// *************************************************************************** *
// *                                                                           *
// *                      Mentor Graphics Corporation                          *
// *                          All rights reserved                              *
// *                                                                           *
// *************************************************************************** *
// *                                                                           *
// * Description:         CANDB File                                           *
// * Generated at:        2020-12-11 06:44:08                                  *
// * System:              SDB20019                                             *
// * Variant:             DC1E                                                 *
// * Network:             BodyExposedCAN                                       *
// *                                                                           *
// *************************************************************************** *
// *                                                                           *
// *             THIS CONFIGURATION MIGHT CONTAIN SOME ERRORS                  *
// *              IF THE INPUT MODEL WAS NOT PROPERLY FORMED!                  *
// *                    Do Not Use this File directly!                         *
// *                                                                           *
// *************************************************************************** *
VERSION "BodyExposedCAN"

NS_ :

BS_:

BU_:  CEM ETC HCML HCMR RCML RCMM RCMR

BO_ 1322 CemBodyCanExposedNMFr: 8 CEM
 SG_ PNC16_CEM : 16|1@0+ (1,0) [0|0] "" RCMR
 SG_ PNC17_CEM : 17|1@0+ (1,0) [0|0] "" RCMR
 SG_ PNC18_CEM : 18|1@0+ (1,0) [0|0] "" RCMR
 SG_ PNC19_CEM : 19|1@0+ (1,0) [0|0] "" RCMR
 SG_ PNC20_CEM : 20|1@0+ (1,0) [0|0] "" RCMR
 SG_ PNC21_CEM : 21|1@0+ (1,0) [0|0] "" RCMR
 SG_ PNC22_CEM : 22|1@0+ (1,0) [0|0] "" RCMR
 SG_ PNC23_CEM : 23|1@0+ (1,0) [0|0] "" RCMR
 SG_ PNC24_CEM : 24|1@0+ (1,0) [0|0] "" RCMR
 SG_ PNC25_CEM : 25|1@0+ (1,0) [0|0] "" RCMR
 SG_ PNC26_CEM : 26|1@0+ (1,0) [0|0] "" RCMR
 SG_ PNC27_CEM : 27|1@0+ (1,0) [0|0] "" RCMR
 SG_ PNC28_CEM : 28|1@0+ (1,0) [0|0] "" RCMR
 SG_ PNC29_CEM : 29|1@0+ (1,0) [0|0] "" RCMR
 SG_ PNC30_CEM : 30|1@0+ (1,0) [0|0] "" RCMR
 SG_ PNC31_CEM : 31|1@0+ (1,0) [0|0] "" RCMR
 SG_ PNC32_CEM : 32|1@0+ (1,0) [0|0] "" RCMR
 SG_ PNC33_CEM : 33|1@0+ (1,0) [0|0] "" RCMR
 SG_ PNC34_CEM : 34|1@0+ (1,0) [0|0] "" RCMR
 SG_ PNC35_CEM : 35|1@0+ (1,0) [0|0] "" RCMR
 SG_ PNC36_CEM : 36|1@0+ (1,0) [0|0] "" RCMR
 SG_ PNC37_CEM : 37|1@0+ (1,0) [0|0] "" RCMR
 SG_ PNC38_CEM : 38|1@0+ (1,0) [0|0] "" RCMR
 SG_ PNC39_CEM : 39|1@0+ (1,0) [0|0] "" RCMR
 SG_ NM_PNI_CEM : 14|1@0+ (1,0) [0|0] "" RCMR
 SG_ NM_AW_CEM : 12|1@0+ (1,0) [0|0] "" RCMR
 SG_ NM_CS_CEM : 11|1@0+ (1,0) [0|0] "" RCMR
 SG_ NM_RMR_CEM : 8|1@0+ (1,0) [0|0] "" RCMR
 SG_ NM_NodeID_CEM : 7|8@0+ (1,0) [0|0] "" RCMR

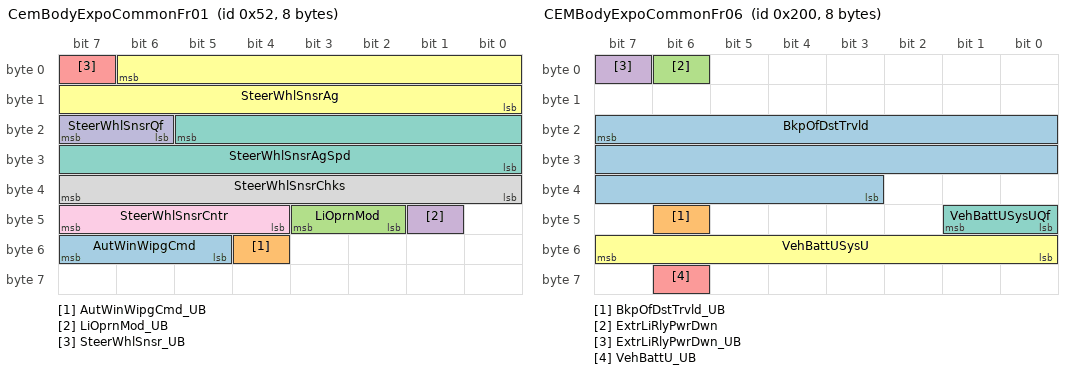
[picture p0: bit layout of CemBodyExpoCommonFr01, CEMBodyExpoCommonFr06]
BO_ 82 CemBodyExpoCommonFr01: 8 CEM
 SG_ AutWinWipgCmd : 55|3@0+ (1,0) [0|7] "" HCML,HCMR
 SG_ AutWinWipgCmd_UB : 52|1@0+ (1,0) [0|1] "" HCML,HCMR
 SG_ LiOprnMod : 43|2@0+ (1,0) [0|3] "" HCML,HCMR
 SG_ LiOprnMod_UB : 41|1@0+ (1,0) [0|1] "" HCML,HCMR
 SG_ SteerWhlSnsr_UB : 7|1@0+ (1,0) [0|1] "" HCML,HCMR
 SG_ SteerWhlSnsrAg : 6|15@0- (0.0009765625,0.0) [-14.5|14.5] "rad" HCML,HCMR
 SG_ SteerWhlSnsrAgSpd : 21|14@0- (0.0078125,0.0) [-50.0|50.0] "rad/s" HCML,HCMR
 SG_ SteerWhlSnsrChks : 39|8@0+ (1.0,0.0) [0.0|255.0] "Unitless" HCML,HCMR
 SG_ SteerWhlSnsrCntr : 47|4@0+ (1.0,0.0) [0.0|15.0] "Unitless" HCML,HCMR
 SG_ SteerWhlSnsrQf : 23|2@0+ (1,0) [0|3] "" HCML,HCMR

BO_ 768 CemBodyExpoCommonFr02: 8 CEM
 SG_ ActvnOfRvsg : 23|1@0+ (1,0) [0|1] "" RCML,RCMM,RCMR
 SG_ ActvnOfRvsg_UB : 22|1@0+ (1,0) [0|1] "" RCML,RCMM,RCMR
 SG_ YawRateReqdByDrvr : 7|16@0- (0.000244140625,0.0) [-5.0|5.0] "rad/s" HCML,HCMR
 SG_ YawRateReqdByDrvr_UB : 21|1@0+ (1,0) [0|1] "" HCML,HCMR

BO_ 80 CEMBodyExpoCommonFr04: 8 CEM
 SG_ VehSpdLgt_UB : 7|1@0+ (1,0) [0|1] "" HCML,HCMR,RCML,RCMM,RCMR
 SG_ VehSpdLgtA : 6|15@0+ (0.00391,0.0) [0.0|125.0027] "m/s" HCML,HCMR,RCML,RCMM,RCMR
 SG_ VehSpdLgtChks : 23|8@0+ (1.0,0.0) [0.0|255.0] "Unitless" HCML,HCMR,RCML,RCMM,RCMR
 SG_ VehSpdLgtCntr : 31|4@0+ (1.0,0.0) [0.0|15.0] "Unitless" HCML,HCMR,RCML,RCMM,RCMR
 SG_ VehSpdLgtQf : 27|2@0+ (1,0) [0|3] "" HCML,HCMR,RCML,RCMM,RCMR

BO_ 384 CemBodyExpoCommonFr05: 8 CEM
 SG_ VehCfgPrmBlkIDBytePosn1 : 7|8@0+ (1.0,0.0) [0.0|255.0] "Unitless" HCML,HCMR,RCML,RCMM,RCMR
 SG_ VehCfgPrmCCPBytePosn2 : 15|8@0+ (1.0,0.0) [0.0|255.0] "Unitless" HCML,HCMR,RCML,RCMM,RCMR
 SG_ VehCfgPrmCCPBytePosn3 : 23|8@0+ (1.0,0.0) [0.0|255.0] "Unitless" HCML,HCMR,RCML,RCMM,RCMR
 SG_ VehCfgPrmCCPBytePosn4 : 31|8@0+ (1.0,0.0) [0.0|255.0] "Unitless" HCML,HCMR,RCML,RCMM,RCMR
 SG_ VehCfgPrmCCPBytePosn5 : 39|8@0+ (1.0,0.0) [0.0|255.0] "Unitless" HCML,HCMR,RCML,RCMM,RCMR
 SG_ VehCfgPrmCCPBytePosn6 : 47|8@0+ (1.0,0.0) [0.0|255.0] "Unitless" HCML,HCMR,RCML,RCMM,RCMR
 SG_ VehCfgPrmCCPBytePosn7 : 55|8@0+ (1.0,0.0) [0.0|255.0] "Unitless" HCML,HCMR,RCML,RCMM,RCMR
 SG_ VehCfgPrmCCPBytePosn8 : 63|8@0+ (1.0,0.0) [0.0|255.0] "Unitless" HCML,HCMR,RCML,RCMM,RCMR

BO_ 512 CEMBodyExpoCommonFr06: 8 CEM
 SG_ BkpOfDstTrvld : 23|21@0+ (1.0,0.0) [0.0|2000000.0] "km" HCML,HCMR,RCML,RCMM,RCMR
 SG_ BkpOfDstTrvld_UB : 46|1@0+ (1,0) [0|1] "" HCML,HCMR,RCML,RCMM,RCMR
 SG_ ExtrLiRlyPwrDwn : 6|1@0+ (1,0) [0|1] "" HCML,HCMR
 SG_ ExtrLiRlyPwrDwn_UB : 7|1@0+ (1,0) [0|1] "" HCML,HCMR
 SG_ VehBattU_UB : 62|1@0+ (1,0) [0|1] "" HCML,HCMR,RCML,RCMM,RCMR
 SG_ VehBattUSysU : 55|8@0+ (0.1,0.0) [0.0|25.0] "Volt" HCML,HCMR,RCML,RCMM,RCMR
 SG_ VehBattUSysUQf : 41|2@0+ (1,0) [0|3] "" HCML,HCMR,RCML,RCMM,RCMR

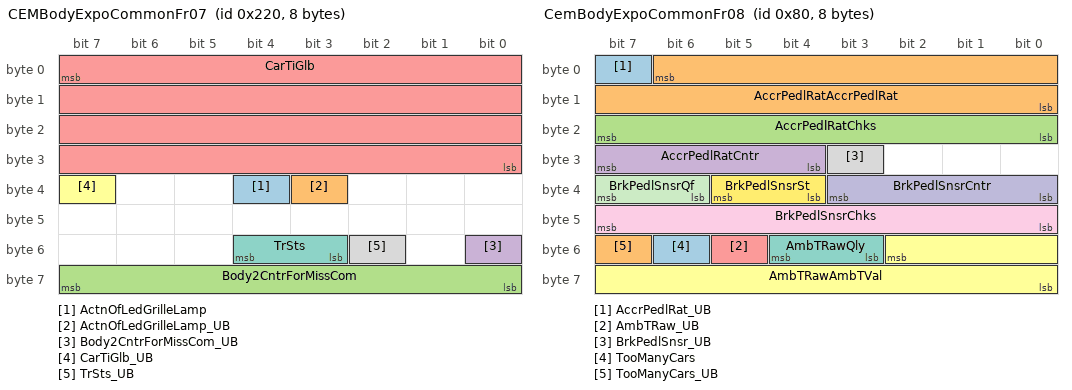
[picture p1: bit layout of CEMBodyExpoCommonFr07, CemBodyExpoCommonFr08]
BO_ 544 CEMBodyExpoCommonFr07: 8 CEM
 SG_ ActnOfLedGrilleLamp : 36|1@0+ (1,0) [0|1] "" HCML,HCMR
 SG_ ActnOfLedGrilleLamp_UB : 35|1@0+ (1,0) [0|1] "" HCML,HCMR
 SG_ Body2CntrForMissCom : 63|8@0+ (1.0,0.0) [0.0|255.0] "Unitless" HCML,HCMR
 SG_ Body2CntrForMissCom_UB : 48|1@0+ (1,0) [0|1] "" HCML,HCMR
 SG_ CarTiGlb : 7|32@0+ (0.1,0.0) [0.0|429496729.5] "s" HCML,HCMR,RCML,RCMM,RCMR
 SG_ CarTiGlb_UB : 39|1@0+ (1,0) [0|1] "" HCML,HCMR,RCML,RCMM,RCMR
 SG_ TrSts : 52|2@0+ (1,0) [0|3] "" RCML,RCMM,RCMR
 SG_ TrSts_UB : 50|1@0+ (1,0) [0|1] "" RCML,RCMM,RCMR

BO_ 128 CemBodyExpoCommonFr08: 8 CEM
 SG_ AccrPedlRat_UB : 7|1@0+ (1,0) [0|1] "" HCML,HCMR
 SG_ AccrPedlRatAccrPedlRat : 6|15@0+ (0.00390625,0.0) [0.0|100.0] "%" HCML,HCMR
 SG_ AccrPedlRatChks : 23|8@0+ (1.0,0.0) [0.0|255.0] "Unitless" HCML,HCMR
 SG_ AccrPedlRatCntr : 31|4@0+ (1.0,0.0) [0.0|15.0] "Unitless" HCML,HCMR
 SG_ AmbTRaw_UB : 53|1@0+ (1,0) [0|1] "" HCML,HCMR
 SG_ AmbTRawAmbTVal : 50|11@0+ (0.1,-70.0) [-70.0|134.70000000000002] "degC" HCML,HCMR
 SG_ AmbTRawQly : 52|2@0+ (1,0) [0|3] "" HCML,HCMR
 SG_ BrkPedlSnsr_UB : 27|1@0+ (1,0) [0|1] "" HCML,HCMR
 SG_ BrkPedlSnsrChks : 47|8@0+ (1.0,0.0) [0.0|255.0] "Unitless" HCML,HCMR
 SG_ BrkPedlSnsrCntr : 35|4@0+ (1.0,0.0) [0.0|15.0] "Unitless" HCML,HCMR
 SG_ BrkPedlSnsrQf : 39|2@0+ (1,0) [0|3] "" HCML,HCMR
 SG_ BrkPedlSnsrSt : 37|2@0+ (1,0) [0|3] "" HCML,HCMR
 SG_ TooManyCars : 54|1@0+ (1,0) [0|1] "" HCML,HCMR
 SG_ TooManyCars_UB : 55|1@0+ (1,0) [0|1] "" HCML,HCMR

BO_ 387 CemBodyExpoCommonFr09: 8 CEM
 SG_ VehCfgPrmExtBlkIDBytePosn1 : 7|8@0+ (1.0,0.0) [0.0|255.0] "Unitless" HCML,HCMR,RCML,RCMM,RCMR
 SG_ VehCfgPrmExtCCPBytePosn2 : 15|8@0+ (1.0,0.0) [0.0|255.0] "Unitless" HCML,HCMR,RCML,RCMM,RCMR
 SG_ VehCfgPrmExtCCPBytePosn3 : 23|8@0+ (1.0,0.0) [0.0|255.0] "Unitless" HCML,HCMR,RCML,RCMM,RCMR
 SG_ VehCfgPrmExtCCPBytePosn4 : 31|8@0+ (1.0,0.0) [0.0|255.0] "Unitless" HCML,HCMR,RCML,RCMM,RCMR
 SG_ VehCfgPrmExtCCPBytePosn5 : 39|8@0+ (1.0,0.0) [0.0|255.0] "Unitless" HCML,HCMR,RCML,RCMM,RCMR
 SG_ VehCfgPrmExtCCPBytePosn6 : 47|8@0+ (1.0,0.0) [0.0|255.0] "Unitless" HCML,HCMR,RCML,RCMM,RCMR
 SG_ VehCfgPrmExtCCPBytePosn7 : 55|8@0+ (1.0,0.0) [0.0|255.0] "Unitless" HCML,HCMR,RCML,RCMM,RCMR
 SG_ VehCfgPrmExtCCPBytePosn8 : 63|8@0+ (1.0,0.0) [0.0|255.0] "Unitless" HCML,HCMR,RCML,RCMM,RCMR

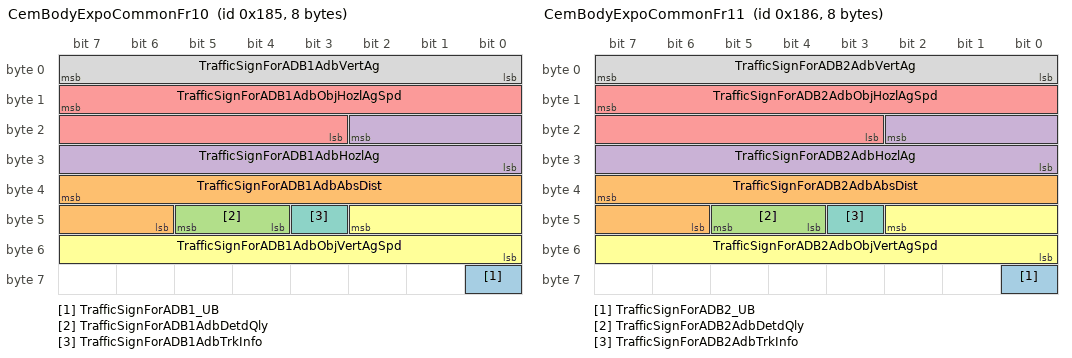
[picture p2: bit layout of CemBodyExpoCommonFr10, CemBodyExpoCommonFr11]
BO_ 389 CemBodyExpoCommonFr10: 8 CEM
 SG_ TrafficSignForADB1_UB : 56|1@0+ (1,0) [0|1] "" HCML,HCMR
 SG_ TrafficSignForADB1AdbAbsDist : 39|10@0+ (1.0,0.0) [0.0|1000.0] "m" HCML,HCMR
 SG_ TrafficSignForADB1AdbDetdQly : 45|2@0+ (1,0) [0|3] "" HCML,HCMR
 SG_ TrafficSignForADB1AdbHozlAg : 18|11@0+ (0.05,-40.0) [-40.0|40.0] "Deg" HCML,HCMR
 SG_ TrafficSignForADB1AdbObjHozlAgSpd : 15|13@0+ (0.05,-144.0) [-144.0|144.0] "DegPerSec" HCML,HCMR
 SG_ TrafficSignForADB1AdbObjVertAgSpd : 42|11@0+ (0.2,-144.0) [-144.0|144.0] "DegPerSec" HCML,HCMR
 SG_ TrafficSignForADB1AdbTrkInfo : 43|1@0+ (1,0) [0|1] "" HCML,HCMR
 SG_ TrafficSignForADB1AdbVertAg : 7|8@0+ (0.2,-15.0) [-15.0|15.0] "Deg" HCML,HCMR

BO_ 390 CemBodyExpoCommonFr11: 8 CEM
 SG_ TrafficSignForADB2_UB : 56|1@0+ (1,0) [0|1] "" HCML,HCMR
 SG_ TrafficSignForADB2AdbAbsDist : 39|10@0+ (1.0,0.0) [0.0|1000.0] "m" HCML,HCMR
 SG_ TrafficSignForADB2AdbDetdQly : 45|2@0+ (1,0) [0|3] "" HCML,HCMR
 SG_ TrafficSignForADB2AdbHozlAg : 18|11@0+ (0.05,-40.0) [-40.0|40.0] "Deg" HCML,HCMR
 SG_ TrafficSignForADB2AdbObjHozlAgSpd : 15|13@0+ (0.05,-144.0) [-144.0|144.0] "DegPerSec" HCML,HCMR
 SG_ TrafficSignForADB2AdbObjVertAgSpd : 42|11@0+ (0.2,-144.0) [-144.0|144.0] "DegPerSec" HCML,HCMR
 SG_ TrafficSignForADB2AdbTrkInfo : 43|1@0+ (1,0) [0|1] "" HCML,HCMR
 SG_ TrafficSignForADB2AdbVertAg : 7|8@0+ (0.2,-15.0) [-15.0|15.0] "Deg" HCML,HCMR

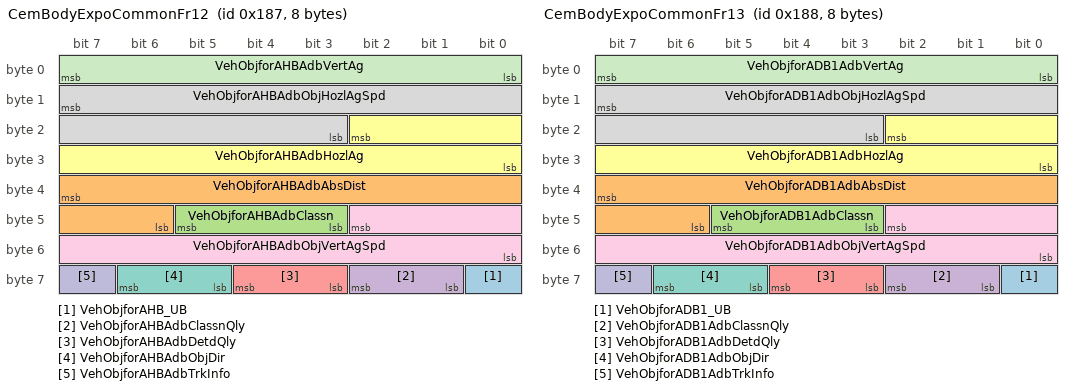
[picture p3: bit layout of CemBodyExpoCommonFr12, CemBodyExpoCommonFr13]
BO_ 391 CemBodyExpoCommonFr12: 8 CEM
 SG_ VehObjforAHB_UB : 56|1@0+ (1,0) [0|1] "" HCML,HCMR
 SG_ VehObjforAHBAdbAbsDist : 39|10@0+ (1.0,0.0) [0.0|1000.0] "m" HCML,HCMR
 SG_ VehObjforAHBAdbClassn : 45|3@0+ (1,0) [0|7] "" HCML,HCMR
 SG_ VehObjforAHBAdbClassnQly : 58|2@0+ (1,0) [0|3] "" HCML,HCMR
 SG_ VehObjforAHBAdbDetdQly : 60|2@0+ (1,0) [0|3] "" HCML,HCMR
 SG_ VehObjforAHBAdbHozlAg : 18|11@0+ (0.05,-40.0) [-40.0|40.0] "Deg" HCML,HCMR
 SG_ VehObjforAHBAdbObjDir : 62|2@0+ (1,0) [0|3] "" HCML,HCMR
 SG_ VehObjforAHBAdbObjHozlAgSpd : 15|13@0+ (0.05,-144.0) [-144.0|144.0] "DegPerSec" HCML,HCMR
 SG_ VehObjforAHBAdbObjVertAgSpd : 42|11@0+ (0.2,-144.0) [-144.0|144.0] "DegPerSec" HCML,HCMR
 SG_ VehObjforAHBAdbTrkInfo : 63|1@0+ (1,0) [0|1] "" HCML,HCMR
 SG_ VehObjforAHBAdbVertAg : 7|8@0+ (0.2,-15.0) [-15.0|15.0] "Deg" HCML,HCMR

BO_ 392 CemBodyExpoCommonFr13: 8 CEM
 SG_ VehObjforADB1_UB : 56|1@0+ (1,0) [0|1] "" HCML,HCMR
 SG_ VehObjforADB1AdbAbsDist : 39|10@0+ (1.0,0.0) [0.0|1000.0] "m" HCML,HCMR
 SG_ VehObjforADB1AdbClassn : 45|3@0+ (1,0) [0|7] "" HCML,HCMR
 SG_ VehObjforADB1AdbClassnQly : 58|2@0+ (1,0) [0|3] "" HCML,HCMR
 SG_ VehObjforADB1AdbDetdQly : 60|2@0+ (1,0) [0|3] "" HCML,HCMR
 SG_ VehObjforADB1AdbHozlAg : 18|11@0+ (0.05,-40.0) [-40.0|40.0] "Deg" HCML,HCMR
 SG_ VehObjforADB1AdbObjDir : 62|2@0+ (1,0) [0|3] "" HCML,HCMR
 SG_ VehObjforADB1AdbObjHozlAgSpd : 15|13@0+ (0.05,-144.0) [-144.0|144.0] "DegPerSec" HCML,HCMR
 SG_ VehObjforADB1AdbObjVertAgSpd : 42|11@0+ (0.2,-144.0) [-144.0|144.0] "DegPerSec" HCML,HCMR
 SG_ VehObjforADB1AdbTrkInfo : 63|1@0+ (1,0) [0|1] "" HCML,HCMR
 SG_ VehObjforADB1AdbVertAg : 7|8@0+ (0.2,-15.0) [-15.0|15.0] "Deg" HCML,HCMR

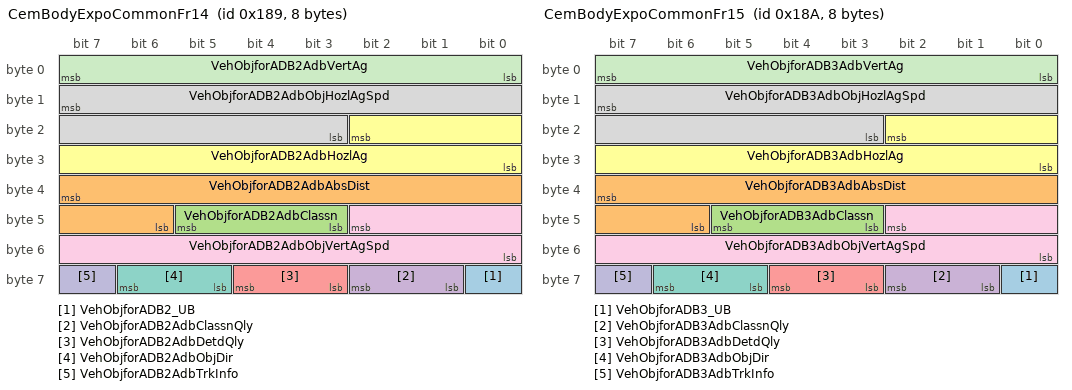
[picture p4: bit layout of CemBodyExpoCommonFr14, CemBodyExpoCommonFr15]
BO_ 393 CemBodyExpoCommonFr14: 8 CEM
 SG_ VehObjforADB2_UB : 56|1@0+ (1,0) [0|1] "" HCML,HCMR
 SG_ VehObjforADB2AdbAbsDist : 39|10@0+ (1.0,0.0) [0.0|1000.0] "m" HCML,HCMR
 SG_ VehObjforADB2AdbClassn : 45|3@0+ (1,0) [0|7] "" HCML,HCMR
 SG_ VehObjforADB2AdbClassnQly : 58|2@0+ (1,0) [0|3] "" HCML,HCMR
 SG_ VehObjforADB2AdbDetdQly : 60|2@0+ (1,0) [0|3] "" HCML,HCMR
 SG_ VehObjforADB2AdbHozlAg : 18|11@0+ (0.05,-40.0) [-40.0|40.0] "Deg" HCML,HCMR
 SG_ VehObjforADB2AdbObjDir : 62|2@0+ (1,0) [0|3] "" HCML,HCMR
 SG_ VehObjforADB2AdbObjHozlAgSpd : 15|13@0+ (0.05,-144.0) [-144.0|144.0] "DegPerSec" HCML,HCMR
 SG_ VehObjforADB2AdbObjVertAgSpd : 42|11@0+ (0.2,-144.0) [-144.0|144.0] "DegPerSec" HCML,HCMR
 SG_ VehObjforADB2AdbTrkInfo : 63|1@0+ (1,0) [0|1] "" HCML,HCMR
 SG_ VehObjforADB2AdbVertAg : 7|8@0+ (0.2,-15.0) [-15.0|15.0] "Deg" HCML,HCMR

BO_ 394 CemBodyExpoCommonFr15: 8 CEM
 SG_ VehObjforADB3_UB : 56|1@0+ (1,0) [0|1] "" HCML,HCMR
 SG_ VehObjforADB3AdbAbsDist : 39|10@0+ (1.0,0.0) [0.0|1000.0] "m" HCML,HCMR
 SG_ VehObjforADB3AdbClassn : 45|3@0+ (1,0) [0|7] "" HCML,HCMR
 SG_ VehObjforADB3AdbClassnQly : 58|2@0+ (1,0) [0|3] "" HCML,HCMR
 SG_ VehObjforADB3AdbDetdQly : 60|2@0+ (1,0) [0|3] "" HCML,HCMR
 SG_ VehObjforADB3AdbHozlAg : 18|11@0+ (0.05,-40.0) [-40.0|40.0] "Deg" HCML,HCMR
 SG_ VehObjforADB3AdbObjDir : 62|2@0+ (1,0) [0|3] "" HCML,HCMR
 SG_ VehObjforADB3AdbObjHozlAgSpd : 15|13@0+ (0.05,-144.0) [-144.0|144.0] "DegPerSec" HCML,HCMR
 SG_ VehObjforADB3AdbObjVertAgSpd : 42|11@0+ (0.2,-144.0) [-144.0|144.0] "DegPerSec" HCML,HCMR
 SG_ VehObjforADB3AdbTrkInfo : 63|1@0+ (1,0) [0|1] "" HCML,HCMR
 SG_ VehObjforADB3AdbVertAg : 7|8@0+ (0.2,-15.0) [-15.0|15.0] "Deg" HCML,HCMR

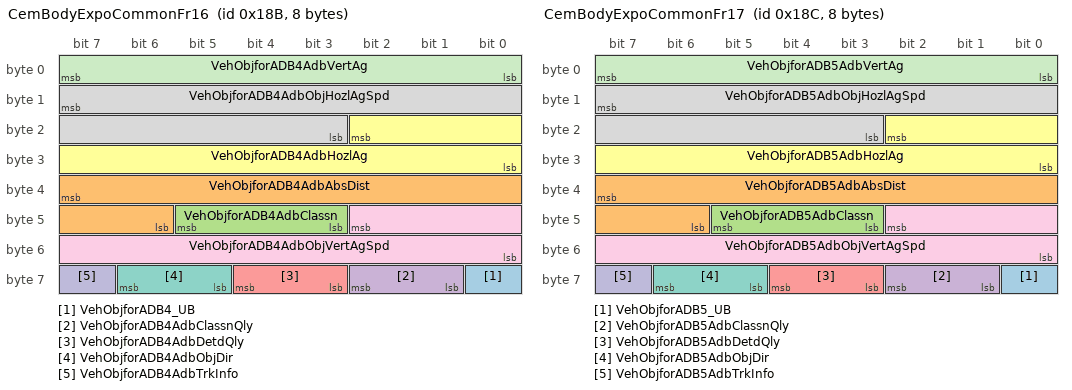
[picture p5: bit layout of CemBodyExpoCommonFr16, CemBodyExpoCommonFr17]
BO_ 395 CemBodyExpoCommonFr16: 8 CEM
 SG_ VehObjforADB4_UB : 56|1@0+ (1,0) [0|1] "" HCML,HCMR
 SG_ VehObjforADB4AdbAbsDist : 39|10@0+ (1.0,0.0) [0.0|1000.0] "m" HCML,HCMR
 SG_ VehObjforADB4AdbClassn : 45|3@0+ (1,0) [0|7] "" HCML,HCMR
 SG_ VehObjforADB4AdbClassnQly : 58|2@0+ (1,0) [0|3] "" HCML,HCMR
 SG_ VehObjforADB4AdbDetdQly : 60|2@0+ (1,0) [0|3] "" HCML,HCMR
 SG_ VehObjforADB4AdbHozlAg : 18|11@0+ (0.05,-40.0) [-40.0|40.0] "Deg" HCML,HCMR
 SG_ VehObjforADB4AdbObjDir : 62|2@0+ (1,0) [0|3] "" HCML,HCMR
 SG_ VehObjforADB4AdbObjHozlAgSpd : 15|13@0+ (0.05,-144.0) [-144.0|144.0] "DegPerSec" HCML,HCMR
 SG_ VehObjforADB4AdbObjVertAgSpd : 42|11@0+ (0.2,-144.0) [-144.0|144.0] "DegPerSec" HCML,HCMR
 SG_ VehObjforADB4AdbTrkInfo : 63|1@0+ (1,0) [0|1] "" HCML,HCMR
 SG_ VehObjforADB4AdbVertAg : 7|8@0+ (0.2,-15.0) [-15.0|15.0] "Deg" HCML,HCMR

BO_ 396 CemBodyExpoCommonFr17: 8 CEM
 SG_ VehObjforADB5_UB : 56|1@0+ (1,0) [0|1] "" HCML,HCMR
 SG_ VehObjforADB5AdbAbsDist : 39|10@0+ (1.0,0.0) [0.0|1000.0] "m" HCML,HCMR
 SG_ VehObjforADB5AdbClassn : 45|3@0+ (1,0) [0|7] "" HCML,HCMR
 SG_ VehObjforADB5AdbClassnQly : 58|2@0+ (1,0) [0|3] "" HCML,HCMR
 SG_ VehObjforADB5AdbDetdQly : 60|2@0+ (1,0) [0|3] "" HCML,HCMR
 SG_ VehObjforADB5AdbHozlAg : 18|11@0+ (0.05,-40.0) [-40.0|40.0] "Deg" HCML,HCMR
 SG_ VehObjforADB5AdbObjDir : 62|2@0+ (1,0) [0|3] "" HCML,HCMR
 SG_ VehObjforADB5AdbObjHozlAgSpd : 15|13@0+ (0.05,-144.0) [-144.0|144.0] "DegPerSec" HCML,HCMR
 SG_ VehObjforADB5AdbObjVertAgSpd : 42|11@0+ (0.2,-144.0) [-144.0|144.0] "DegPerSec" HCML,HCMR
 SG_ VehObjforADB5AdbTrkInfo : 63|1@0+ (1,0) [0|1] "" HCML,HCMR
 SG_ VehObjforADB5AdbVertAg : 7|8@0+ (0.2,-15.0) [-15.0|15.0] "Deg" HCML,HCMR

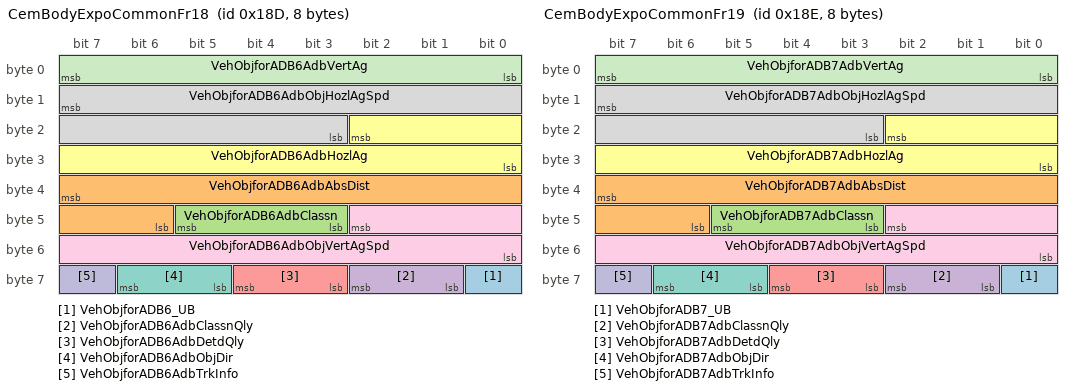
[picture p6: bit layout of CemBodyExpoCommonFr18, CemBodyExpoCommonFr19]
BO_ 397 CemBodyExpoCommonFr18: 8 CEM
 SG_ VehObjforADB6_UB : 56|1@0+ (1,0) [0|1] "" HCML,HCMR
 SG_ VehObjforADB6AdbAbsDist : 39|10@0+ (1.0,0.0) [0.0|1000.0] "m" HCML,HCMR
 SG_ VehObjforADB6AdbClassn : 45|3@0+ (1,0) [0|7] "" HCML,HCMR
 SG_ VehObjforADB6AdbClassnQly : 58|2@0+ (1,0) [0|3] "" HCML,HCMR
 SG_ VehObjforADB6AdbDetdQly : 60|2@0+ (1,0) [0|3] "" HCML,HCMR
 SG_ VehObjforADB6AdbHozlAg : 18|11@0+ (0.05,-40.0) [-40.0|40.0] "Deg" HCML,HCMR
 SG_ VehObjforADB6AdbObjDir : 62|2@0+ (1,0) [0|3] "" HCML,HCMR
 SG_ VehObjforADB6AdbObjHozlAgSpd : 15|13@0+ (0.05,-144.0) [-144.0|144.0] "DegPerSec" HCML,HCMR
 SG_ VehObjforADB6AdbObjVertAgSpd : 42|11@0+ (0.2,-144.0) [-144.0|144.0] "DegPerSec" HCML,HCMR
 SG_ VehObjforADB6AdbTrkInfo : 63|1@0+ (1,0) [0|1] "" HCML,HCMR
 SG_ VehObjforADB6AdbVertAg : 7|8@0+ (0.2,-15.0) [-15.0|15.0] "Deg" HCML,HCMR

BO_ 398 CemBodyExpoCommonFr19: 8 CEM
 SG_ VehObjforADB7_UB : 56|1@0+ (1,0) [0|1] "" HCML,HCMR
 SG_ VehObjforADB7AdbAbsDist : 39|10@0+ (1.0,0.0) [0.0|1000.0] "m" HCML,HCMR
 SG_ VehObjforADB7AdbClassn : 45|3@0+ (1,0) [0|7] "" HCML,HCMR
 SG_ VehObjforADB7AdbClassnQly : 58|2@0+ (1,0) [0|3] "" HCML,HCMR
 SG_ VehObjforADB7AdbDetdQly : 60|2@0+ (1,0) [0|3] "" HCML,HCMR
 SG_ VehObjforADB7AdbHozlAg : 18|11@0+ (0.05,-40.0) [-40.0|40.0] "Deg" HCML,HCMR
 SG_ VehObjforADB7AdbObjDir : 62|2@0+ (1,0) [0|3] "" HCML,HCMR
 SG_ VehObjforADB7AdbObjHozlAgSpd : 15|13@0+ (0.05,-144.0) [-144.0|144.0] "DegPerSec" HCML,HCMR
 SG_ VehObjforADB7AdbObjVertAgSpd : 42|11@0+ (0.2,-144.0) [-144.0|144.0] "DegPerSec" HCML,HCMR
 SG_ VehObjforADB7AdbTrkInfo : 63|1@0+ (1,0) [0|1] "" HCML,HCMR
 SG_ VehObjforADB7AdbVertAg : 7|8@0+ (0.2,-15.0) [-15.0|15.0] "Deg" HCML,HCMR

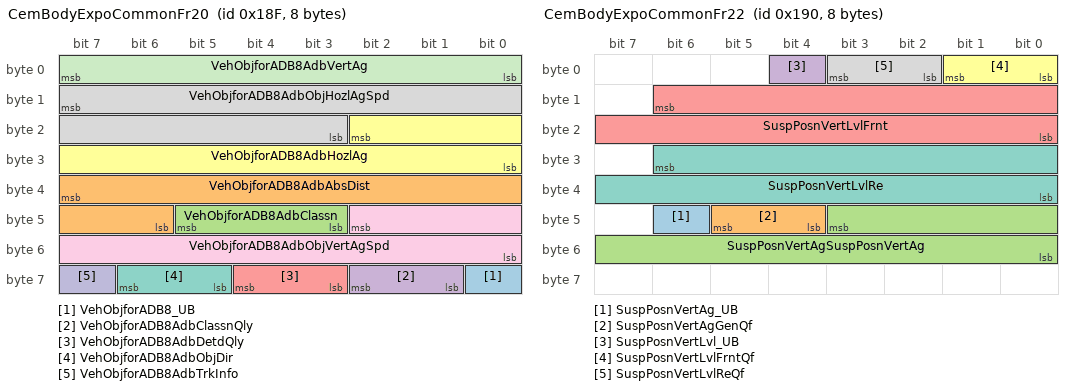
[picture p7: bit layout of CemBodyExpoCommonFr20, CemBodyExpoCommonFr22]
BO_ 399 CemBodyExpoCommonFr20: 8 CEM
 SG_ VehObjforADB8_UB : 56|1@0+ (1,0) [0|1] "" HCML,HCMR
 SG_ VehObjforADB8AdbAbsDist : 39|10@0+ (1.0,0.0) [0.0|1000.0] "m" HCML,HCMR
 SG_ VehObjforADB8AdbClassn : 45|3@0+ (1,0) [0|7] "" HCML,HCMR
 SG_ VehObjforADB8AdbClassnQly : 58|2@0+ (1,0) [0|3] "" HCML,HCMR
 SG_ VehObjforADB8AdbDetdQly : 60|2@0+ (1,0) [0|3] "" HCML,HCMR
 SG_ VehObjforADB8AdbHozlAg : 18|11@0+ (0.05,-40.0) [-40.0|40.0] "Deg" HCML,HCMR
 SG_ VehObjforADB8AdbObjDir : 62|2@0+ (1,0) [0|3] "" HCML,HCMR
 SG_ VehObjforADB8AdbObjHozlAgSpd : 15|13@0+ (0.05,-144.0) [-144.0|144.0] "DegPerSec" HCML,HCMR
 SG_ VehObjforADB8AdbObjVertAgSpd : 42|11@0+ (0.2,-144.0) [-144.0|144.0] "DegPerSec" HCML,HCMR
 SG_ VehObjforADB8AdbTrkInfo : 63|1@0+ (1,0) [0|1] "" HCML,HCMR
 SG_ VehObjforADB8AdbVertAg : 7|8@0+ (0.2,-15.0) [-15.0|15.0] "Deg" HCML,HCMR

BO_ 64 CemBodyExpoCommonFr21: 8 CEM
 SG_ CameraStsforAHBC : 62|2@0+ (1,0) [0|3] "" HCML,HCMR
 SG_ CameraStsforAHBC_UB : 60|1@0+ (1,0) [0|1] "" HCML,HCMR
 SG_ RainLi : 47|1@0+ (1,0) [0|1] "" HCML,HCMR
 SG_ RainLi_UB : 63|1@0+ (1,0) [0|1] "" HCML,HCMR
 SG_ VehModMngtGlbSafe1_UB : 32|1@0+ (1,0) [0|1] "" HCML,HCMR,RCML,RCMM,RCMR
 SG_ VehModMngtGlbSafe1CarModSts1 : 39|3@0+ (1,0) [0|7] "" HCML,HCMR,RCML,RCMM,RCMR
 SG_ VehModMngtGlbSafe1CarModSubtypWdCarModSubtyp : 35|3@0+ (1.0,0.0) [0.0|7.0] "Unitless" HCML,HCMR,RCML,RCMM,RCMR
 SG_ VehModMngtGlbSafe1Chks : 7|8@0+ (1.0,0.0) [0.0|255.0] "Unitless" HCML,HCMR,RCML,RCMM,RCMR
 SG_ VehModMngtGlbSafe1Cntr : 15|4@0+ (1.0,0.0) [0.0|15.0] "Unitless" HCML,HCMR,RCML,RCMM,RCMR
 SG_ VehModMngtGlbSafe1EgyLvlElecMai : 27|4@0+ (1.0,0.0) [0.0|15.0] "Unitless" HCML,HCMR,RCML,RCMM,RCMR
 SG_ VehModMngtGlbSafe1EgyLvlElecSubtyp : 31|4@0+ (1.0,0.0) [0.0|15.0] "Unitless" HCML,HCMR,RCML,RCMM,RCMR
 SG_ VehModMngtGlbSafe1FltEgyCnsWdSts : 36|1@0+ (1,0) [0|1] "" HCML,HCMR,RCML,RCMM,RCMR
 SG_ VehModMngtGlbSafe1PwrLvlElecMai : 19|4@0+ (1.0,0.0) [0.0|15.0] "Unitless" HCML,HCMR,RCML,RCMM,RCMR
 SG_ VehModMngtGlbSafe1PwrLvlElecSubtyp : 23|4@0+ (1.0,0.0) [0.0|15.0] "Unitless" HCML,HCMR,RCML,RCMM,RCMR
 SG_ VehModMngtGlbSafe1UsgModSts : 11|4@0+ (1,0) [0|15] "" HCML,HCMR,RCML,RCMM,RCMR
 SG_ WipgAutFrntMod : 59|2@0+ (1,0) [0|3] "" HCML,HCMR
 SG_ WipgAutFrntMod_UB : 57|1@0+ (1,0) [0|1] "" HCML,HCMR

BO_ 400 CemBodyExpoCommonFr22: 8 CEM
 SG_ SuspPosnVertAg_UB : 46|1@0+ (1,0) [0|1] "" HCML,HCMR
 SG_ SuspPosnVertAgGenQf : 45|2@0+ (1,0) [0|3] "" HCML,HCMR
 SG_ SuspPosnVertAgSuspPosnVertAg : 43|12@0- (0.000127894181,0.0) [-0.26167149432599995|0.26179938850699996] "rad" HCML,HCMR
 SG_ SuspPosnVertLvl_UB : 4|1@0+ (1,0) [0|1] "" HCML,HCMR
 SG_ SuspPosnVertLvlFrnt : 14|15@0- (0.000062,0.0) [-0.999998|1.00006] "m" HCML,HCMR
 SG_ SuspPosnVertLvlFrntQf : 1|2@0+ (1,0) [0|3] "" HCML,HCMR
 SG_ SuspPosnVertLvlRe : 30|15@0- (0.000062,0.0) [-0.999998|1.00006] "m" HCML,HCMR
 SG_ SuspPosnVertLvlReQf : 3|2@0+ (1,0) [0|3] "" HCML,HCMR

BO_ 1432 CemBodyExpoDevDiagFr01: 8 CEM
 SG_ CEMdevelpsignalgrouprespFunctiondevpsignalgroup1 : 7|8@0+ (1.0,0.0) [0.0|255.0] "Unitless" ETC
 SG_ CEMdevelpsignalgrouprespFunctiondevpsignalgroup2 : 15|8@0+ (1.0,0.0) [0.0|255.0] "Unitless" ETC
 SG_ CEMdevelpsignalgrouprespFunctiondevpsignalgroup3 : 23|8@0+ (1.0,0.0) [0.0|255.0] "Unitless" ETC
 SG_ CEMdevelpsignalgrouprespFunctiondevpsignalgroup4 : 31|8@0+ (1.0,0.0) [0.0|255.0] "Unitless" ETC
 SG_ CEMdevelpsignalgrouprespFunctiondevpsignalgroup5 : 39|8@0+ (1.0,0.0) [0.0|255.0] "Unitless" ETC
 SG_ CEMdevelpsignalgrouprespFunctiondevpsignalgroup6 : 47|8@0+ (1.0,0.0) [0.0|255.0] "Unitless" ETC
 SG_ CEMdevelpsignalgrouprespFunctiondevpsignalgroup7 : 55|8@0+ (1.0,0.0) [0.0|255.0] "Unitless" ETC
 SG_ CEMdevelpsignalgrouprespFunctiondevpsignalgroup8 : 63|8@0+ (1.0,0.0) [0.0|255.0] "Unitless" ETC

BO_ 1431 CemBodyExpoDevFr02: 8 CEM
 SG_ CEMdevelpsignalgroupcheckFunctiondevpsignalgroup1 : 7|8@0+ (1.0,0.0) [0.0|255.0] "Unitless" ETC
 SG_ CEMdevelpsignalgroupcheckFunctiondevpsignalgroup2 : 15|8@0+ (1.0,0.0) [0.0|255.0] "Unitless" ETC
 SG_ CEMdevelpsignalgroupcheckFunctiondevpsignalgroup3 : 23|8@0+ (1.0,0.0) [0.0|255.0] "Unitless" ETC
 SG_ CEMdevelpsignalgroupcheckFunctiondevpsignalgroup4 : 31|8@0+ (1.0,0.0) [0.0|255.0] "Unitless" ETC
 SG_ CEMdevelpsignalgroupcheckFunctiondevpsignalgroup5 : 39|8@0+ (1.0,0.0) [0.0|255.0] "Unitless" ETC
 SG_ CEMdevelpsignalgroupcheckFunctiondevpsignalgroup6 : 47|8@0+ (1.0,0.0) [0.0|255.0] "Unitless" ETC
 SG_ CEMdevelpsignalgroupcheckFunctiondevpsignalgroup7 : 55|8@0+ (1.0,0.0) [0.0|255.0] "Unitless" ETC
 SG_ CEMdevelpsignalgroupcheckFunctiondevpsignalgroup8 : 63|8@0+ (1.0,0.0) [0.0|255.0] "Unitless" ETC

BO_ 28 CemBodyExpoFr01: 8 CEM
 SG_ ExtrLiShowActvnReq : 44|1@0+ (1,0) [0|1] "" HCML,HCMR,RCML,RCMM,RCMR
 SG_ ExtrLiShowActvnReq_UB : 43|1@0+ (1,0) [0|1] "" HCML,HCMR,RCML,RCMM,RCMR
 SG_ ExtrLiShowFileTxReq : 42|1@0+ (1,0) [0|1] "" HCML,HCMR,RCML,RCMM,RCMR
 SG_ ExtrLiShowFileTxReq_UB : 41|1@0+ (1,0) [0|1] "" HCML,HCMR,RCML,RCMM,RCMR

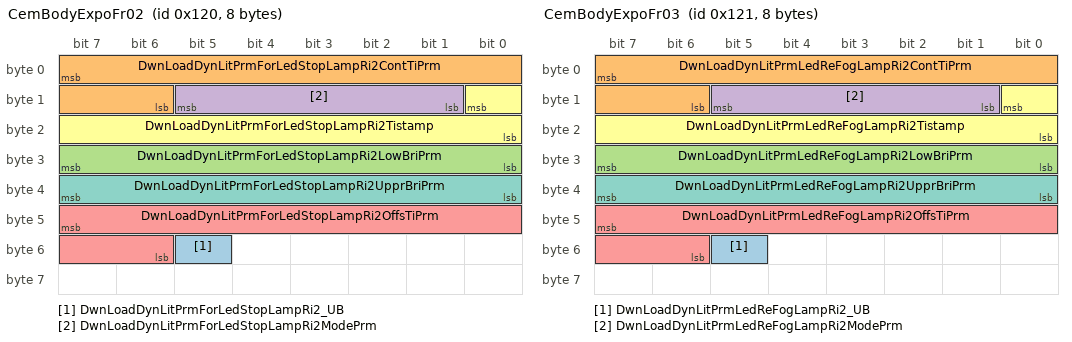
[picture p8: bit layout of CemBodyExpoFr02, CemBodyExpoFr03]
BO_ 288 CemBodyExpoFr02: 8 CEM
 SG_ DwnLoadDynLitPrmForLedStopLampRi2_UB : 53|1@0+ (1,0) [0|1] "" RCMM
 SG_ DwnLoadDynLitPrmForLedStopLampRi2ContTiPrm : 7|10@0+ (1.0,0.0) [0.0|1000.0] "Milliseconds" RCMM
 SG_ DwnLoadDynLitPrmForLedStopLampRi2LowBriPrm : 31|8@0+ (1.0,0.0) [0.0|100.0] "%" RCMM
 SG_ DwnLoadDynLitPrmForLedStopLampRi2ModePrm : 13|5@0+ (1,0) [0|31] "" RCMM
 SG_ DwnLoadDynLitPrmForLedStopLampRi2OffsTiPrm : 47|10@0+ (1.0,0.0) [0.0|1000.0] "Milliseconds" RCMM
 SG_ DwnLoadDynLitPrmForLedStopLampRi2Tistamp : 8|9@0+ (1.0,0.0) [0.0|511.0] "Unitless" RCMM
 SG_ DwnLoadDynLitPrmForLedStopLampRi2UpprBriPrm : 39|8@0+ (1.0,0.0) [0.0|100.0] "%" RCMM

BO_ 289 CemBodyExpoFr03: 8 CEM
 SG_ DwnLoadDynLitPrmLedReFogLampRi2_UB : 53|1@0+ (1,0) [0|1] "" RCMM
 SG_ DwnLoadDynLitPrmLedReFogLampRi2ContTiPrm : 7|10@0+ (1.0,0.0) [0.0|1000.0] "Milliseconds" RCMM
 SG_ DwnLoadDynLitPrmLedReFogLampRi2LowBriPrm : 31|8@0+ (1.0,0.0) [0.0|100.0] "%" RCMM
 SG_ DwnLoadDynLitPrmLedReFogLampRi2ModePrm : 13|5@0+ (1,0) [0|31] "" RCMM
 SG_ DwnLoadDynLitPrmLedReFogLampRi2OffsTiPrm : 47|10@0+ (1.0,0.0) [0.0|1000.0] "Milliseconds" RCMM
 SG_ DwnLoadDynLitPrmLedReFogLampRi2Tistamp : 8|9@0+ (1.0,0.0) [0.0|511.0] "Unitless" RCMM
 SG_ DwnLoadDynLitPrmLedReFogLampRi2UpprBriPrm : 39|8@0+ (1.0,0.0) [0.0|100.0] "%" RCMM

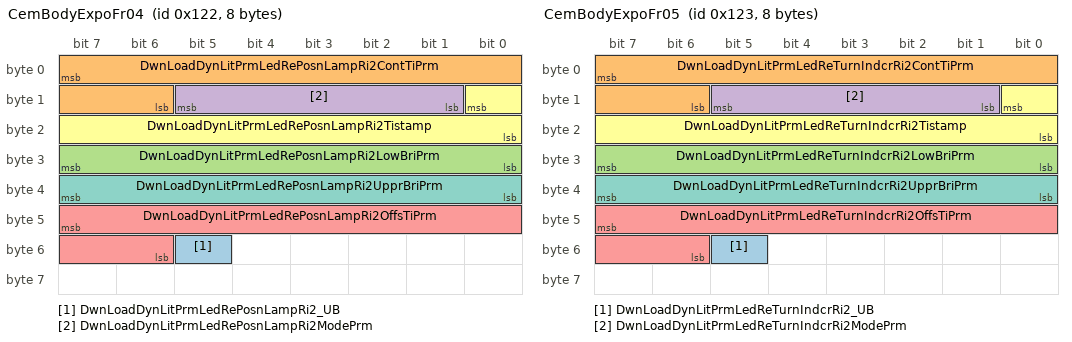
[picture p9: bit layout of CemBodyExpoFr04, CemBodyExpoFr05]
BO_ 290 CemBodyExpoFr04: 8 CEM
 SG_ DwnLoadDynLitPrmLedRePosnLampRi2_UB : 53|1@0+ (1,0) [0|1] "" RCMM
 SG_ DwnLoadDynLitPrmLedRePosnLampRi2ContTiPrm : 7|10@0+ (1.0,0.0) [0.0|1000.0] "Milliseconds" RCMM
 SG_ DwnLoadDynLitPrmLedRePosnLampRi2LowBriPrm : 31|8@0+ (1.0,0.0) [0.0|100.0] "%" RCMM
 SG_ DwnLoadDynLitPrmLedRePosnLampRi2ModePrm : 13|5@0+ (1,0) [0|31] "" RCMM
 SG_ DwnLoadDynLitPrmLedRePosnLampRi2OffsTiPrm : 47|10@0+ (1.0,0.0) [0.0|1000.0] "Milliseconds" RCMM
 SG_ DwnLoadDynLitPrmLedRePosnLampRi2Tistamp : 8|9@0+ (1.0,0.0) [0.0|511.0] "Unitless" RCMM
 SG_ DwnLoadDynLitPrmLedRePosnLampRi2UpprBriPrm : 39|8@0+ (1.0,0.0) [0.0|100.0] "%" RCMM

BO_ 291 CemBodyExpoFr05: 8 CEM
 SG_ DwnLoadDynLitPrmLedReTurnIndcrRi2_UB : 53|1@0+ (1,0) [0|1] "" RCMM
 SG_ DwnLoadDynLitPrmLedReTurnIndcrRi2ContTiPrm : 7|10@0+ (1.0,0.0) [0.0|1000.0] "Milliseconds" RCMM
 SG_ DwnLoadDynLitPrmLedReTurnIndcrRi2LowBriPrm : 31|8@0+ (1.0,0.0) [0.0|100.0] "%" RCMM
 SG_ DwnLoadDynLitPrmLedReTurnIndcrRi2ModePrm : 13|5@0+ (1,0) [0|31] "" RCMM
 SG_ DwnLoadDynLitPrmLedReTurnIndcrRi2OffsTiPrm : 47|10@0+ (1.0,0.0) [0.0|1000.0] "Milliseconds" RCMM
 SG_ DwnLoadDynLitPrmLedReTurnIndcrRi2Tistamp : 8|9@0+ (1.0,0.0) [0.0|511.0] "Unitless" RCMM
 SG_ DwnLoadDynLitPrmLedReTurnIndcrRi2UpprBriPrm : 39|8@0+ (1.0,0.0) [0.0|100.0] "%" RCMM

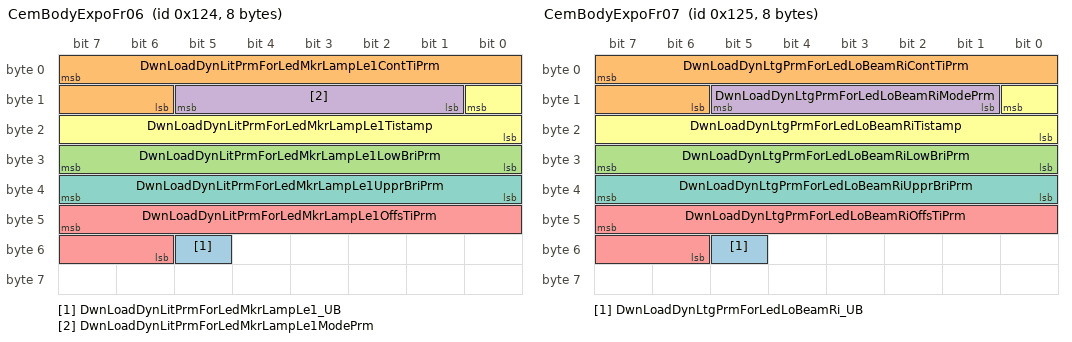
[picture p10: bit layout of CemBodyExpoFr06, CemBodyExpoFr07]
BO_ 292 CemBodyExpoFr06: 8 CEM
 SG_ DwnLoadDynLitPrmForLedMkrLampLe1_UB : 53|1@0+ (1,0) [0|1] "" RCML
 SG_ DwnLoadDynLitPrmForLedMkrLampLe1ContTiPrm : 7|10@0+ (1.0,0.0) [0.0|1000.0] "Milliseconds" RCML
 SG_ DwnLoadDynLitPrmForLedMkrLampLe1LowBriPrm : 31|8@0+ (1.0,0.0) [0.0|100.0] "%" RCML
 SG_ DwnLoadDynLitPrmForLedMkrLampLe1ModePrm : 13|5@0+ (1,0) [0|31] "" RCML
 SG_ DwnLoadDynLitPrmForLedMkrLampLe1OffsTiPrm : 47|10@0+ (1.0,0.0) [0.0|1000.0] "Milliseconds" RCML
 SG_ DwnLoadDynLitPrmForLedMkrLampLe1Tistamp : 8|9@0+ (1.0,0.0) [0.0|511.0] "Unitless" RCML
 SG_ DwnLoadDynLitPrmForLedMkrLampLe1UpprBriPrm : 39|8@0+ (1.0,0.0) [0.0|100.0] "%" RCML

BO_ 293 CemBodyExpoFr07: 8 CEM
 SG_ DwnLoadDynLtgPrmForLedLoBeamRi_UB : 53|1@0+ (1,0) [0|1] "" HCMR
 SG_ DwnLoadDynLtgPrmForLedLoBeamRiContTiPrm : 7|10@0+ (1.0,0.0) [0.0|1000.0] "Milliseconds" HCMR
 SG_ DwnLoadDynLtgPrmForLedLoBeamRiLowBriPrm : 31|8@0+ (1.0,0.0) [0.0|100.0] "%" HCMR
 SG_ DwnLoadDynLtgPrmForLedLoBeamRiModePrm : 13|5@0+ (1,0) [0|31] "" HCMR
 SG_ DwnLoadDynLtgPrmForLedLoBeamRiOffsTiPrm : 47|10@0+ (1.0,0.0) [0.0|1000.0] "Milliseconds" HCMR
 SG_ DwnLoadDynLtgPrmForLedLoBeamRiTistamp : 8|9@0+ (1.0,0.0) [0.0|511.0] "Unitless" HCMR
 SG_ DwnLoadDynLtgPrmForLedLoBeamRiUpprBriPrm : 39|8@0+ (1.0,0.0) [0.0|100.0] "%" HCMR

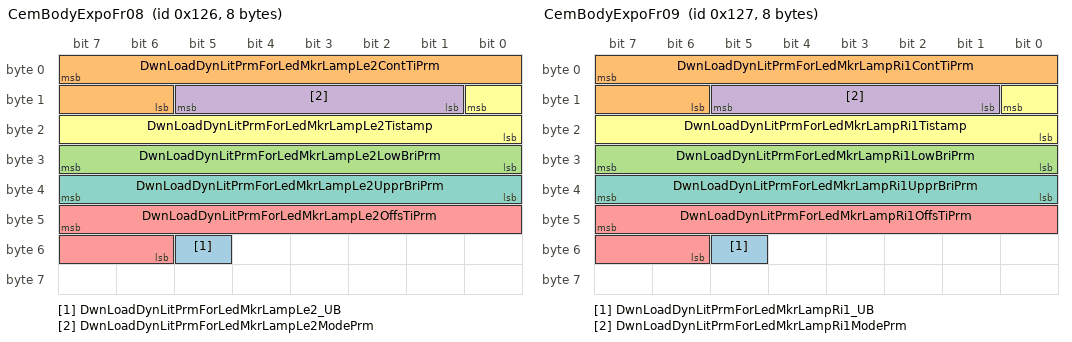
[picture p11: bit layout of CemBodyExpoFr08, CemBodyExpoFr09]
BO_ 294 CemBodyExpoFr08: 8 CEM
 SG_ DwnLoadDynLitPrmForLedMkrLampLe2_UB : 53|1@0+ (1,0) [0|1] "" RCMM
 SG_ DwnLoadDynLitPrmForLedMkrLampLe2ContTiPrm : 7|10@0+ (1.0,0.0) [0.0|1000.0] "Milliseconds" RCMM
 SG_ DwnLoadDynLitPrmForLedMkrLampLe2LowBriPrm : 31|8@0+ (1.0,0.0) [0.0|100.0] "%" RCMM
 SG_ DwnLoadDynLitPrmForLedMkrLampLe2ModePrm : 13|5@0+ (1,0) [0|31] "" RCMM
 SG_ DwnLoadDynLitPrmForLedMkrLampLe2OffsTiPrm : 47|10@0+ (1.0,0.0) [0.0|1000.0] "Milliseconds" RCMM
 SG_ DwnLoadDynLitPrmForLedMkrLampLe2Tistamp : 8|9@0+ (1.0,0.0) [0.0|511.0] "Unitless" RCMM
 SG_ DwnLoadDynLitPrmForLedMkrLampLe2UpprBriPrm : 39|8@0+ (1.0,0.0) [0.0|100.0] "%" RCMM

BO_ 295 CemBodyExpoFr09: 8 CEM
 SG_ DwnLoadDynLitPrmForLedMkrLampRi1_UB : 53|1@0+ (1,0) [0|1] "" RCMR
 SG_ DwnLoadDynLitPrmForLedMkrLampRi1ContTiPrm : 7|10@0+ (1.0,0.0) [0.0|1000.0] "Milliseconds" RCMR
 SG_ DwnLoadDynLitPrmForLedMkrLampRi1LowBriPrm : 31|8@0+ (1.0,0.0) [0.0|100.0] "%" RCMR
 SG_ DwnLoadDynLitPrmForLedMkrLampRi1ModePrm : 13|5@0+ (1,0) [0|31] "" RCMR
 SG_ DwnLoadDynLitPrmForLedMkrLampRi1OffsTiPrm : 47|10@0+ (1.0,0.0) [0.0|1000.0] "Milliseconds" RCMR
 SG_ DwnLoadDynLitPrmForLedMkrLampRi1Tistamp : 8|9@0+ (1.0,0.0) [0.0|511.0] "Unitless" RCMR
 SG_ DwnLoadDynLitPrmForLedMkrLampRi1UpprBriPrm : 39|8@0+ (1.0,0.0) [0.0|100.0] "%" RCMR

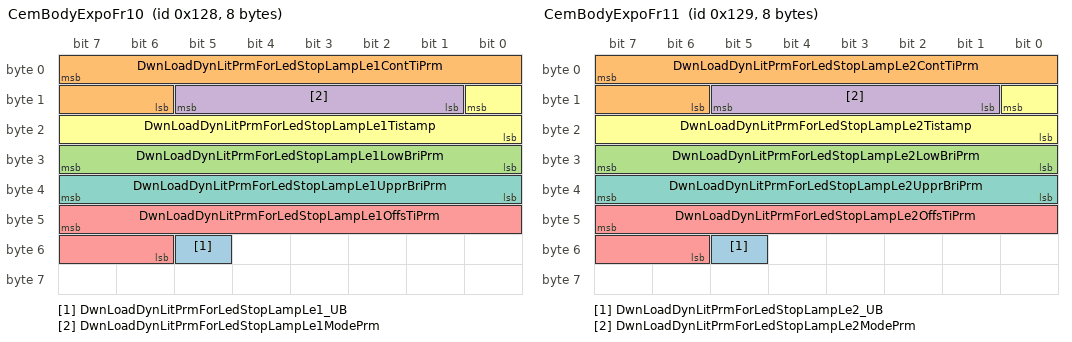
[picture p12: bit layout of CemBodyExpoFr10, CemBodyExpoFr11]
BO_ 296 CemBodyExpoFr10: 8 CEM
 SG_ DwnLoadDynLitPrmForLedStopLampLe1_UB : 53|1@0+ (1,0) [0|1] "" RCML
 SG_ DwnLoadDynLitPrmForLedStopLampLe1ContTiPrm : 7|10@0+ (1.0,0.0) [0.0|1000.0] "Milliseconds" RCML
 SG_ DwnLoadDynLitPrmForLedStopLampLe1LowBriPrm : 31|8@0+ (1.0,0.0) [0.0|100.0] "%" RCML
 SG_ DwnLoadDynLitPrmForLedStopLampLe1ModePrm : 13|5@0+ (1,0) [0|31] "" RCML
 SG_ DwnLoadDynLitPrmForLedStopLampLe1OffsTiPrm : 47|10@0+ (1.0,0.0) [0.0|1000.0] "Milliseconds" RCML
 SG_ DwnLoadDynLitPrmForLedStopLampLe1Tistamp : 8|9@0+ (1.0,0.0) [0.0|511.0] "Unitless" RCML
 SG_ DwnLoadDynLitPrmForLedStopLampLe1UpprBriPrm : 39|8@0+ (1.0,0.0) [0.0|100.0] "%" RCML

BO_ 297 CemBodyExpoFr11: 8 CEM
 SG_ DwnLoadDynLitPrmForLedStopLampLe2_UB : 53|1@0+ (1,0) [0|1] "" RCMM
 SG_ DwnLoadDynLitPrmForLedStopLampLe2ContTiPrm : 7|10@0+ (1.0,0.0) [0.0|1000.0] "Milliseconds" RCMM
 SG_ DwnLoadDynLitPrmForLedStopLampLe2LowBriPrm : 31|8@0+ (1.0,0.0) [0.0|100.0] "%" RCMM
 SG_ DwnLoadDynLitPrmForLedStopLampLe2ModePrm : 13|5@0+ (1,0) [0|31] "" RCMM
 SG_ DwnLoadDynLitPrmForLedStopLampLe2OffsTiPrm : 47|10@0+ (1.0,0.0) [0.0|1000.0] "Milliseconds" RCMM
 SG_ DwnLoadDynLitPrmForLedStopLampLe2Tistamp : 8|9@0+ (1.0,0.0) [0.0|511.0] "Unitless" RCMM
 SG_ DwnLoadDynLitPrmForLedStopLampLe2UpprBriPrm : 39|8@0+ (1.0,0.0) [0.0|100.0] "%" RCMM

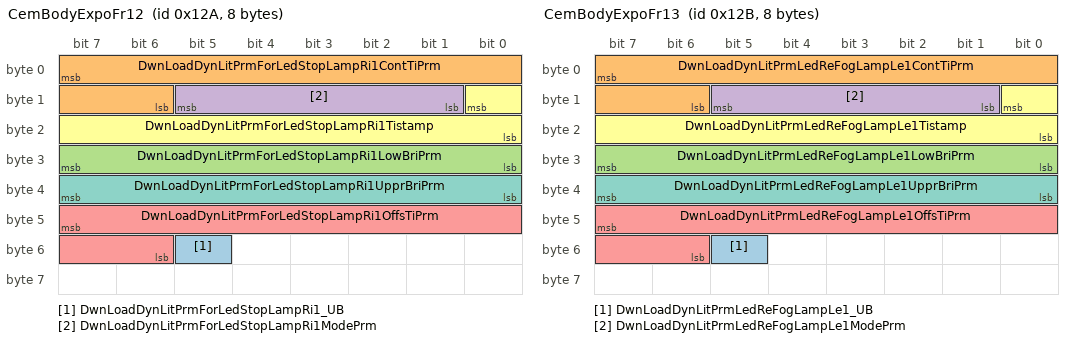
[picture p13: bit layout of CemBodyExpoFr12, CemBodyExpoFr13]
BO_ 298 CemBodyExpoFr12: 8 CEM
 SG_ DwnLoadDynLitPrmForLedStopLampRi1_UB : 53|1@0+ (1,0) [0|1] "" RCMR
 SG_ DwnLoadDynLitPrmForLedStopLampRi1ContTiPrm : 7|10@0+ (1.0,0.0) [0.0|1000.0] "Milliseconds" RCMR
 SG_ DwnLoadDynLitPrmForLedStopLampRi1LowBriPrm : 31|8@0+ (1.0,0.0) [0.0|100.0] "%" RCMR
 SG_ DwnLoadDynLitPrmForLedStopLampRi1ModePrm : 13|5@0+ (1,0) [0|31] "" RCMR
 SG_ DwnLoadDynLitPrmForLedStopLampRi1OffsTiPrm : 47|10@0+ (1.0,0.0) [0.0|1000.0] "Milliseconds" RCMR
 SG_ DwnLoadDynLitPrmForLedStopLampRi1Tistamp : 8|9@0+ (1.0,0.0) [0.0|511.0] "Unitless" RCMR
 SG_ DwnLoadDynLitPrmForLedStopLampRi1UpprBriPrm : 39|8@0+ (1.0,0.0) [0.0|100.0] "%" RCMR

BO_ 299 CemBodyExpoFr13: 8 CEM
 SG_ DwnLoadDynLitPrmLedReFogLampLe1_UB : 53|1@0+ (1,0) [0|1] "" RCML
 SG_ DwnLoadDynLitPrmLedReFogLampLe1ContTiPrm : 7|10@0+ (1.0,0.0) [0.0|1000.0] "Milliseconds" RCML
 SG_ DwnLoadDynLitPrmLedReFogLampLe1LowBriPrm : 31|8@0+ (1.0,0.0) [0.0|100.0] "%" RCML
 SG_ DwnLoadDynLitPrmLedReFogLampLe1ModePrm : 13|5@0+ (1,0) [0|31] "" RCML
 SG_ DwnLoadDynLitPrmLedReFogLampLe1OffsTiPrm : 47|10@0+ (1.0,0.0) [0.0|1000.0] "Milliseconds" RCML
 SG_ DwnLoadDynLitPrmLedReFogLampLe1Tistamp : 8|9@0+ (1.0,0.0) [0.0|511.0] "Unitless" RCML
 SG_ DwnLoadDynLitPrmLedReFogLampLe1UpprBriPrm : 39|8@0+ (1.0,0.0) [0.0|100.0] "%" RCML

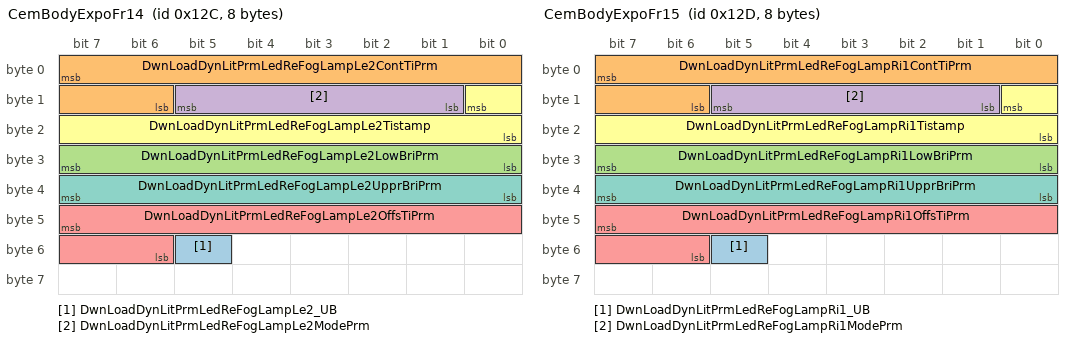
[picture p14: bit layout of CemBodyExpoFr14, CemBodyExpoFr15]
BO_ 300 CemBodyExpoFr14: 8 CEM
 SG_ DwnLoadDynLitPrmLedReFogLampLe2_UB : 53|1@0+ (1,0) [0|1] "" RCMM
 SG_ DwnLoadDynLitPrmLedReFogLampLe2ContTiPrm : 7|10@0+ (1.0,0.0) [0.0|1000.0] "Milliseconds" RCMM
 SG_ DwnLoadDynLitPrmLedReFogLampLe2LowBriPrm : 31|8@0+ (1.0,0.0) [0.0|100.0] "%" RCMM
 SG_ DwnLoadDynLitPrmLedReFogLampLe2ModePrm : 13|5@0+ (1,0) [0|31] "" RCMM
 SG_ DwnLoadDynLitPrmLedReFogLampLe2OffsTiPrm : 47|10@0+ (1.0,0.0) [0.0|1000.0] "Milliseconds" RCMM
 SG_ DwnLoadDynLitPrmLedReFogLampLe2Tistamp : 8|9@0+ (1.0,0.0) [0.0|511.0] "Unitless" RCMM
 SG_ DwnLoadDynLitPrmLedReFogLampLe2UpprBriPrm : 39|8@0+ (1.0,0.0) [0.0|100.0] "%" RCMM

BO_ 301 CemBodyExpoFr15: 8 CEM
 SG_ DwnLoadDynLitPrmLedReFogLampRi1_UB : 53|1@0+ (1,0) [0|1] "" RCMR
 SG_ DwnLoadDynLitPrmLedReFogLampRi1ContTiPrm : 7|10@0+ (1.0,0.0) [0.0|1000.0] "Milliseconds" RCMR
 SG_ DwnLoadDynLitPrmLedReFogLampRi1LowBriPrm : 31|8@0+ (1.0,0.0) [0.0|100.0] "%" RCMR
 SG_ DwnLoadDynLitPrmLedReFogLampRi1ModePrm : 13|5@0+ (1,0) [0|31] "" RCMR
 SG_ DwnLoadDynLitPrmLedReFogLampRi1OffsTiPrm : 47|10@0+ (1.0,0.0) [0.0|1000.0] "Milliseconds" RCMR
 SG_ DwnLoadDynLitPrmLedReFogLampRi1Tistamp : 8|9@0+ (1.0,0.0) [0.0|511.0] "Unitless" RCMR
 SG_ DwnLoadDynLitPrmLedReFogLampRi1UpprBriPrm : 39|8@0+ (1.0,0.0) [0.0|100.0] "%" RCMR

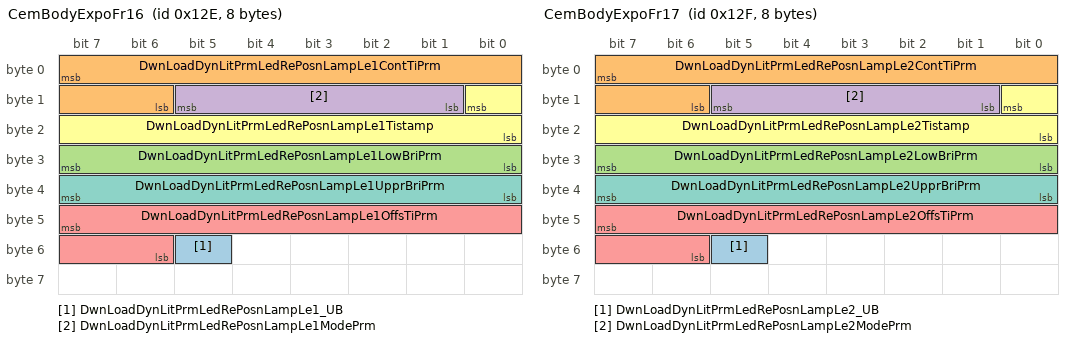
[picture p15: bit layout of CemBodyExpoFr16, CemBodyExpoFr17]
BO_ 302 CemBodyExpoFr16: 8 CEM
 SG_ DwnLoadDynLitPrmLedRePosnLampLe1_UB : 53|1@0+ (1,0) [0|1] "" RCML
 SG_ DwnLoadDynLitPrmLedRePosnLampLe1ContTiPrm : 7|10@0+ (1.0,0.0) [0.0|1000.0] "Milliseconds" RCML
 SG_ DwnLoadDynLitPrmLedRePosnLampLe1LowBriPrm : 31|8@0+ (1.0,0.0) [0.0|100.0] "%" RCML
 SG_ DwnLoadDynLitPrmLedRePosnLampLe1ModePrm : 13|5@0+ (1,0) [0|31] "" RCML
 SG_ DwnLoadDynLitPrmLedRePosnLampLe1OffsTiPrm : 47|10@0+ (1.0,0.0) [0.0|1000.0] "Milliseconds" RCML
 SG_ DwnLoadDynLitPrmLedRePosnLampLe1Tistamp : 8|9@0+ (1.0,0.0) [0.0|511.0] "Unitless" RCML
 SG_ DwnLoadDynLitPrmLedRePosnLampLe1UpprBriPrm : 39|8@0+ (1.0,0.0) [0.0|100.0] "%" RCML

BO_ 303 CemBodyExpoFr17: 8 CEM
 SG_ DwnLoadDynLitPrmLedRePosnLampLe2_UB : 53|1@0+ (1,0) [0|1] "" RCMM
 SG_ DwnLoadDynLitPrmLedRePosnLampLe2ContTiPrm : 7|10@0+ (1.0,0.0) [0.0|1000.0] "Milliseconds" RCMM
 SG_ DwnLoadDynLitPrmLedRePosnLampLe2LowBriPrm : 31|8@0+ (1.0,0.0) [0.0|100.0] "%" RCMM
 SG_ DwnLoadDynLitPrmLedRePosnLampLe2ModePrm : 13|5@0+ (1,0) [0|31] "" RCMM
 SG_ DwnLoadDynLitPrmLedRePosnLampLe2OffsTiPrm : 47|10@0+ (1.0,0.0) [0.0|1000.0] "Milliseconds" RCMM
 SG_ DwnLoadDynLitPrmLedRePosnLampLe2Tistamp : 8|9@0+ (1.0,0.0) [0.0|511.0] "Unitless" RCMM
 SG_ DwnLoadDynLitPrmLedRePosnLampLe2UpprBriPrm : 39|8@0+ (1.0,0.0) [0.0|100.0] "%" RCMM

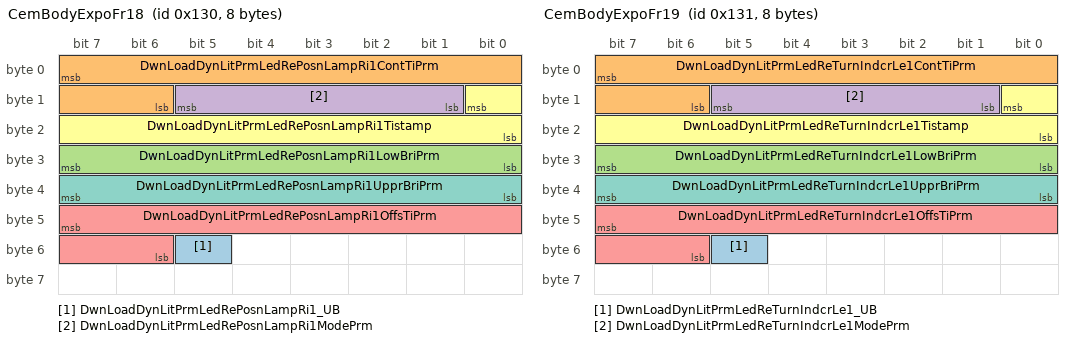
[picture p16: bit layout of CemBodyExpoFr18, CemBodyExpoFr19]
BO_ 304 CemBodyExpoFr18: 8 CEM
 SG_ DwnLoadDynLitPrmLedRePosnLampRi1_UB : 53|1@0+ (1,0) [0|1] "" RCMR
 SG_ DwnLoadDynLitPrmLedRePosnLampRi1ContTiPrm : 7|10@0+ (1.0,0.0) [0.0|1000.0] "Milliseconds" RCMR
 SG_ DwnLoadDynLitPrmLedRePosnLampRi1LowBriPrm : 31|8@0+ (1.0,0.0) [0.0|100.0] "%" RCMR
 SG_ DwnLoadDynLitPrmLedRePosnLampRi1ModePrm : 13|5@0+ (1,0) [0|31] "" RCMR
 SG_ DwnLoadDynLitPrmLedRePosnLampRi1OffsTiPrm : 47|10@0+ (1.0,0.0) [0.0|1000.0] "Milliseconds" RCMR
 SG_ DwnLoadDynLitPrmLedRePosnLampRi1Tistamp : 8|9@0+ (1.0,0.0) [0.0|511.0] "Unitless" RCMR
 SG_ DwnLoadDynLitPrmLedRePosnLampRi1UpprBriPrm : 39|8@0+ (1.0,0.0) [0.0|100.0] "%" RCMR

BO_ 305 CemBodyExpoFr19: 8 CEM
 SG_ DwnLoadDynLitPrmLedReTurnIndcrLe1_UB : 53|1@0+ (1,0) [0|1] "" RCML
 SG_ DwnLoadDynLitPrmLedReTurnIndcrLe1ContTiPrm : 7|10@0+ (1.0,0.0) [0.0|1000.0] "Milliseconds" RCML
 SG_ DwnLoadDynLitPrmLedReTurnIndcrLe1LowBriPrm : 31|8@0+ (1.0,0.0) [0.0|100.0] "%" RCML
 SG_ DwnLoadDynLitPrmLedReTurnIndcrLe1ModePrm : 13|5@0+ (1,0) [0|31] "" RCML
 SG_ DwnLoadDynLitPrmLedReTurnIndcrLe1OffsTiPrm : 47|10@0+ (1.0,0.0) [0.0|1000.0] "Milliseconds" RCML
 SG_ DwnLoadDynLitPrmLedReTurnIndcrLe1Tistamp : 8|9@0+ (1.0,0.0) [0.0|511.0] "Unitless" RCML
 SG_ DwnLoadDynLitPrmLedReTurnIndcrLe1UpprBriPrm : 39|8@0+ (1.0,0.0) [0.0|100.0] "%" RCML

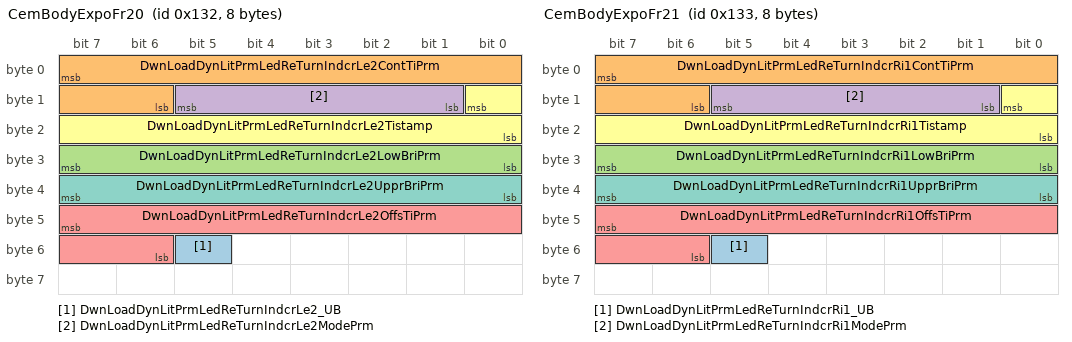
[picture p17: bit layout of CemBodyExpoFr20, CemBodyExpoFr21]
BO_ 306 CemBodyExpoFr20: 8 CEM
 SG_ DwnLoadDynLitPrmLedReTurnIndcrLe2_UB : 53|1@0+ (1,0) [0|1] "" RCMM
 SG_ DwnLoadDynLitPrmLedReTurnIndcrLe2ContTiPrm : 7|10@0+ (1.0,0.0) [0.0|1000.0] "Milliseconds" RCMM
 SG_ DwnLoadDynLitPrmLedReTurnIndcrLe2LowBriPrm : 31|8@0+ (1.0,0.0) [0.0|100.0] "%" RCMM
 SG_ DwnLoadDynLitPrmLedReTurnIndcrLe2ModePrm : 13|5@0+ (1,0) [0|31] "" RCMM
 SG_ DwnLoadDynLitPrmLedReTurnIndcrLe2OffsTiPrm : 47|10@0+ (1.0,0.0) [0.0|1000.0] "Milliseconds" RCMM
 SG_ DwnLoadDynLitPrmLedReTurnIndcrLe2Tistamp : 8|9@0+ (1.0,0.0) [0.0|511.0] "Unitless" RCMM
 SG_ DwnLoadDynLitPrmLedReTurnIndcrLe2UpprBriPrm : 39|8@0+ (1.0,0.0) [0.0|100.0] "%" RCMM

BO_ 307 CemBodyExpoFr21: 8 CEM
 SG_ DwnLoadDynLitPrmLedReTurnIndcrRi1_UB : 53|1@0+ (1,0) [0|1] "" RCMR
 SG_ DwnLoadDynLitPrmLedReTurnIndcrRi1ContTiPrm : 7|10@0+ (1.0,0.0) [0.0|1000.0] "Milliseconds" RCMR
 SG_ DwnLoadDynLitPrmLedReTurnIndcrRi1LowBriPrm : 31|8@0+ (1.0,0.0) [0.0|100.0] "%" RCMR
 SG_ DwnLoadDynLitPrmLedReTurnIndcrRi1ModePrm : 13|5@0+ (1,0) [0|31] "" RCMR
 SG_ DwnLoadDynLitPrmLedReTurnIndcrRi1OffsTiPrm : 47|10@0+ (1.0,0.0) [0.0|1000.0] "Milliseconds" RCMR
 SG_ DwnLoadDynLitPrmLedReTurnIndcrRi1Tistamp : 8|9@0+ (1.0,0.0) [0.0|511.0] "Unitless" RCMR
 SG_ DwnLoadDynLitPrmLedReTurnIndcrRi1UpprBriPrm : 39|8@0+ (1.0,0.0) [0.0|100.0] "%" RCMR

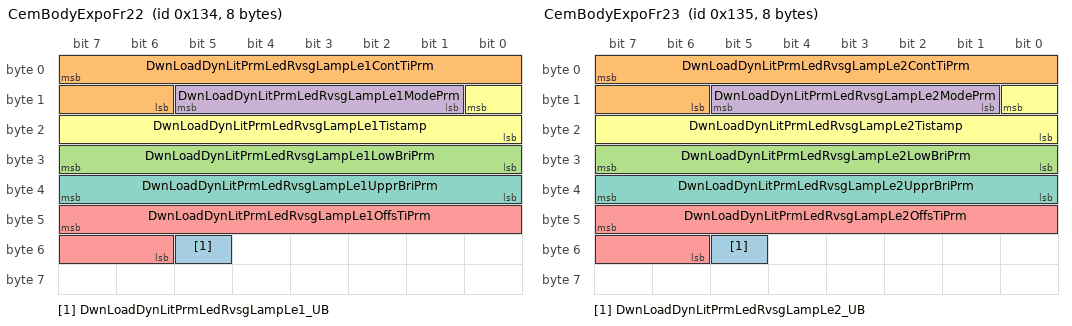
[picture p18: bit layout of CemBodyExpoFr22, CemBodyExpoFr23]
BO_ 308 CemBodyExpoFr22: 8 CEM
 SG_ DwnLoadDynLitPrmLedRvsgLampLe1_UB : 53|1@0+ (1,0) [0|1] "" RCML
 SG_ DwnLoadDynLitPrmLedRvsgLampLe1ContTiPrm : 7|10@0+ (1.0,0.0) [0.0|1000.0] "Milliseconds" RCML
 SG_ DwnLoadDynLitPrmLedRvsgLampLe1LowBriPrm : 31|8@0+ (1.0,0.0) [0.0|100.0] "%" RCML
 SG_ DwnLoadDynLitPrmLedRvsgLampLe1ModePrm : 13|5@0+ (1,0) [0|31] "" RCML
 SG_ DwnLoadDynLitPrmLedRvsgLampLe1OffsTiPrm : 47|10@0+ (1.0,0.0) [0.0|1000.0] "Milliseconds" RCML
 SG_ DwnLoadDynLitPrmLedRvsgLampLe1Tistamp : 8|9@0+ (1.0,0.0) [0.0|511.0] "Unitless" RCML
 SG_ DwnLoadDynLitPrmLedRvsgLampLe1UpprBriPrm : 39|8@0+ (1.0,0.0) [0.0|100.0] "%" RCML

BO_ 309 CemBodyExpoFr23: 8 CEM
 SG_ DwnLoadDynLitPrmLedRvsgLampLe2_UB : 53|1@0+ (1,0) [0|1] "" RCMM
 SG_ DwnLoadDynLitPrmLedRvsgLampLe2ContTiPrm : 7|10@0+ (1.0,0.0) [0.0|1000.0] "Milliseconds" RCMM
 SG_ DwnLoadDynLitPrmLedRvsgLampLe2LowBriPrm : 31|8@0+ (1.0,0.0) [0.0|100.0] "%" RCMM
 SG_ DwnLoadDynLitPrmLedRvsgLampLe2ModePrm : 13|5@0+ (1,0) [0|31] "" RCMM
 SG_ DwnLoadDynLitPrmLedRvsgLampLe2OffsTiPrm : 47|10@0+ (1.0,0.0) [0.0|1000.0] "Milliseconds" RCMM
 SG_ DwnLoadDynLitPrmLedRvsgLampLe2Tistamp : 8|9@0+ (1.0,0.0) [0.0|511.0] "Unitless" RCMM
 SG_ DwnLoadDynLitPrmLedRvsgLampLe2UpprBriPrm : 39|8@0+ (1.0,0.0) [0.0|100.0] "%" RCMM

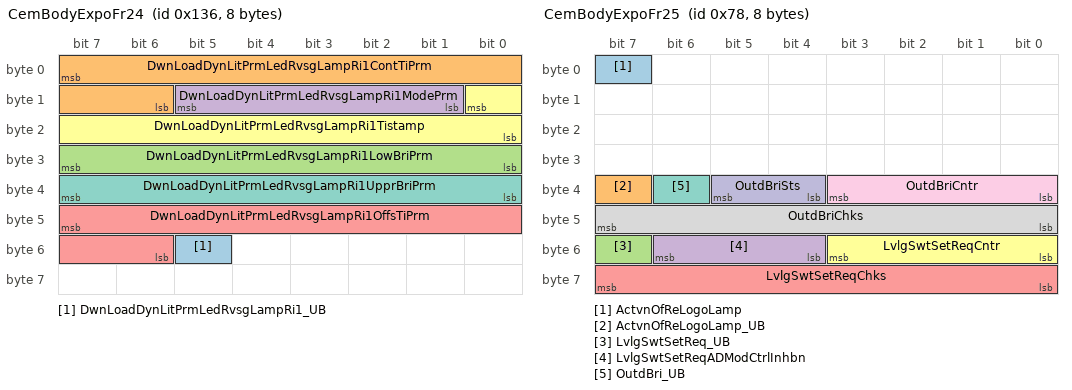
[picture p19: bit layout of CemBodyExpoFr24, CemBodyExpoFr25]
BO_ 310 CemBodyExpoFr24: 8 CEM
 SG_ DwnLoadDynLitPrmLedRvsgLampRi1_UB : 53|1@0+ (1,0) [0|1] "" RCMR
 SG_ DwnLoadDynLitPrmLedRvsgLampRi1ContTiPrm : 7|10@0+ (1.0,0.0) [0.0|1000.0] "Milliseconds" RCMR
 SG_ DwnLoadDynLitPrmLedRvsgLampRi1LowBriPrm : 31|8@0+ (1.0,0.0) [0.0|100.0] "%" RCMR
 SG_ DwnLoadDynLitPrmLedRvsgLampRi1ModePrm : 13|5@0+ (1,0) [0|31] "" RCMR
 SG_ DwnLoadDynLitPrmLedRvsgLampRi1OffsTiPrm : 47|10@0+ (1.0,0.0) [0.0|1000.0] "Milliseconds" RCMR
 SG_ DwnLoadDynLitPrmLedRvsgLampRi1Tistamp : 8|9@0+ (1.0,0.0) [0.0|511.0] "Unitless" RCMR
 SG_ DwnLoadDynLitPrmLedRvsgLampRi1UpprBriPrm : 39|8@0+ (1.0,0.0) [0.0|100.0] "%" RCMR

BO_ 120 CemBodyExpoFr25: 8 CEM
 SG_ ActvnOfReLogoLamp : 7|1@0+ (1,0) [0|1] "" RCMM
 SG_ ActvnOfReLogoLamp_UB : 39|1@0+ (1,0) [0|1] "" RCMM
 SG_ LvlgSwtSetReq_UB : 55|1@0+ (1,0) [0|1] "" HCML,HCMR
 SG_ LvlgSwtSetReqADModCtrlInhbn : 54|3@0+ (1,0) [0|7] "" HCML,HCMR
 SG_ LvlgSwtSetReqChks : 63|8@0+ (1.0,0.0) [0.0|255.0] "Unitless" HCML,HCMR
 SG_ LvlgSwtSetReqCntr : 51|4@0+ (1.0,0.0) [0.0|15.0] "Unitless" HCML,HCMR
 SG_ OutdBri_UB : 38|1@0+ (1,0) [0|1] "" HCML,HCMR
 SG_ OutdBriChks : 47|8@0+ (1.0,0.0) [0.0|255.0] "Unitless" HCML,HCMR
 SG_ OutdBriCntr : 35|4@0+ (1.0,0.0) [0.0|15.0] "Unitless" HCML,HCMR
 SG_ OutdBriSts : 37|2@0+ (1,0) [0|3] "" HCML,HCMR

BO_ 311 CemBodyExpoFr26: 8 CEM
 SG_ DwnLoadDynLitPrmForLedHiBeamLe_UB : 53|1@0+ (1,0) [0|1] "" HCML
 SG_ DwnLoadDynLitPrmForLedHiBeamLeContTiPrm : 7|10@0+ (1.0,0.0) [0.0|1000.0] "Milliseconds" HCML
 SG_ DwnLoadDynLitPrmForLedHiBeamLeLowBriPrm : 31|8@0+ (1.0,0.0) [0.0|100.0] "%" HCML
 SG_ DwnLoadDynLitPrmForLedHiBeamLeModePrm : 13|5@0+ (1,0) [0|31] "" HCML
 SG_ DwnLoadDynLitPrmForLedHiBeamLeOffsTiPrm : 47|10@0+ (1.0,0.0) [0.0|1000.0] "Milliseconds" HCML
 SG_ DwnLoadDynLitPrmForLedHiBeamLeTistamp : 8|9@0+ (1.0,0.0) [0.0|511.0] "Unitless" HCML
 SG_ DwnLoadDynLitPrmForLedHiBeamLeUpprBriPrm : 39|8@0+ (1.0,0.0) [0.0|100.0] "%" HCML

// Node Comments
CM_ BU_ CEM "Central Electronic Module";
CM_ BU_ ETC "External Tester Connector";
CM_ BU_ HCML "Headlamp Control Module Left";
CM_ BU_ HCMR "Headlamp Control Module Right";

// Signal Comments
CM_ SG_ 82 AutWinWipgCmd "Wiping speed command.";
CM_ SG_ 82 LiOprnMod "Information about day, night, twilight and tunnel detection.";
CM_ SG_ 82 SteerWhlSnsrAg "Actual steering wheel angle from the actual centre position of the steering wheel. ";
CM_ SG_ 82 SteerWhlSnsrAgSpd "Actual steering wheel angle from the actual centre position of the steering wheel. Steering angle speed with steering wheel rotation direction.  ";
CM_ SG_ 82 SteerWhlSnsrChks "Checksum for steering wheel sensor data.";
CM_ SG_ 82 SteerWhlSnsrCntr "Counter value for steering wheel sensor data.";
CM_ SG_ 82 SteerWhlSnsrQf "Qf for steering wheel sensor information";
CM_ SG_ 768 ActvnOfRvsg "Activation of Reverse Light";
CM_ SG_ 768 YawRateReqdByDrvr "When the vehicle is making a left turn this signal is supposed to show positive numbers. Unfiltered and offset compensated plausibility check";
CM_ SG_ 80 VehSpdLgtA "Vehicle speed longitudinal based on wheel speed sensors and longitudinal acceleration.";
CM_ SG_ 80 VehSpdLgtChks "Checksum";
CM_ SG_ 80 VehSpdLgtCntr "Counter";
CM_ SG_ 80 VehSpdLgtQf "Quality factor for vehicle speed as measured by wheel speed sensors and longitudinal acceleration.";
CM_ SG_ 384 VehCfgPrmBlkIDBytePosn1 "signal block counter.";
CM_ SG_ 384 VehCfgPrmCCPBytePosn2 " (BlockID-1)*7 + 1. ";
CM_ SG_ 384 VehCfgPrmCCPBytePosn3 " (BlockID-1)*7 + 2. ";
CM_ SG_ 384 VehCfgPrmCCPBytePosn4 " (BlockID-1)*7 + 3. ";
CM_ SG_ 384 VehCfgPrmCCPBytePosn5 " (BlockID-1)*7 + 4. ";
CM_ SG_ 384 VehCfgPrmCCPBytePosn6 " (BlockID-1)*7 + 5. ";
CM_ SG_ 384 VehCfgPrmCCPBytePosn7 " (BlockID-1)*7 + 6. ";
CM_ SG_ 384 VehCfgPrmCCPBytePosn8 " (BlockID-1)*7 + 7. ";
CM_ SG_ 512 BkpOfDstTrvld "total traveled distance.";
CM_ SG_ 512 ExtrLiRlyPwrDwn "Informs HCMs about upcoming shut down of Exterior Light Relay.";
CM_ SG_ 512 VehBattUSysU "Vehicle System Voltage At 12V side";
CM_ SG_ 512 VehBattUSysUQf "Present vehicle voltage measured by CEM with QF";
CM_ SG_ 544 ActnOfLedGrilleLamp "Activate LED Front Grille Lamp.";
CM_ SG_ 544 Body2CntrForMissCom "Body Exposed detection for Diagnostic";
CM_ SG_ 544 CarTiGlb "Presents a tiime value that shall be used by all ECUs to time-stamp diagnsotic trouble codes (DTC) according to the requirements for Global DTC snapshot data.";
CM_ SG_ 544 TrSts "TrSts - Tailgate or Bootlid Status
Ukwn - Unknown status
Opend - Opened
Clsd - Closed";
CM_ SG_ 128 AccrPedlRatAccrPedlRat "Accelerator Pedal Position with adapted 0 point. Value as percentage of fully pressed pedal";
CM_ SG_ 128 AccrPedlRatChks "Accelerator Pedal Position with adapted 0 point. Value as percentage of fully pressed pedal. Checksum";
CM_ SG_ 128 AccrPedlRatCntr "Accelerator Pedal Position with adapted 0 point. Value as percentage of fully pressed pedal. Counter";
CM_ SG_ 128 AmbTRawAmbTVal "Unfiltered ambient temp raw data in deg C. Ambient temp value";
CM_ SG_ 128 AmbTRawQly "Unfiltered ambient temp raw data in deg C. Quality Factor of the ambient temp";
CM_ SG_ 128 BrkPedlSnsrChks "E2E protection, checksum. ";
CM_ SG_ 128 BrkPedlSnsrCntr "E2E protection, counter.";
CM_ SG_ 128 BrkPedlSnsrQf "Brake pedal state, quality factor";
CM_ SG_ 128 BrkPedlSnsrSt "brake pedal state, pressed or not pressed.";
CM_ SG_ 128 TooManyCars "Whether there are too many cars";
CM_ SG_ 387 VehCfgPrmExtBlkIDBytePosn1 "CarConfigExtended BlockID";
CM_ SG_ 387 VehCfgPrmExtCCPBytePosn2 "CarConfigExtended BytePos2";
CM_ SG_ 387 VehCfgPrmExtCCPBytePosn3 "CarConfigExtended BytePos3";
CM_ SG_ 387 VehCfgPrmExtCCPBytePosn4 "CarConfigExtended BytePos4";
CM_ SG_ 387 VehCfgPrmExtCCPBytePosn5 "CarConfigExtended BytePos5";
CM_ SG_ 387 VehCfgPrmExtCCPBytePosn6 "CarConfigExtended BytePos6";
CM_ SG_ 387 VehCfgPrmExtCCPBytePosn7 "CarConfigExtended BytePos7";
CM_ SG_ 387 VehCfgPrmExtCCPBytePosn8 "CarConfigExtended BytePos8";
CM_ SG_ 389 TrafficSignForADB1AdbAbsDist "refer to VehObjforADB1";
CM_ SG_ 389 TrafficSignForADB1AdbDetdQly "refer to VehObjforADB1";
CM_ SG_ 389 TrafficSignForADB1AdbHozlAg "refer to VehObjforADB1";
CM_ SG_ 389 TrafficSignForADB1AdbObjHozlAgSpd "refer to VehObjforADB1";
CM_ SG_ 389 TrafficSignForADB1AdbObjVertAgSpd "refer to VehObjforADB1";
CM_ SG_ 389 TrafficSignForADB1AdbTrkInfo "refer to VehObjforADB1";
CM_ SG_ 389 TrafficSignForADB1AdbVertAg "refer to VehObjforADB1";
CM_ SG_ 390 TrafficSignForADB2AdbAbsDist "refer to VehObjforADB1";
CM_ SG_ 390 TrafficSignForADB2AdbDetdQly "refer to VehObjforADB1";
CM_ SG_ 390 TrafficSignForADB2AdbHozlAg "refer to VehObjforADB1";
CM_ SG_ 390 TrafficSignForADB2AdbObjHozlAgSpd "refer to VehObjforADB1";
CM_ SG_ 390 TrafficSignForADB2AdbObjVertAgSpd "refer to VehObjforADB1";
CM_ SG_ 390 TrafficSignForADB2AdbTrkInfo "refer to VehObjforADB1";
CM_ SG_ 390 TrafficSignForADB2AdbVertAg "refer to VehObjforADB1";
CM_ SG_ 391 VehObjforAHBAdbAbsDist "refer to VehObjforADB1";
CM_ SG_ 391 VehObjforAHBAdbClassn "refer to VehObjforADB1";
CM_ SG_ 391 VehObjforAHBAdbClassnQly "refer to VehObjforADB1";
CM_ SG_ 391 VehObjforAHBAdbDetdQly "refer to VehObjforADB1";
CM_ SG_ 391 VehObjforAHBAdbHozlAg "refer to VehObjforADB1";
CM_ SG_ 391 VehObjforAHBAdbObjDir "refer to VehObjforADB1";
CM_ SG_ 391 VehObjforAHBAdbObjHozlAgSpd "refer to VehObjforADB1";
CM_ SG_ 391 VehObjforAHBAdbObjVertAgSpd "refer to VehObjforADB1";
CM_ SG_ 391 VehObjforAHBAdbTrkInfo "refer to VehObjforADB1";
CM_ SG_ 391 VehObjforAHBAdbVertAg "refer to VehObjforADB1";
CM_ SG_ 392 VehObjforADB1AdbAbsDist "Absolute distance between ego vehicle/camera and object";
CM_ SG_ 392 VehObjforADB1AdbClassn "Object Type";
CM_ SG_ 392 VehObjforADB1AdbClassnQly "provide 3 confidence levels of object classification on different conditions.";
CM_ SG_ 392 VehObjforADB1AdbDetdQly "provide 3 confidence levels of object detection on different conditions.";
CM_ SG_ 392 VehObjforADB1AdbHozlAg "horizontal angle between object center of  front/tail lamp and the ego vehicle camera";
CM_ SG_ 392 VehObjforADB1AdbObjDir "Object moving direction";
CM_ SG_ 392 VehObjforADB1AdbObjHozlAgSpd "Object left angle moving speed";
CM_ SG_ 392 VehObjforADB1AdbObjVertAgSpd "Object bottom angle moving speed";
CM_ SG_ 392 VehObjforADB1AdbTrkInfo "Is the object a tracked one or a spontaneously occuring one";
CM_ SG_ 392 VehObjforADB1AdbVertAg "angle between ego vehicle camera and the object ";
CM_ SG_ 393 VehObjforADB2AdbAbsDist "refer to VehObjforADB1";
CM_ SG_ 393 VehObjforADB2AdbClassn "refer to VehObjforADB1";
CM_ SG_ 393 VehObjforADB2AdbClassnQly "refer to VehObjforADB1";
CM_ SG_ 393 VehObjforADB2AdbDetdQly "refer to VehObjforADB1";
CM_ SG_ 393 VehObjforADB2AdbHozlAg "refer to VehObjforADB1";
CM_ SG_ 393 VehObjforADB2AdbObjDir "refer to VehObjforADB1";
CM_ SG_ 393 VehObjforADB2AdbObjHozlAgSpd "refer to VehObjforADB1";
CM_ SG_ 393 VehObjforADB2AdbObjVertAgSpd "refer to VehObjforADB1";
CM_ SG_ 393 VehObjforADB2AdbTrkInfo "refer to VehObjforADB1";
CM_ SG_ 393 VehObjforADB2AdbVertAg "refer to VehObjforADB1";
CM_ SG_ 394 VehObjforADB3AdbAbsDist "refer to VehObjforADB1";
CM_ SG_ 394 VehObjforADB3AdbClassn "refer to VehObjforADB1";
CM_ SG_ 394 VehObjforADB3AdbClassnQly "refer to VehObjforADB1";
CM_ SG_ 394 VehObjforADB3AdbDetdQly "refer to VehObjforADB1";
CM_ SG_ 394 VehObjforADB3AdbHozlAg "refer to VehObjforADB1";
CM_ SG_ 394 VehObjforADB3AdbObjDir "refer to VehObjforADB1";
CM_ SG_ 394 VehObjforADB3AdbObjHozlAgSpd "refer to VehObjforADB1";
CM_ SG_ 394 VehObjforADB3AdbObjVertAgSpd "refer to VehObjforADB1";
CM_ SG_ 394 VehObjforADB3AdbTrkInfo "refer to VehObjforADB1";
CM_ SG_ 394 VehObjforADB3AdbVertAg "refer to VehObjforADB1";
CM_ SG_ 395 VehObjforADB4AdbAbsDist "refer to VehObjforADB1";
CM_ SG_ 395 VehObjforADB4AdbClassn "refer to VehObjforADB1";
CM_ SG_ 395 VehObjforADB4AdbClassnQly "refer to VehObjforADB1";
CM_ SG_ 395 VehObjforADB4AdbDetdQly "refer to VehObjforADB1";
CM_ SG_ 395 VehObjforADB4AdbHozlAg "refer to VehObjforADB1";
CM_ SG_ 395 VehObjforADB4AdbObjDir "refer to VehObjforADB1";
CM_ SG_ 395 VehObjforADB4AdbObjHozlAgSpd "refer to VehObjforADB1";
CM_ SG_ 395 VehObjforADB4AdbObjVertAgSpd "refer to VehObjforADB1";
CM_ SG_ 395 VehObjforADB4AdbTrkInfo "refer to VehObjforADB1";
CM_ SG_ 395 VehObjforADB4AdbVertAg "refer to VehObjforADB1";
CM_ SG_ 396 VehObjforADB5AdbAbsDist "refer to VehObjforADB1";
CM_ SG_ 396 VehObjforADB5AdbClassn "refer to VehObjforADB1";
CM_ SG_ 396 VehObjforADB5AdbClassnQly "refer to VehObjforADB1";
CM_ SG_ 396 VehObjforADB5AdbDetdQly "refer to VehObjforADB1";
CM_ SG_ 396 VehObjforADB5AdbHozlAg "refer to VehObjforADB1";
CM_ SG_ 396 VehObjforADB5AdbObjDir "refer to VehObjforADB1";
CM_ SG_ 396 VehObjforADB5AdbObjHozlAgSpd "refer to VehObjforADB1";
CM_ SG_ 396 VehObjforADB5AdbObjVertAgSpd "refer to VehObjforADB1";
CM_ SG_ 396 VehObjforADB5AdbTrkInfo "refer to VehObjforADB1";
CM_ SG_ 396 VehObjforADB5AdbVertAg "refer to VehObjforADB1";
CM_ SG_ 397 VehObjforADB6AdbAbsDist "refer to VehObjforADB1";
CM_ SG_ 397 VehObjforADB6AdbClassn "refer to VehObjforADB1";
CM_ SG_ 397 VehObjforADB6AdbClassnQly "refer to VehObjforADB1";
CM_ SG_ 397 VehObjforADB6AdbDetdQly "refer to VehObjforADB1";
CM_ SG_ 397 VehObjforADB6AdbHozlAg "refer to VehObjforADB1";
CM_ SG_ 397 VehObjforADB6AdbObjDir "refer to VehObjforADB1";
CM_ SG_ 397 VehObjforADB6AdbObjHozlAgSpd "refer to VehObjforADB1";
CM_ SG_ 397 VehObjforADB6AdbObjVertAgSpd "refer to VehObjforADB1";
CM_ SG_ 397 VehObjforADB6AdbTrkInfo "refer to VehObjforADB1";
CM_ SG_ 397 VehObjforADB6AdbVertAg "refer to VehObjforADB1";
CM_ SG_ 398 VehObjforADB7AdbAbsDist "refer to VehObjforADB1";
CM_ SG_ 398 VehObjforADB7AdbClassn "refer to VehObjforADB1";
CM_ SG_ 398 VehObjforADB7AdbClassnQly "refer to VehObjforADB1";
CM_ SG_ 398 VehObjforADB7AdbDetdQly "refer to VehObjforADB1";
CM_ SG_ 398 VehObjforADB7AdbHozlAg "refer to VehObjforADB1";
CM_ SG_ 398 VehObjforADB7AdbObjDir "refer to VehObjforADB1";
CM_ SG_ 398 VehObjforADB7AdbObjHozlAgSpd "refer to VehObjforADB1";
CM_ SG_ 398 VehObjforADB7AdbObjVertAgSpd "refer to VehObjforADB1";
CM_ SG_ 398 VehObjforADB7AdbTrkInfo "refer to VehObjforADB1";
CM_ SG_ 398 VehObjforADB7AdbVertAg "refer to VehObjforADB1";
CM_ SG_ 399 VehObjforADB8AdbAbsDist "refer to VehObjforADB1";
CM_ SG_ 399 VehObjforADB8AdbClassn "refer to VehObjforADB1";
CM_ SG_ 399 VehObjforADB8AdbClassnQly "refer to VehObjforADB1";
CM_ SG_ 399 VehObjforADB8AdbDetdQly "refer to VehObjforADB1";
CM_ SG_ 399 VehObjforADB8AdbHozlAg "refer to VehObjforADB1";
CM_ SG_ 399 VehObjforADB8AdbObjDir "refer to VehObjforADB1";
CM_ SG_ 399 VehObjforADB8AdbObjHozlAgSpd "refer to VehObjforADB1";
CM_ SG_ 399 VehObjforADB8AdbObjVertAgSpd "refer to VehObjforADB1";
CM_ SG_ 399 VehObjforADB8AdbTrkInfo "refer to VehObjforADB1";
CM_ SG_ 399 VehObjforADB8AdbVertAg "refer to VehObjforADB1";
CM_ SG_ 64 CameraStsforAHBC "To discribe camera can working or not.";
CM_ SG_ 64 RainLi "Information about rain detection for light activation/deactivation.";
CM_ SG_ 64 VehModMngtGlbSafe1CarModSts1 "CarMode Status";
CM_ SG_ 64 VehModMngtGlbSafe1CarModSubtypWdCarModSubtyp "CarMode substate status";
CM_ SG_ 64 VehModMngtGlbSafe1Chks "Checksum";
CM_ SG_ 64 VehModMngtGlbSafe1Cntr "Counter";
CM_ SG_ 64 VehModMngtGlbSafe1EgyLvlElecMai "Main energy level in the vehicle.";
CM_ SG_ 64 VehModMngtGlbSafe1EgyLvlElecSubtyp "Substate of the energy level in the vehicle.";
CM_ SG_ 64 VehModMngtGlbSafe1FltEgyCnsWdSts "High quiescent current detected by CEM via BMS.";
CM_ SG_ 64 VehModMngtGlbSafe1PwrLvlElecMai "Main Power level in the vehicle.";
CM_ SG_ 64 VehModMngtGlbSafe1PwrLvlElecSubtyp "Substate of the power level in the vehicle.";
CM_ SG_ 64 VehModMngtGlbSafe1UsgModSts "UsageMode Status";
CM_ SG_ 64 WipgAutFrntMod "Information regarding rain sensor operational mode.";
CM_ SG_ 400 SuspPosnVertAgGenQf "External CAN signal for inform the rear angle that are calculated from front and rear body height. This signal are used for head lamp control.";
CM_ SG_ 400 SuspPosnVertAgSuspPosnVertAg "External CAN signal for inform the rear angle that are calculated from front and rear body height. This signal are used for head lamp control.";
CM_ SG_ 400 SuspPosnVertLvlFrnt "Front suspension level";
CM_ SG_ 400 SuspPosnVertLvlFrntQf "Front Qf";
CM_ SG_ 400 SuspPosnVertLvlRe "Rear suspension level";
CM_ SG_ 400 SuspPosnVertLvlReQf "Rear Qf";
CM_ SG_ 1432 CEMdevelpsignalgrouprespFunctiondevpsignalgroup1 "develop signal group response";
CM_ SG_ 1432 CEMdevelpsignalgrouprespFunctiondevpsignalgroup2 "develop signal group response";
CM_ SG_ 1432 CEMdevelpsignalgrouprespFunctiondevpsignalgroup3 "develop signal group response";
CM_ SG_ 1432 CEMdevelpsignalgrouprespFunctiondevpsignalgroup4 "develop signal group response";
CM_ SG_ 1432 CEMdevelpsignalgrouprespFunctiondevpsignalgroup5 "develop signal group response";
CM_ SG_ 1432 CEMdevelpsignalgrouprespFunctiondevpsignalgroup6 "develop signal group response";
CM_ SG_ 1432 CEMdevelpsignalgrouprespFunctiondevpsignalgroup7 "develop signal group response";
CM_ SG_ 1432 CEMdevelpsignalgrouprespFunctiondevpsignalgroup8 "develop signal group response";
CM_ SG_ 1431 CEMdevelpsignalgroupcheckFunctiondevpsignalgroup1 "develop signal group check";
CM_ SG_ 1431 CEMdevelpsignalgroupcheckFunctiondevpsignalgroup2 "develop signal group check";
CM_ SG_ 1431 CEMdevelpsignalgroupcheckFunctiondevpsignalgroup3 "develop signal group check";
CM_ SG_ 1431 CEMdevelpsignalgroupcheckFunctiondevpsignalgroup4 "develop signal group check";
CM_ SG_ 1431 CEMdevelpsignalgroupcheckFunctiondevpsignalgroup5 "develop signal group check";
CM_ SG_ 1431 CEMdevelpsignalgroupcheckFunctiondevpsignalgroup6 "develop signal group check";
CM_ SG_ 1431 CEMdevelpsignalgroupcheckFunctiondevpsignalgroup7 "develop signal group check";
CM_ SG_ 1431 CEMdevelpsignalgroupcheckFunctiondevpsignalgroup8 "develop signal group check";
CM_ SG_ 28 ExtrLiShowActvnReq "Request signal for activating Light show, if the value has been set to on. ";
CM_ SG_ 28 ExtrLiShowFileTxReq "Request signal for transferring sequence table. If the value has been set to on, the parameter of lamp elements can be downloaded from IHU to HCM/RCM. ";
CM_ SG_ 288 DwnLoadDynLitPrmForLedStopLampRi2ContTiPrm "Light Show Continue Time Parameter 1";
CM_ SG_ 288 DwnLoadDynLitPrmForLedStopLampRi2LowBriPrm "Light Show Lower Brightness Parameter 1";
CM_ SG_ 288 DwnLoadDynLitPrmForLedStopLampRi2ModePrm "Light Show Mode Parameter 1";
CM_ SG_ 288 DwnLoadDynLitPrmForLedStopLampRi2OffsTiPrm "Light Show Offset Time Parameter 1";
CM_ SG_ 288 DwnLoadDynLitPrmForLedStopLampRi2Tistamp "Light Show time stamp";
CM_ SG_ 288 DwnLoadDynLitPrmForLedStopLampRi2UpprBriPrm "Light Show Upper Brightness Parameter 1";
CM_ SG_ 289 DwnLoadDynLitPrmLedReFogLampRi2ContTiPrm "Light Show Continue Time Parameter 1";
CM_ SG_ 289 DwnLoadDynLitPrmLedReFogLampRi2LowBriPrm "Light Show Lower Brightness Parameter 1";
CM_ SG_ 289 DwnLoadDynLitPrmLedReFogLampRi2ModePrm "Light Show Mode Parameter 1";
CM_ SG_ 289 DwnLoadDynLitPrmLedReFogLampRi2OffsTiPrm "Light Show Offset Time Parameter 1";
CM_ SG_ 289 DwnLoadDynLitPrmLedReFogLampRi2Tistamp "Light Show time stamp";
CM_ SG_ 289 DwnLoadDynLitPrmLedReFogLampRi2UpprBriPrm "Light Show Upper Brightness Parameter 1";
CM_ SG_ 290 DwnLoadDynLitPrmLedRePosnLampRi2ContTiPrm "Light Show Continue Time Parameter 1";
CM_ SG_ 290 DwnLoadDynLitPrmLedRePosnLampRi2LowBriPrm "Light Show Lower Brightness Parameter 1";
CM_ SG_ 290 DwnLoadDynLitPrmLedRePosnLampRi2ModePrm "Light Show Mode Parameter 1";
CM_ SG_ 290 DwnLoadDynLitPrmLedRePosnLampRi2OffsTiPrm "Light Show Offset Time Parameter 1";
CM_ SG_ 290 DwnLoadDynLitPrmLedRePosnLampRi2Tistamp "Light Show time stamp";
CM_ SG_ 290 DwnLoadDynLitPrmLedRePosnLampRi2UpprBriPrm "Light Show Upper Brightness Parameter 1";
CM_ SG_ 291 DwnLoadDynLitPrmLedReTurnIndcrRi2ContTiPrm "Light Show Continue Time Parameter 1";
CM_ SG_ 291 DwnLoadDynLitPrmLedReTurnIndcrRi2LowBriPrm "Light Show Lower Brightness Parameter 1";
CM_ SG_ 291 DwnLoadDynLitPrmLedReTurnIndcrRi2ModePrm "Light Show Mode Parameter 1";
CM_ SG_ 291 DwnLoadDynLitPrmLedReTurnIndcrRi2OffsTiPrm "Light Show Offset Time Parameter 1";
CM_ SG_ 291 DwnLoadDynLitPrmLedReTurnIndcrRi2Tistamp "Light Show time stamp";
CM_ SG_ 291 DwnLoadDynLitPrmLedReTurnIndcrRi2UpprBriPrm "Light Show Upper Brightness Parameter 1";
CM_ SG_ 292 DwnLoadDynLitPrmForLedMkrLampLe1ContTiPrm "Light Show Continue Time Parameter 1";
CM_ SG_ 292 DwnLoadDynLitPrmForLedMkrLampLe1LowBriPrm "Light Show Lower Brightness Parameter 1";
CM_ SG_ 292 DwnLoadDynLitPrmForLedMkrLampLe1ModePrm "Light Show Mode Parameter 1";
CM_ SG_ 292 DwnLoadDynLitPrmForLedMkrLampLe1OffsTiPrm "Light Show Offset Time Parameter 1";
CM_ SG_ 292 DwnLoadDynLitPrmForLedMkrLampLe1Tistamp "Light Show time stamp";
CM_ SG_ 292 DwnLoadDynLitPrmForLedMkrLampLe1UpprBriPrm "Light Show Upper Brightness Parameter 1";
CM_ SG_ 293 DwnLoadDynLtgPrmForLedLoBeamRiContTiPrm "Light Show Continue Time Parameter 1";
CM_ SG_ 293 DwnLoadDynLtgPrmForLedLoBeamRiLowBriPrm "Light Show Lower Brightness Parameter 1";
CM_ SG_ 293 DwnLoadDynLtgPrmForLedLoBeamRiModePrm "Light Show Mode Parameter 1";
CM_ SG_ 293 DwnLoadDynLtgPrmForLedLoBeamRiOffsTiPrm "Light Show Offset Time Parameter 1";
CM_ SG_ 293 DwnLoadDynLtgPrmForLedLoBeamRiTistamp "Light Show time stamp";
CM_ SG_ 293 DwnLoadDynLtgPrmForLedLoBeamRiUpprBriPrm "Light Show Upper Brightness Parameter 1";
CM_ SG_ 294 DwnLoadDynLitPrmForLedMkrLampLe2ContTiPrm "Light Show Continue Time Parameter 1";
CM_ SG_ 294 DwnLoadDynLitPrmForLedMkrLampLe2LowBriPrm "Light Show Lower Brightness Parameter 1";
CM_ SG_ 294 DwnLoadDynLitPrmForLedMkrLampLe2ModePrm "Light Show Mode Parameter 1";
CM_ SG_ 294 DwnLoadDynLitPrmForLedMkrLampLe2OffsTiPrm "Light Show Offset Time Parameter 1";
CM_ SG_ 294 DwnLoadDynLitPrmForLedMkrLampLe2Tistamp "Light Show time stamp";
CM_ SG_ 294 DwnLoadDynLitPrmForLedMkrLampLe2UpprBriPrm "Light Show Upper Brightness Parameter 1";
CM_ SG_ 295 DwnLoadDynLitPrmForLedMkrLampRi1ContTiPrm "Light Show Continue Time Parameter 1";
CM_ SG_ 295 DwnLoadDynLitPrmForLedMkrLampRi1LowBriPrm "Light Show Lower Brightness Parameter 1";
CM_ SG_ 295 DwnLoadDynLitPrmForLedMkrLampRi1ModePrm "Light Show Mode Parameter 1";
CM_ SG_ 295 DwnLoadDynLitPrmForLedMkrLampRi1OffsTiPrm "Light Show Offset Time Parameter 1";
CM_ SG_ 295 DwnLoadDynLitPrmForLedMkrLampRi1Tistamp "Light Show time stamp";
CM_ SG_ 295 DwnLoadDynLitPrmForLedMkrLampRi1UpprBriPrm "Light Show Upper Brightness Parameter 1";
CM_ SG_ 296 DwnLoadDynLitPrmForLedStopLampLe1ContTiPrm "Light Show Continue Time Parameter 1";
CM_ SG_ 296 DwnLoadDynLitPrmForLedStopLampLe1LowBriPrm "Light Show Lower Brightness Parameter 1";
CM_ SG_ 296 DwnLoadDynLitPrmForLedStopLampLe1ModePrm "Light Show Mode Parameter 1";
CM_ SG_ 296 DwnLoadDynLitPrmForLedStopLampLe1OffsTiPrm "Light Show Offset Time Parameter 1";
CM_ SG_ 296 DwnLoadDynLitPrmForLedStopLampLe1Tistamp "Light Show time stamp";
CM_ SG_ 296 DwnLoadDynLitPrmForLedStopLampLe1UpprBriPrm "Light Show Upper Brightness Parameter 1";
CM_ SG_ 297 DwnLoadDynLitPrmForLedStopLampLe2ContTiPrm "Light Show Continue Time Parameter 1";
CM_ SG_ 297 DwnLoadDynLitPrmForLedStopLampLe2LowBriPrm "Light Show Lower Brightness Parameter 1";
CM_ SG_ 297 DwnLoadDynLitPrmForLedStopLampLe2ModePrm "Light Show Mode Parameter 1";
CM_ SG_ 297 DwnLoadDynLitPrmForLedStopLampLe2OffsTiPrm "Light Show Offset Time Parameter 1";
CM_ SG_ 297 DwnLoadDynLitPrmForLedStopLampLe2Tistamp "Light Show time stamp";
CM_ SG_ 297 DwnLoadDynLitPrmForLedStopLampLe2UpprBriPrm "Light Show Upper Brightness Parameter 1";
CM_ SG_ 298 DwnLoadDynLitPrmForLedStopLampRi1ContTiPrm "Light Show Continue Time Parameter 1";
CM_ SG_ 298 DwnLoadDynLitPrmForLedStopLampRi1LowBriPrm "Light Show Lower Brightness Parameter 1";
CM_ SG_ 298 DwnLoadDynLitPrmForLedStopLampRi1ModePrm "Light Show Mode Parameter 1";
CM_ SG_ 298 DwnLoadDynLitPrmForLedStopLampRi1OffsTiPrm "Light Show Offset Time Parameter 1";
CM_ SG_ 298 DwnLoadDynLitPrmForLedStopLampRi1Tistamp "Light Show time stamp";
CM_ SG_ 298 DwnLoadDynLitPrmForLedStopLampRi1UpprBriPrm "Light Show Upper Brightness Parameter 1";
CM_ SG_ 299 DwnLoadDynLitPrmLedReFogLampLe1ContTiPrm "Light Show Continue Time Parameter 1";
CM_ SG_ 299 DwnLoadDynLitPrmLedReFogLampLe1LowBriPrm "Light Show Lower Brightness Parameter 1";
CM_ SG_ 299 DwnLoadDynLitPrmLedReFogLampLe1ModePrm "Light Show Mode Parameter 1";
CM_ SG_ 299 DwnLoadDynLitPrmLedReFogLampLe1OffsTiPrm "Light Show Offset Time Parameter 1";
CM_ SG_ 299 DwnLoadDynLitPrmLedReFogLampLe1Tistamp "Light Show time stamp";
CM_ SG_ 299 DwnLoadDynLitPrmLedReFogLampLe1UpprBriPrm "Light Show Upper Brightness Parameter 1";
CM_ SG_ 300 DwnLoadDynLitPrmLedReFogLampLe2ContTiPrm "Light Show Continue Time Parameter 1";
CM_ SG_ 300 DwnLoadDynLitPrmLedReFogLampLe2LowBriPrm "Light Show Lower Brightness Parameter 1";
CM_ SG_ 300 DwnLoadDynLitPrmLedReFogLampLe2ModePrm "Light Show Mode Parameter 1";
CM_ SG_ 300 DwnLoadDynLitPrmLedReFogLampLe2OffsTiPrm "Light Show Offset Time Parameter 1";
CM_ SG_ 300 DwnLoadDynLitPrmLedReFogLampLe2Tistamp "Light Show time stamp";
CM_ SG_ 300 DwnLoadDynLitPrmLedReFogLampLe2UpprBriPrm "Light Show Upper Brightness Parameter 1";
CM_ SG_ 301 DwnLoadDynLitPrmLedReFogLampRi1ContTiPrm "Light Show Continue Time Parameter 1";
CM_ SG_ 301 DwnLoadDynLitPrmLedReFogLampRi1LowBriPrm "Light Show Lower Brightness Parameter 1";
CM_ SG_ 301 DwnLoadDynLitPrmLedReFogLampRi1ModePrm "Light Show Mode Parameter 1";
CM_ SG_ 301 DwnLoadDynLitPrmLedReFogLampRi1OffsTiPrm "Light Show Offset Time Parameter 1";
CM_ SG_ 301 DwnLoadDynLitPrmLedReFogLampRi1Tistamp "Light Show time stamp";
CM_ SG_ 301 DwnLoadDynLitPrmLedReFogLampRi1UpprBriPrm "Light Show Upper Brightness Parameter 1";
CM_ SG_ 302 DwnLoadDynLitPrmLedRePosnLampLe1ContTiPrm "Light Show Continue Time Parameter 1";
CM_ SG_ 302 DwnLoadDynLitPrmLedRePosnLampLe1LowBriPrm "Light Show Lower Brightness Parameter 1";
CM_ SG_ 302 DwnLoadDynLitPrmLedRePosnLampLe1ModePrm "Light Show Mode Parameter 1";
CM_ SG_ 302 DwnLoadDynLitPrmLedRePosnLampLe1OffsTiPrm "Light Show Offset Time Parameter 1";
CM_ SG_ 302 DwnLoadDynLitPrmLedRePosnLampLe1Tistamp "Light Show time stamp";
CM_ SG_ 302 DwnLoadDynLitPrmLedRePosnLampLe1UpprBriPrm "Light Show Upper Brightness Parameter 1";
CM_ SG_ 303 DwnLoadDynLitPrmLedRePosnLampLe2ContTiPrm "Light Show Continue Time Parameter 1";
CM_ SG_ 303 DwnLoadDynLitPrmLedRePosnLampLe2LowBriPrm "Light Show Lower Brightness Parameter 1";
CM_ SG_ 303 DwnLoadDynLitPrmLedRePosnLampLe2ModePrm "Light Show Mode Parameter 1";
CM_ SG_ 303 DwnLoadDynLitPrmLedRePosnLampLe2OffsTiPrm "Light Show Offset Time Parameter 1";
CM_ SG_ 303 DwnLoadDynLitPrmLedRePosnLampLe2Tistamp "Light Show time stamp";
CM_ SG_ 303 DwnLoadDynLitPrmLedRePosnLampLe2UpprBriPrm "Light Show Upper Brightness Parameter 1";
CM_ SG_ 304 DwnLoadDynLitPrmLedRePosnLampRi1ContTiPrm "Light Show Continue Time Parameter 1";
CM_ SG_ 304 DwnLoadDynLitPrmLedRePosnLampRi1LowBriPrm "Light Show Lower Brightness Parameter 1";
CM_ SG_ 304 DwnLoadDynLitPrmLedRePosnLampRi1ModePrm "Light Show Mode Parameter 1";
CM_ SG_ 304 DwnLoadDynLitPrmLedRePosnLampRi1OffsTiPrm "Light Show Offset Time Parameter 1";
CM_ SG_ 304 DwnLoadDynLitPrmLedRePosnLampRi1Tistamp "Light Show time stamp";
CM_ SG_ 304 DwnLoadDynLitPrmLedRePosnLampRi1UpprBriPrm "Light Show Upper Brightness Parameter 1";
CM_ SG_ 305 DwnLoadDynLitPrmLedReTurnIndcrLe1ContTiPrm "Light Show Continue Time Parameter 1";
CM_ SG_ 305 DwnLoadDynLitPrmLedReTurnIndcrLe1LowBriPrm "Light Show Lower Brightness Parameter 1";
CM_ SG_ 305 DwnLoadDynLitPrmLedReTurnIndcrLe1ModePrm "Light Show Mode Parameter 1";
CM_ SG_ 305 DwnLoadDynLitPrmLedReTurnIndcrLe1OffsTiPrm "Light Show Offset Time Parameter 1";
CM_ SG_ 305 DwnLoadDynLitPrmLedReTurnIndcrLe1Tistamp "Light Show time stamp";
CM_ SG_ 305 DwnLoadDynLitPrmLedReTurnIndcrLe1UpprBriPrm "Light Show Upper Brightness Parameter 1";
CM_ SG_ 306 DwnLoadDynLitPrmLedReTurnIndcrLe2ContTiPrm "Light Show Continue Time Parameter 1";
CM_ SG_ 306 DwnLoadDynLitPrmLedReTurnIndcrLe2LowBriPrm "Light Show Lower Brightness Parameter 1";
CM_ SG_ 306 DwnLoadDynLitPrmLedReTurnIndcrLe2ModePrm "Light Show Mode Parameter 1";
CM_ SG_ 306 DwnLoadDynLitPrmLedReTurnIndcrLe2OffsTiPrm "Light Show Offset Time Parameter 1";
CM_ SG_ 306 DwnLoadDynLitPrmLedReTurnIndcrLe2Tistamp "Light Show time stamp";
CM_ SG_ 306 DwnLoadDynLitPrmLedReTurnIndcrLe2UpprBriPrm "Light Show Upper Brightness Parameter 1";
CM_ SG_ 307 DwnLoadDynLitPrmLedReTurnIndcrRi1ContTiPrm "Light Show Continue Time Parameter 1";
CM_ SG_ 307 DwnLoadDynLitPrmLedReTurnIndcrRi1LowBriPrm "Light Show Lower Brightness Parameter 1";
CM_ SG_ 307 DwnLoadDynLitPrmLedReTurnIndcrRi1ModePrm "Light Show Mode Parameter 1";
CM_ SG_ 307 DwnLoadDynLitPrmLedReTurnIndcrRi1OffsTiPrm "Light Show Offset Time Parameter 1";
CM_ SG_ 307 DwnLoadDynLitPrmLedReTurnIndcrRi1Tistamp "Light Show time stamp";
CM_ SG_ 307 DwnLoadDynLitPrmLedReTurnIndcrRi1UpprBriPrm "Light Show Upper Brightness Parameter 1";
CM_ SG_ 308 DwnLoadDynLitPrmLedRvsgLampLe1ContTiPrm "Light Show Continue Time Parameter 1";
CM_ SG_ 308 DwnLoadDynLitPrmLedRvsgLampLe1LowBriPrm "Light Show Lower Brightness Parameter 1";
CM_ SG_ 308 DwnLoadDynLitPrmLedRvsgLampLe1ModePrm "Light Show Mode Parameter 1";
CM_ SG_ 308 DwnLoadDynLitPrmLedRvsgLampLe1OffsTiPrm "Light Show Offset Time Parameter 1";
CM_ SG_ 308 DwnLoadDynLitPrmLedRvsgLampLe1Tistamp "Light Show time stamp";
CM_ SG_ 308 DwnLoadDynLitPrmLedRvsgLampLe1UpprBriPrm "Light Show Upper Brightness Parameter 1";
CM_ SG_ 309 DwnLoadDynLitPrmLedRvsgLampLe2ContTiPrm "Light Show Continue Time Parameter 1";
CM_ SG_ 309 DwnLoadDynLitPrmLedRvsgLampLe2LowBriPrm "Light Show Lower Brightness Parameter 1";
CM_ SG_ 309 DwnLoadDynLitPrmLedRvsgLampLe2ModePrm "Light Show Mode Parameter 1";
CM_ SG_ 309 DwnLoadDynLitPrmLedRvsgLampLe2OffsTiPrm "Light Show Offset Time Parameter 1";
CM_ SG_ 309 DwnLoadDynLitPrmLedRvsgLampLe2Tistamp "Light Show time stamp";
CM_ SG_ 309 DwnLoadDynLitPrmLedRvsgLampLe2UpprBriPrm "Light Show Upper Brightness Parameter 1";
CM_ SG_ 310 DwnLoadDynLitPrmLedRvsgLampRi1ContTiPrm "Light Show Continue Time Parameter 1";
CM_ SG_ 310 DwnLoadDynLitPrmLedRvsgLampRi1LowBriPrm "Light Show Lower Brightness Parameter 1";
CM_ SG_ 310 DwnLoadDynLitPrmLedRvsgLampRi1ModePrm "Light Show Mode Parameter 1";
CM_ SG_ 310 DwnLoadDynLitPrmLedRvsgLampRi1OffsTiPrm "Light Show Offset Time Parameter 1";
CM_ SG_ 310 DwnLoadDynLitPrmLedRvsgLampRi1Tistamp "Light Show time stamp";
CM_ SG_ 310 DwnLoadDynLitPrmLedRvsgLampRi1UpprBriPrm "Light Show Upper Brightness Parameter 1";
CM_ SG_ 120 ActvnOfReLogoLamp "The signal indicates the Rear Logo Lamp's activate/deactivate request from Other subsystem to Exterior Light subsystem. 1= Activate, 0 = Deactivate.";
CM_ SG_ 120 LvlgSwtSetReqADModCtrlInhbn "0.LvlgSwtSetReq.Level0
1.LvlgSwtSetReq.Level1
2.LvlgSwtSetReq.Level2
3.LvlgSwtSetReq.Level3
4.LvlgSwtSetReq.Level4
5.LvlgSwtSetReq.Level5";
CM_ SG_ 120 LvlgSwtSetReqChks "checksum";
CM_ SG_ 120 LvlgSwtSetReqCntr "counter";
CM_ SG_ 120 OutdBriChks "Input for controlling lights on and off automatically. Checksum";
CM_ SG_ 120 OutdBriCntr "Input for controlling lights on and off automatically. Counter";
CM_ SG_ 120 OutdBriSts "Input for controlling lights on and off automatically. Status information.";
CM_ SG_ 311 DwnLoadDynLitPrmForLedHiBeamLeContTiPrm "Light Show Continue Time Parameter 1";
CM_ SG_ 311 DwnLoadDynLitPrmForLedHiBeamLeLowBriPrm "Light Show Lower Brightness Parameter 1";
CM_ SG_ 311 DwnLoadDynLitPrmForLedHiBeamLeModePrm "Light Show Mode Parameter 1";
CM_ SG_ 311 DwnLoadDynLitPrmForLedHiBeamLeOffsTiPrm "Light Show Offset time Parameter 1";
CM_ SG_ 311 DwnLoadDynLitPrmForLedHiBeamLeTistamp "Light Show time stamp";
CM_ SG_ 311 DwnLoadDynLitPrmForLedHiBeamLeUpprBriPrm "Light Show Upper Brightness Parameter 1";

// Attribute definitions
BA_DEF_  "Baudrate" INT 1000 1000000; // [bps]
BA_DEF_ BO_ "GenMsgSendType" ENUM "cyclic", "spontaneous", "not-used", "not-used", "not-used", "cyclicAndSpontaneous", "not-used", "cyclicIfActive", "NoMsgSendType"; // [us]
BA_DEF_ BO_ "GenMsgCycleTime" INT 0 65536; // [ms]
BA_DEF_ BO_ "GenMsgStartDelayTime" INT 0 65536; // [ms]
BA_DEF_ BO_ "GenMsgDelayTime" INT 0 65536; // [ms]
BA_DEF_ SG_ "GenSigSendType" ENUM "Cyclic","OnWrite","OnWriteWithRepetition","OnChange","OnChangeWithRepetition","IfActive","IfActiveWithRepetition","NoSigSendType";
BA_DEF_ SG_ "GenSigStartValue" HEX 0 80000000;
BA_DEF_ BU_ "NmAsrNodeIdentifier" INT 0 255;
BA_DEF_  "DBName" STRING;
BA_DEF_  "BusType" STRING;
BA_DEF_  "ProtocolType" STRING;
BA_DEF_ BO_ "GenMsgILSupport" ENUM "No","Yes";
BA_DEF_ BO_ "NmAsrMessage" ENUM "No","Yes";
BA_DEF_  "NmAsrBaseAddress" HEX 0 536870911;
BA_DEF_  "NmAsrMessageCount" INT 0 255;
BA_DEF_ BU_ "NodeLayerModules" STRING;
BA_DEF_ BU_ "NmAsrNode" ENUM "No","Yes";
BA_DEF_ BU_ "ILused" ENUM "No","Yes";
BA_DEF_ SG_ "GenSigFuncType" ENUM "NoFunction","n/a","n/a","n/a","n/a","n/a","n/a","n/a","n/a","n/a","n/a","n/a","n/a","n/a","n/a","CHK","CNTR","n/a","n/a","n/a","CNTR_AR_01","CRC_AR_01_BOTH","CRC_AR_01_ALT","CRC_AR_01_LOW","CRC_AR_01_NIBBLE","CNTR_AR_04","CRC_AR_04A","CNTR_AR_05","CRC_AR_05";
BA_DEF_ SG_ "GenSigDataID" STRING;
BA_DEF_ SG_ "SigGroup" STRING;

BA_DEF_DEF_ "GenSigStartValue" 0;
BA_DEF_DEF_ "GenSigSendType" "NoSigSendType";
BA_DEF_DEF_ "DBName" "";
BA_DEF_DEF_ "BusType" "";
BA_DEF_DEF_ "ProtocolType" "";
BA_DEF_DEF_ "GenMsgCycleTime" 0;
BA_DEF_DEF_ "GenMsgDelayTime" 0;
BA_DEF_DEF_ "GenMsgStartDelayTime" 0;
BA_DEF_DEF_ "GenMsgSendType" "NoMsgSendType";
BA_DEF_DEF_ "GenMsgILSupport" "Yes";
BA_DEF_DEF_ "NmAsrMessage" "No";
BA_DEF_DEF_ "NmAsrBaseAddress" 1280;
BA_DEF_DEF_ "NmAsrMessageCount" 64;
BA_DEF_DEF_ "NodeLayerModules" "CANoeILNLSPA.dll";
BA_DEF_DEF_ "NmAsrNode" "No";
BA_DEF_DEF_ "NmAsrNodeIdentifier" 0;
BA_DEF_DEF_ "ILused" "Yes";
BA_DEF_DEF_ "GenSigFuncType" "NoFunction";
BA_DEF_DEF_ "GenSigDataID" "";
BA_DEF_DEF_ "SigGroup" "";

// Network
BA_ "DBName" "BodyExposedCAN";
BA_ "BusType" "CAN";
BA_ "ProtocolType" "CAN";
BA_ "Baudrate" 500000;
// ECU: CEM
BA_ "NmAsrNodeIdentifier" BU_ CEM 42;
BA_ "NmAsrNode" BU_ CEM 1;
BA_ "NodeLayerModules" BU_ CEM "CANoeILNLSPA.dll,AsrNM33.dll";
// ECU: ETC
BA_ "ILused" BU_ ETC 0;
// ECU: HCML
BA_ "NmAsrNodeIdentifier" BU_ HCML 49;
BA_ "NmAsrNode" BU_ HCML 1;
BA_ "NodeLayerModules" BU_ HCML "CANoeILNLSPA.dll,AsrNM33.dll";
// ECU: HCMR
BA_ "NmAsrNodeIdentifier" BU_ HCMR 50;
BA_ "NmAsrNode" BU_ HCMR 1;
BA_ "NodeLayerModules" BU_ HCMR "CANoeILNLSPA.dll,AsrNM33.dll";
// ECU: RCML
BA_ "NmAsrNodeIdentifier" BU_ RCML 51;
BA_ "NmAsrNode" BU_ RCML 1;
BA_ "NodeLayerModules" BU_ RCML "CANoeILNLSPA.dll,AsrNM33.dll";
// ECU: RCMM
BA_ "NmAsrNodeIdentifier" BU_ RCMM 53;
BA_ "NmAsrNode" BU_ RCMM 1;
BA_ "NodeLayerModules" BU_ RCMM "CANoeILNLSPA.dll,AsrNM33.dll";
// ECU: RCMR
BA_ "NmAsrNodeIdentifier" BU_ RCMR 52;
BA_ "NmAsrNode" BU_ RCMR 1;
BA_ "NodeLayerModules" BU_ RCMR "CANoeILNLSPA.dll,AsrNM33.dll";
// Frame: CemBodyCanExposedNMFr
BA_ "GenMsgSendType" BO_ 1322 1;
BA_ "GenMsgDelayTime" BO_ 1322 20.000;
BA_ "GenMsgILSupport" BO_ 1322 0;
BA_ "NmAsrMessage" BO_ 1322 1;
// Frame: CemBodyExpoCommonFr01
BA_ "GenMsgSendType" BO_ 82 0;
BA_ "GenMsgCycleTime" BO_ 82 10.000;
BA_ "GenSigSendType" SG_ 82 AutWinWipgCmd 0;
BA_ "GenSigSendType" SG_ 82 LiOprnMod 0;
BA_ "GenSigSendType" SG_ 82 SteerWhlSnsrAg 0;
BA_ "GenSigSendType" SG_ 82 SteerWhlSnsrAgSpd 0;
BA_ "GenSigSendType" SG_ 82 SteerWhlSnsrChks 0;
BA_ "GenSigFuncType" SG_ 82 SteerWhlSnsrChks 15;
BA_ "GenSigDataID" SG_ 82 SteerWhlSnsrChks "0x33";
BA_ "GenSigSendType" SG_ 82 SteerWhlSnsrCntr 0;
BA_ "GenSigFuncType" SG_ 82 SteerWhlSnsrCntr 16;
BA_ "GenSigStartValue" SG_ 82 SteerWhlSnsrQf 1;
BA_ "GenSigSendType" SG_ 82 SteerWhlSnsrQf 0;
// Frame: CemBodyExpoCommonFr02
BA_ "GenMsgSendType" BO_ 768 0;
BA_ "GenMsgCycleTime" BO_ 768 45.000;
BA_ "GenSigSendType" SG_ 768 ActvnOfRvsg 0;
BA_ "GenSigSendType" SG_ 768 YawRateReqdByDrvr 0;
// Frame: CEMBodyExpoCommonFr04
BA_ "GenMsgSendType" BO_ 80 0;
BA_ "GenMsgCycleTime" BO_ 80 40.000;
BA_ "GenSigSendType" SG_ 80 VehSpdLgtA 0;
BA_ "GenSigSendType" SG_ 80 VehSpdLgtChks 0;
BA_ "GenSigFuncType" SG_ 80 VehSpdLgtChks 15;
BA_ "GenSigDataID" SG_ 80 VehSpdLgtChks "0x37";
BA_ "GenSigSendType" SG_ 80 VehSpdLgtCntr 0;
BA_ "GenSigFuncType" SG_ 80 VehSpdLgtCntr 16;
BA_ "GenSigStartValue" SG_ 80 VehSpdLgtQf 1;
BA_ "GenSigSendType" SG_ 80 VehSpdLgtQf 0;
// Frame: CemBodyExpoCommonFr05
BA_ "GenMsgSendType" BO_ 384 1;
BA_ "GenMsgDelayTime" BO_ 384 120.000;
BA_ "GenSigSendType" SG_ 384 VehCfgPrmBlkIDBytePosn1 1;
BA_ "GenSigSendType" SG_ 384 VehCfgPrmCCPBytePosn2 1;
BA_ "GenSigSendType" SG_ 384 VehCfgPrmCCPBytePosn3 1;
BA_ "GenSigSendType" SG_ 384 VehCfgPrmCCPBytePosn4 1;
BA_ "GenSigSendType" SG_ 384 VehCfgPrmCCPBytePosn5 1;
BA_ "GenSigSendType" SG_ 384 VehCfgPrmCCPBytePosn6 1;
BA_ "GenSigSendType" SG_ 384 VehCfgPrmCCPBytePosn7 1;
BA_ "GenSigSendType" SG_ 384 VehCfgPrmCCPBytePosn8 1;
// Frame: CEMBodyExpoCommonFr06
BA_ "GenMsgSendType" BO_ 512 0;
BA_ "GenMsgCycleTime" BO_ 512 50.000;
BA_ "GenSigSendType" SG_ 512 BkpOfDstTrvld 0;
BA_ "GenSigSendType" SG_ 512 ExtrLiRlyPwrDwn 0;
BA_ "GenSigSendType" SG_ 512 VehBattUSysU 0;
BA_ "GenSigStartValue" SG_ 512 VehBattUSysUQf 1;
BA_ "GenSigSendType" SG_ 512 VehBattUSysUQf 0;
// Frame: CEMBodyExpoCommonFr07
BA_ "GenMsgSendType" BO_ 544 0;
BA_ "GenMsgCycleTime" BO_ 544 60.000;
BA_ "GenSigSendType" SG_ 544 ActnOfLedGrilleLamp 0;
BA_ "GenSigSendType" SG_ 544 Body2CntrForMissCom 0;
BA_ "GenSigSendType" SG_ 544 CarTiGlb 0;
BA_ "GenSigSendType" SG_ 544 TrSts 0;
// Frame: CemBodyExpoCommonFr08
BA_ "GenMsgSendType" BO_ 128 0;
BA_ "GenMsgCycleTime" BO_ 128 20.000;
BA_ "GenSigSendType" SG_ 128 AccrPedlRatAccrPedlRat 0;
BA_ "GenSigSendType" SG_ 128 AccrPedlRatChks 0;
BA_ "GenSigFuncType" SG_ 128 AccrPedlRatChks 15;
BA_ "GenSigDataID" SG_ 128 AccrPedlRatChks "0x364";
BA_ "GenSigSendType" SG_ 128 AccrPedlRatCntr 0;
BA_ "GenSigFuncType" SG_ 128 AccrPedlRatCntr 16;
BA_ "GenSigStartValue" SG_ 128 AmbTRawAmbTVal 700;
BA_ "GenSigSendType" SG_ 128 AmbTRawAmbTVal 0;
BA_ "GenSigSendType" SG_ 128 AmbTRawQly 0;
BA_ "GenSigSendType" SG_ 128 BrkPedlSnsrChks 0;
BA_ "GenSigFuncType" SG_ 128 BrkPedlSnsrChks 15;
BA_ "GenSigDataID" SG_ 128 BrkPedlSnsrChks "0xAF";
BA_ "GenSigSendType" SG_ 128 BrkPedlSnsrCntr 0;
BA_ "GenSigFuncType" SG_ 128 BrkPedlSnsrCntr 16;
BA_ "GenSigSendType" SG_ 128 BrkPedlSnsrQf 0;
BA_ "GenSigSendType" SG_ 128 BrkPedlSnsrSt 0;
BA_ "GenSigSendType" SG_ 128 TooManyCars 0;
// Frame: CemBodyExpoCommonFr09
BA_ "GenMsgSendType" BO_ 387 1;
BA_ "GenMsgDelayTime" BO_ 387 120.000;
BA_ "GenSigSendType" SG_ 387 VehCfgPrmExtBlkIDBytePosn1 1;
BA_ "GenSigSendType" SG_ 387 VehCfgPrmExtCCPBytePosn2 1;
BA_ "GenSigSendType" SG_ 387 VehCfgPrmExtCCPBytePosn3 1;
BA_ "GenSigSendType" SG_ 387 VehCfgPrmExtCCPBytePosn4 1;
BA_ "GenSigSendType" SG_ 387 VehCfgPrmExtCCPBytePosn5 1;
BA_ "GenSigSendType" SG_ 387 VehCfgPrmExtCCPBytePosn6 1;
BA_ "GenSigSendType" SG_ 387 VehCfgPrmExtCCPBytePosn7 1;
BA_ "GenSigSendType" SG_ 387 VehCfgPrmExtCCPBytePosn8 1;
// Frame: CemBodyExpoCommonFr10
BA_ "GenMsgSendType" BO_ 389 0;
BA_ "GenMsgCycleTime" BO_ 389 45.000;
BA_ "GenSigSendType" SG_ 389 TrafficSignForADB1AdbAbsDist 0;
BA_ "GenSigSendType" SG_ 389 TrafficSignForADB1AdbDetdQly 0;
BA_ "GenSigStartValue" SG_ 389 TrafficSignForADB1AdbHozlAg 800;
BA_ "GenSigSendType" SG_ 389 TrafficSignForADB1AdbHozlAg 0;
BA_ "GenSigStartValue" SG_ 389 TrafficSignForADB1AdbObjHozlAgSpd 2880;
BA_ "GenSigSendType" SG_ 389 TrafficSignForADB1AdbObjHozlAgSpd 0;
BA_ "GenSigStartValue" SG_ 389 TrafficSignForADB1AdbObjVertAgSpd 720;
BA_ "GenSigSendType" SG_ 389 TrafficSignForADB1AdbObjVertAgSpd 0;
BA_ "GenSigSendType" SG_ 389 TrafficSignForADB1AdbTrkInfo 0;
BA_ "GenSigStartValue" SG_ 389 TrafficSignForADB1AdbVertAg 75;
BA_ "GenSigSendType" SG_ 389 TrafficSignForADB1AdbVertAg 0;
// Frame: CemBodyExpoCommonFr11
BA_ "GenMsgSendType" BO_ 390 0;
BA_ "GenMsgCycleTime" BO_ 390 45.000;
BA_ "GenSigSendType" SG_ 390 TrafficSignForADB2AdbAbsDist 0;
BA_ "GenSigSendType" SG_ 390 TrafficSignForADB2AdbDetdQly 0;
BA_ "GenSigStartValue" SG_ 390 TrafficSignForADB2AdbHozlAg 800;
BA_ "GenSigSendType" SG_ 390 TrafficSignForADB2AdbHozlAg 0;
BA_ "GenSigStartValue" SG_ 390 TrafficSignForADB2AdbObjHozlAgSpd 2880;
BA_ "GenSigSendType" SG_ 390 TrafficSignForADB2AdbObjHozlAgSpd 0;
BA_ "GenSigStartValue" SG_ 390 TrafficSignForADB2AdbObjVertAgSpd 720;
BA_ "GenSigSendType" SG_ 390 TrafficSignForADB2AdbObjVertAgSpd 0;
BA_ "GenSigSendType" SG_ 390 TrafficSignForADB2AdbTrkInfo 0;
BA_ "GenSigStartValue" SG_ 390 TrafficSignForADB2AdbVertAg 75;
BA_ "GenSigSendType" SG_ 390 TrafficSignForADB2AdbVertAg 0;
// Frame: CemBodyExpoCommonFr12
BA_ "GenMsgSendType" BO_ 391 0;
BA_ "GenMsgCycleTime" BO_ 391 45.000;
BA_ "GenSigSendType" SG_ 391 VehObjforAHBAdbAbsDist 0;
BA_ "GenSigSendType" SG_ 391 VehObjforAHBAdbClassn 0;
BA_ "GenSigSendType" SG_ 391 VehObjforAHBAdbClassnQly 0;
BA_ "GenSigSendType" SG_ 391 VehObjforAHBAdbDetdQly 0;
BA_ "GenSigStartValue" SG_ 391 VehObjforAHBAdbHozlAg 800;
BA_ "GenSigSendType" SG_ 391 VehObjforAHBAdbHozlAg 0;
BA_ "GenSigSendType" SG_ 391 VehObjforAHBAdbObjDir 0;
BA_ "GenSigStartValue" SG_ 391 VehObjforAHBAdbObjHozlAgSpd 2880;
BA_ "GenSigSendType" SG_ 391 VehObjforAHBAdbObjHozlAgSpd 0;
BA_ "GenSigStartValue" SG_ 391 VehObjforAHBAdbObjVertAgSpd 720;
BA_ "GenSigSendType" SG_ 391 VehObjforAHBAdbObjVertAgSpd 0;
BA_ "GenSigSendType" SG_ 391 VehObjforAHBAdbTrkInfo 0;
BA_ "GenSigStartValue" SG_ 391 VehObjforAHBAdbVertAg 75;
BA_ "GenSigSendType" SG_ 391 VehObjforAHBAdbVertAg 0;
// Frame: CemBodyExpoCommonFr13
BA_ "GenMsgSendType" BO_ 392 0;
BA_ "GenMsgCycleTime" BO_ 392 45.000;
BA_ "GenSigSendType" SG_ 392 VehObjforADB1AdbAbsDist 0;
BA_ "GenSigSendType" SG_ 392 VehObjforADB1AdbClassn 0;
BA_ "GenSigSendType" SG_ 392 VehObjforADB1AdbClassnQly 0;
BA_ "GenSigSendType" SG_ 392 VehObjforADB1AdbDetdQly 0;
BA_ "GenSigStartValue" SG_ 392 VehObjforADB1AdbHozlAg 800;
BA_ "GenSigSendType" SG_ 392 VehObjforADB1AdbHozlAg 0;
BA_ "GenSigSendType" SG_ 392 VehObjforADB1AdbObjDir 0;
BA_ "GenSigStartValue" SG_ 392 VehObjforADB1AdbObjHozlAgSpd 2880;
BA_ "GenSigSendType" SG_ 392 VehObjforADB1AdbObjHozlAgSpd 0;
BA_ "GenSigStartValue" SG_ 392 VehObjforADB1AdbObjVertAgSpd 720;
BA_ "GenSigSendType" SG_ 392 VehObjforADB1AdbObjVertAgSpd 0;
BA_ "GenSigSendType" SG_ 392 VehObjforADB1AdbTrkInfo 0;
BA_ "GenSigStartValue" SG_ 392 VehObjforADB1AdbVertAg 75;
BA_ "GenSigSendType" SG_ 392 VehObjforADB1AdbVertAg 0;
// Frame: CemBodyExpoCommonFr14
BA_ "GenMsgSendType" BO_ 393 0;
BA_ "GenMsgCycleTime" BO_ 393 45.000;
BA_ "GenSigSendType" SG_ 393 VehObjforADB2AdbAbsDist 0;
BA_ "GenSigSendType" SG_ 393 VehObjforADB2AdbClassn 0;
BA_ "GenSigSendType" SG_ 393 VehObjforADB2AdbClassnQly 0;
BA_ "GenSigSendType" SG_ 393 VehObjforADB2AdbDetdQly 0;
BA_ "GenSigStartValue" SG_ 393 VehObjforADB2AdbHozlAg 800;
BA_ "GenSigSendType" SG_ 393 VehObjforADB2AdbHozlAg 0;
BA_ "GenSigSendType" SG_ 393 VehObjforADB2AdbObjDir 0;
BA_ "GenSigStartValue" SG_ 393 VehObjforADB2AdbObjHozlAgSpd 2880;
BA_ "GenSigSendType" SG_ 393 VehObjforADB2AdbObjHozlAgSpd 0;
BA_ "GenSigStartValue" SG_ 393 VehObjforADB2AdbObjVertAgSpd 720;
BA_ "GenSigSendType" SG_ 393 VehObjforADB2AdbObjVertAgSpd 0;
BA_ "GenSigSendType" SG_ 393 VehObjforADB2AdbTrkInfo 0;
BA_ "GenSigStartValue" SG_ 393 VehObjforADB2AdbVertAg 75;
BA_ "GenSigSendType" SG_ 393 VehObjforADB2AdbVertAg 0;
// Frame: CemBodyExpoCommonFr15
BA_ "GenMsgSendType" BO_ 394 0;
BA_ "GenMsgCycleTime" BO_ 394 45.000;
BA_ "GenSigSendType" SG_ 394 VehObjforADB3AdbAbsDist 0;
BA_ "GenSigSendType" SG_ 394 VehObjforADB3AdbClassn 0;
BA_ "GenSigSendType" SG_ 394 VehObjforADB3AdbClassnQly 0;
BA_ "GenSigSendType" SG_ 394 VehObjforADB3AdbDetdQly 0;
BA_ "GenSigStartValue" SG_ 394 VehObjforADB3AdbHozlAg 800;
BA_ "GenSigSendType" SG_ 394 VehObjforADB3AdbHozlAg 0;
BA_ "GenSigSendType" SG_ 394 VehObjforADB3AdbObjDir 0;
BA_ "GenSigStartValue" SG_ 394 VehObjforADB3AdbObjHozlAgSpd 2880;
BA_ "GenSigSendType" SG_ 394 VehObjforADB3AdbObjHozlAgSpd 0;
BA_ "GenSigStartValue" SG_ 394 VehObjforADB3AdbObjVertAgSpd 720;
BA_ "GenSigSendType" SG_ 394 VehObjforADB3AdbObjVertAgSpd 0;
BA_ "GenSigSendType" SG_ 394 VehObjforADB3AdbTrkInfo 0;
BA_ "GenSigStartValue" SG_ 394 VehObjforADB3AdbVertAg 75;
BA_ "GenSigSendType" SG_ 394 VehObjforADB3AdbVertAg 0;
// Frame: CemBodyExpoCommonFr16
BA_ "GenMsgSendType" BO_ 395 0;
BA_ "GenMsgCycleTime" BO_ 395 45.000;
BA_ "GenSigSendType" SG_ 395 VehObjforADB4AdbAbsDist 0;
BA_ "GenSigSendType" SG_ 395 VehObjforADB4AdbClassn 0;
BA_ "GenSigSendType" SG_ 395 VehObjforADB4AdbClassnQly 0;
BA_ "GenSigSendType" SG_ 395 VehObjforADB4AdbDetdQly 0;
BA_ "GenSigStartValue" SG_ 395 VehObjforADB4AdbHozlAg 800;
BA_ "GenSigSendType" SG_ 395 VehObjforADB4AdbHozlAg 0;
BA_ "GenSigSendType" SG_ 395 VehObjforADB4AdbObjDir 0;
BA_ "GenSigStartValue" SG_ 395 VehObjforADB4AdbObjHozlAgSpd 2880;
BA_ "GenSigSendType" SG_ 395 VehObjforADB4AdbObjHozlAgSpd 0;
BA_ "GenSigStartValue" SG_ 395 VehObjforADB4AdbObjVertAgSpd 720;
BA_ "GenSigSendType" SG_ 395 VehObjforADB4AdbObjVertAgSpd 0;
BA_ "GenSigSendType" SG_ 395 VehObjforADB4AdbTrkInfo 0;
BA_ "GenSigStartValue" SG_ 395 VehObjforADB4AdbVertAg 75;
BA_ "GenSigSendType" SG_ 395 VehObjforADB4AdbVertAg 0;
// Frame: CemBodyExpoCommonFr17
BA_ "GenMsgSendType" BO_ 396 0;
BA_ "GenMsgCycleTime" BO_ 396 45.000;
BA_ "GenSigSendType" SG_ 396 VehObjforADB5AdbAbsDist 0;
BA_ "GenSigSendType" SG_ 396 VehObjforADB5AdbClassn 0;
BA_ "GenSigSendType" SG_ 396 VehObjforADB5AdbClassnQly 0;
BA_ "GenSigSendType" SG_ 396 VehObjforADB5AdbDetdQly 0;
BA_ "GenSigStartValue" SG_ 396 VehObjforADB5AdbHozlAg 800;
BA_ "GenSigSendType" SG_ 396 VehObjforADB5AdbHozlAg 0;
BA_ "GenSigSendType" SG_ 396 VehObjforADB5AdbObjDir 0;
BA_ "GenSigStartValue" SG_ 396 VehObjforADB5AdbObjHozlAgSpd 2880;
BA_ "GenSigSendType" SG_ 396 VehObjforADB5AdbObjHozlAgSpd 0;
BA_ "GenSigStartValue" SG_ 396 VehObjforADB5AdbObjVertAgSpd 720;
BA_ "GenSigSendType" SG_ 396 VehObjforADB5AdbObjVertAgSpd 0;
BA_ "GenSigSendType" SG_ 396 VehObjforADB5AdbTrkInfo 0;
BA_ "GenSigStartValue" SG_ 396 VehObjforADB5AdbVertAg 75;
BA_ "GenSigSendType" SG_ 396 VehObjforADB5AdbVertAg 0;
// Frame: CemBodyExpoCommonFr18
BA_ "GenMsgSendType" BO_ 397 0;
BA_ "GenMsgCycleTime" BO_ 397 45.000;
BA_ "GenSigSendType" SG_ 397 VehObjforADB6AdbAbsDist 0;
BA_ "GenSigSendType" SG_ 397 VehObjforADB6AdbClassn 0;
BA_ "GenSigSendType" SG_ 397 VehObjforADB6AdbClassnQly 0;
BA_ "GenSigSendType" SG_ 397 VehObjforADB6AdbDetdQly 0;
BA_ "GenSigStartValue" SG_ 397 VehObjforADB6AdbHozlAg 800;
BA_ "GenSigSendType" SG_ 397 VehObjforADB6AdbHozlAg 0;
BA_ "GenSigSendType" SG_ 397 VehObjforADB6AdbObjDir 0;
BA_ "GenSigStartValue" SG_ 397 VehObjforADB6AdbObjHozlAgSpd 2880;
BA_ "GenSigSendType" SG_ 397 VehObjforADB6AdbObjHozlAgSpd 0;
BA_ "GenSigStartValue" SG_ 397 VehObjforADB6AdbObjVertAgSpd 720;
BA_ "GenSigSendType" SG_ 397 VehObjforADB6AdbObjVertAgSpd 0;
BA_ "GenSigSendType" SG_ 397 VehObjforADB6AdbTrkInfo 0;
BA_ "GenSigStartValue" SG_ 397 VehObjforADB6AdbVertAg 75;
BA_ "GenSigSendType" SG_ 397 VehObjforADB6AdbVertAg 0;
// Frame: CemBodyExpoCommonFr19
BA_ "GenMsgSendType" BO_ 398 0;
BA_ "GenMsgCycleTime" BO_ 398 45.000;
BA_ "GenSigSendType" SG_ 398 VehObjforADB7AdbAbsDist 0;
BA_ "GenSigSendType" SG_ 398 VehObjforADB7AdbClassn 0;
BA_ "GenSigSendType" SG_ 398 VehObjforADB7AdbClassnQly 0;
BA_ "GenSigSendType" SG_ 398 VehObjforADB7AdbDetdQly 0;
BA_ "GenSigStartValue" SG_ 398 VehObjforADB7AdbHozlAg 800;
BA_ "GenSigSendType" SG_ 398 VehObjforADB7AdbHozlAg 0;
BA_ "GenSigSendType" SG_ 398 VehObjforADB7AdbObjDir 0;
BA_ "GenSigStartValue" SG_ 398 VehObjforADB7AdbObjHozlAgSpd 2880;
BA_ "GenSigSendType" SG_ 398 VehObjforADB7AdbObjHozlAgSpd 0;
BA_ "GenSigStartValue" SG_ 398 VehObjforADB7AdbObjVertAgSpd 720;
BA_ "GenSigSendType" SG_ 398 VehObjforADB7AdbObjVertAgSpd 0;
BA_ "GenSigSendType" SG_ 398 VehObjforADB7AdbTrkInfo 0;
BA_ "GenSigStartValue" SG_ 398 VehObjforADB7AdbVertAg 75;
BA_ "GenSigSendType" SG_ 398 VehObjforADB7AdbVertAg 0;
// Frame: CemBodyExpoCommonFr20
BA_ "GenMsgSendType" BO_ 399 0;
BA_ "GenMsgCycleTime" BO_ 399 45.000;
BA_ "GenSigSendType" SG_ 399 VehObjforADB8AdbAbsDist 0;
BA_ "GenSigSendType" SG_ 399 VehObjforADB8AdbClassn 0;
BA_ "GenSigSendType" SG_ 399 VehObjforADB8AdbClassnQly 0;
BA_ "GenSigSendType" SG_ 399 VehObjforADB8AdbDetdQly 0;
BA_ "GenSigStartValue" SG_ 399 VehObjforADB8AdbHozlAg 800;
BA_ "GenSigSendType" SG_ 399 VehObjforADB8AdbHozlAg 0;
BA_ "GenSigSendType" SG_ 399 VehObjforADB8AdbObjDir 0;
BA_ "GenSigStartValue" SG_ 399 VehObjforADB8AdbObjHozlAgSpd 2880;
BA_ "GenSigSendType" SG_ 399 VehObjforADB8AdbObjHozlAgSpd 0;
BA_ "GenSigStartValue" SG_ 399 VehObjforADB8AdbObjVertAgSpd 720;
BA_ "GenSigSendType" SG_ 399 VehObjforADB8AdbObjVertAgSpd 0;
BA_ "GenSigSendType" SG_ 399 VehObjforADB8AdbTrkInfo 0;
BA_ "GenSigStartValue" SG_ 399 VehObjforADB8AdbVertAg 75;
BA_ "GenSigSendType" SG_ 399 VehObjforADB8AdbVertAg 0;
// Frame: CemBodyExpoCommonFr21
BA_ "GenMsgSendType" BO_ 64 0;
BA_ "GenMsgCycleTime" BO_ 64 15.000;
BA_ "GenSigSendType" SG_ 64 CameraStsforAHBC 0;
BA_ "GenSigSendType" SG_ 64 RainLi 0;
BA_ "GenSigSendType" SG_ 64 VehModMngtGlbSafe1CarModSts1 0;
BA_ "GenSigSendType" SG_ 64 VehModMngtGlbSafe1CarModSubtypWdCarModSubtyp 0;
BA_ "GenSigSendType" SG_ 64 VehModMngtGlbSafe1Chks 0;
BA_ "GenSigFuncType" SG_ 64 VehModMngtGlbSafe1Chks 15;
BA_ "GenSigDataID" SG_ 64 VehModMngtGlbSafe1Chks "0x74";
BA_ "GenSigSendType" SG_ 64 VehModMngtGlbSafe1Cntr 0;
BA_ "GenSigFuncType" SG_ 64 VehModMngtGlbSafe1Cntr 16;
BA_ "GenSigSendType" SG_ 64 VehModMngtGlbSafe1EgyLvlElecMai 0;
BA_ "GenSigSendType" SG_ 64 VehModMngtGlbSafe1EgyLvlElecSubtyp 0;
BA_ "GenSigSendType" SG_ 64 VehModMngtGlbSafe1FltEgyCnsWdSts 0;
BA_ "GenSigSendType" SG_ 64 VehModMngtGlbSafe1PwrLvlElecMai 0;
BA_ "GenSigSendType" SG_ 64 VehModMngtGlbSafe1PwrLvlElecSubtyp 0;
BA_ "GenSigStartValue" SG_ 64 VehModMngtGlbSafe1UsgModSts 1;
BA_ "GenSigSendType" SG_ 64 VehModMngtGlbSafe1UsgModSts 0;
BA_ "GenSigSendType" SG_ 64 WipgAutFrntMod 0;
// Frame: CemBodyExpoCommonFr22
BA_ "GenMsgSendType" BO_ 400 0;
BA_ "GenMsgCycleTime" BO_ 400 45.000;
BA_ "GenSigStartValue" SG_ 400 SuspPosnVertAgGenQf 1;
BA_ "GenSigSendType" SG_ 400 SuspPosnVertAgGenQf 0;
BA_ "GenSigSendType" SG_ 400 SuspPosnVertAgSuspPosnVertAg 0;
BA_ "GenSigSendType" SG_ 400 SuspPosnVertLvlFrnt 0;
BA_ "GenSigSendType" SG_ 400 SuspPosnVertLvlFrntQf 0;
BA_ "GenSigSendType" SG_ 400 SuspPosnVertLvlRe 0;
BA_ "GenSigSendType" SG_ 400 SuspPosnVertLvlReQf 0;
// Frame: CemBodyExpoDevDiagFr01
BA_ "GenMsgSendType" BO_ 1432 1;
BA_ "GenMsgDelayTime" BO_ 1432 95.000;
BA_ "GenSigSendType" SG_ 1432 CEMdevelpsignalgrouprespFunctiondevpsignalgroup1 1;
BA_ "GenSigSendType" SG_ 1432 CEMdevelpsignalgrouprespFunctiondevpsignalgroup2 1;
BA_ "GenSigSendType" SG_ 1432 CEMdevelpsignalgrouprespFunctiondevpsignalgroup3 1;
BA_ "GenSigSendType" SG_ 1432 CEMdevelpsignalgrouprespFunctiondevpsignalgroup4 1;
BA_ "GenSigSendType" SG_ 1432 CEMdevelpsignalgrouprespFunctiondevpsignalgroup5 1;
BA_ "GenSigSendType" SG_ 1432 CEMdevelpsignalgrouprespFunctiondevpsignalgroup6 1;
BA_ "GenSigSendType" SG_ 1432 CEMdevelpsignalgrouprespFunctiondevpsignalgroup7 1;
BA_ "GenSigSendType" SG_ 1432 CEMdevelpsignalgrouprespFunctiondevpsignalgroup8 1;
// Frame: CemBodyExpoDevFr02
BA_ "GenMsgSendType" BO_ 1431 1;
BA_ "GenMsgDelayTime" BO_ 1431 95.000;
BA_ "GenSigSendType" SG_ 1431 CEMdevelpsignalgroupcheckFunctiondevpsignalgroup1 1;
BA_ "GenSigSendType" SG_ 1431 CEMdevelpsignalgroupcheckFunctiondevpsignalgroup2 1;
BA_ "GenSigSendType" SG_ 1431 CEMdevelpsignalgroupcheckFunctiondevpsignalgroup3 1;
BA_ "GenSigSendType" SG_ 1431 CEMdevelpsignalgroupcheckFunctiondevpsignalgroup4 1;
BA_ "GenSigSendType" SG_ 1431 CEMdevelpsignalgroupcheckFunctiondevpsignalgroup5 1;
BA_ "GenSigSendType" SG_ 1431 CEMdevelpsignalgroupcheckFunctiondevpsignalgroup6 1;
BA_ "GenSigSendType" SG_ 1431 CEMdevelpsignalgroupcheckFunctiondevpsignalgroup7 1;
BA_ "GenSigSendType" SG_ 1431 CEMdevelpsignalgroupcheckFunctiondevpsignalgroup8 1;
// Frame: CemBodyExpoFr01
BA_ "GenMsgSendType" BO_ 28 1;
BA_ "GenMsgDelayTime" BO_ 28 30.000;
BA_ "GenSigSendType" SG_ 28 ExtrLiShowActvnReq 1;
BA_ "GenSigSendType" SG_ 28 ExtrLiShowFileTxReq 1;
// Frame: CemBodyExpoFr02
BA_ "GenMsgSendType" BO_ 288 1;
BA_ "GenMsgDelayTime" BO_ 288 30.000;
BA_ "GenSigSendType" SG_ 288 DwnLoadDynLitPrmForLedStopLampRi2ContTiPrm 1;
BA_ "SigGroup" SG_ 288 DwnLoadDynLitPrmForLedStopLampRi2ContTiPrm "DwnLoadDynLitPrmForLedStopLampRi2";
BA_ "GenSigSendType" SG_ 288 DwnLoadDynLitPrmForLedStopLampRi2LowBriPrm 1;
BA_ "SigGroup" SG_ 288 DwnLoadDynLitPrmForLedStopLampRi2LowBriPrm "DwnLoadDynLitPrmForLedStopLampRi2";
BA_ "GenSigSendType" SG_ 288 DwnLoadDynLitPrmForLedStopLampRi2ModePrm 1;
BA_ "SigGroup" SG_ 288 DwnLoadDynLitPrmForLedStopLampRi2ModePrm "DwnLoadDynLitPrmForLedStopLampRi2";
BA_ "GenSigSendType" SG_ 288 DwnLoadDynLitPrmForLedStopLampRi2OffsTiPrm 1;
BA_ "SigGroup" SG_ 288 DwnLoadDynLitPrmForLedStopLampRi2OffsTiPrm "DwnLoadDynLitPrmForLedStopLampRi2";
BA_ "GenSigSendType" SG_ 288 DwnLoadDynLitPrmForLedStopLampRi2Tistamp 1;
BA_ "SigGroup" SG_ 288 DwnLoadDynLitPrmForLedStopLampRi2Tistamp "DwnLoadDynLitPrmForLedStopLampRi2";
BA_ "GenSigSendType" SG_ 288 DwnLoadDynLitPrmForLedStopLampRi2UpprBriPrm 1;
BA_ "SigGroup" SG_ 288 DwnLoadDynLitPrmForLedStopLampRi2UpprBriPrm "DwnLoadDynLitPrmForLedStopLampRi2";
// Frame: CemBodyExpoFr03
BA_ "GenMsgSendType" BO_ 289 1;
BA_ "GenMsgDelayTime" BO_ 289 30.000;
BA_ "GenSigSendType" SG_ 289 DwnLoadDynLitPrmLedReFogLampRi2ContTiPrm 1;
BA_ "GenSigSendType" SG_ 289 DwnLoadDynLitPrmLedReFogLampRi2LowBriPrm 1;
BA_ "GenSigSendType" SG_ 289 DwnLoadDynLitPrmLedReFogLampRi2ModePrm 1;
BA_ "GenSigSendType" SG_ 289 DwnLoadDynLitPrmLedReFogLampRi2OffsTiPrm 1;
BA_ "GenSigSendType" SG_ 289 DwnLoadDynLitPrmLedReFogLampRi2Tistamp 1;
BA_ "GenSigSendType" SG_ 289 DwnLoadDynLitPrmLedReFogLampRi2UpprBriPrm 1;
// Frame: CemBodyExpoFr04
BA_ "GenMsgSendType" BO_ 290 1;
BA_ "GenMsgDelayTime" BO_ 290 30.000;
BA_ "GenSigSendType" SG_ 290 DwnLoadDynLitPrmLedRePosnLampRi2ContTiPrm 1;
BA_ "SigGroup" SG_ 290 DwnLoadDynLitPrmLedRePosnLampRi2ContTiPrm "DwnLoadDynLitPrmLedRePosnLampRi2";
BA_ "GenSigSendType" SG_ 290 DwnLoadDynLitPrmLedRePosnLampRi2LowBriPrm 1;
BA_ "SigGroup" SG_ 290 DwnLoadDynLitPrmLedRePosnLampRi2LowBriPrm "DwnLoadDynLitPrmLedRePosnLampRi2";
BA_ "GenSigSendType" SG_ 290 DwnLoadDynLitPrmLedRePosnLampRi2ModePrm 1;
BA_ "SigGroup" SG_ 290 DwnLoadDynLitPrmLedRePosnLampRi2ModePrm "DwnLoadDynLitPrmLedRePosnLampRi2";
BA_ "GenSigSendType" SG_ 290 DwnLoadDynLitPrmLedRePosnLampRi2OffsTiPrm 1;
BA_ "SigGroup" SG_ 290 DwnLoadDynLitPrmLedRePosnLampRi2OffsTiPrm "DwnLoadDynLitPrmLedRePosnLampRi2";
BA_ "GenSigSendType" SG_ 290 DwnLoadDynLitPrmLedRePosnLampRi2Tistamp 1;
BA_ "SigGroup" SG_ 290 DwnLoadDynLitPrmLedRePosnLampRi2Tistamp "DwnLoadDynLitPrmLedRePosnLampRi2";
BA_ "GenSigSendType" SG_ 290 DwnLoadDynLitPrmLedRePosnLampRi2UpprBriPrm 1;
BA_ "SigGroup" SG_ 290 DwnLoadDynLitPrmLedRePosnLampRi2UpprBriPrm "DwnLoadDynLitPrmLedRePosnLampRi2";
// Frame: CemBodyExpoFr05
BA_ "GenMsgSendType" BO_ 291 1;
BA_ "GenMsgDelayTime" BO_ 291 30.000;
BA_ "GenSigSendType" SG_ 291 DwnLoadDynLitPrmLedReTurnIndcrRi2ContTiPrm 1;
BA_ "SigGroup" SG_ 291 DwnLoadDynLitPrmLedReTurnIndcrRi2ContTiPrm "DwnLoadDynLitPrmLedReTurnIndcrRi2";
BA_ "GenSigSendType" SG_ 291 DwnLoadDynLitPrmLedReTurnIndcrRi2LowBriPrm 1;
BA_ "SigGroup" SG_ 291 DwnLoadDynLitPrmLedReTurnIndcrRi2LowBriPrm "DwnLoadDynLitPrmLedReTurnIndcrRi2";
BA_ "GenSigSendType" SG_ 291 DwnLoadDynLitPrmLedReTurnIndcrRi2ModePrm 1;
BA_ "SigGroup" SG_ 291 DwnLoadDynLitPrmLedReTurnIndcrRi2ModePrm "DwnLoadDynLitPrmLedReTurnIndcrRi2";
BA_ "GenSigSendType" SG_ 291 DwnLoadDynLitPrmLedReTurnIndcrRi2OffsTiPrm 1;
BA_ "SigGroup" SG_ 291 DwnLoadDynLitPrmLedReTurnIndcrRi2OffsTiPrm "DwnLoadDynLitPrmLedReTurnIndcrRi2";
BA_ "GenSigSendType" SG_ 291 DwnLoadDynLitPrmLedReTurnIndcrRi2Tistamp 1;
BA_ "SigGroup" SG_ 291 DwnLoadDynLitPrmLedReTurnIndcrRi2Tistamp "DwnLoadDynLitPrmLedReTurnIndcrRi2";
BA_ "GenSigSendType" SG_ 291 DwnLoadDynLitPrmLedReTurnIndcrRi2UpprBriPrm 1;
BA_ "SigGroup" SG_ 291 DwnLoadDynLitPrmLedReTurnIndcrRi2UpprBriPrm "DwnLoadDynLitPrmLedReTurnIndcrRi2";
// Frame: CemBodyExpoFr06
BA_ "GenMsgSendType" BO_ 292 1;
BA_ "GenMsgDelayTime" BO_ 292 30.000;
BA_ "GenSigSendType" SG_ 292 DwnLoadDynLitPrmForLedMkrLampLe1ContTiPrm 1;
BA_ "SigGroup" SG_ 292 DwnLoadDynLitPrmForLedMkrLampLe1ContTiPrm "DwnLoadDynLitPrmForLedMkrLampLe1";
BA_ "GenSigSendType" SG_ 292 DwnLoadDynLitPrmForLedMkrLampLe1LowBriPrm 1;
BA_ "SigGroup" SG_ 292 DwnLoadDynLitPrmForLedMkrLampLe1LowBriPrm "DwnLoadDynLitPrmForLedMkrLampLe1";
BA_ "GenSigSendType" SG_ 292 DwnLoadDynLitPrmForLedMkrLampLe1ModePrm 1;
BA_ "SigGroup" SG_ 292 DwnLoadDynLitPrmForLedMkrLampLe1ModePrm "DwnLoadDynLitPrmForLedMkrLampLe1";
BA_ "GenSigSendType" SG_ 292 DwnLoadDynLitPrmForLedMkrLampLe1OffsTiPrm 1;
BA_ "SigGroup" SG_ 292 DwnLoadDynLitPrmForLedMkrLampLe1OffsTiPrm "DwnLoadDynLitPrmForLedMkrLampLe1";
BA_ "GenSigSendType" SG_ 292 DwnLoadDynLitPrmForLedMkrLampLe1Tistamp 1;
BA_ "SigGroup" SG_ 292 DwnLoadDynLitPrmForLedMkrLampLe1Tistamp "DwnLoadDynLitPrmForLedMkrLampLe1";
BA_ "GenSigSendType" SG_ 292 DwnLoadDynLitPrmForLedMkrLampLe1UpprBriPrm 1;
BA_ "SigGroup" SG_ 292 DwnLoadDynLitPrmForLedMkrLampLe1UpprBriPrm "DwnLoadDynLitPrmForLedMkrLampLe1";
// Frame: CemBodyExpoFr07
BA_ "GenMsgSendType" BO_ 293 1;
BA_ "GenMsgDelayTime" BO_ 293 30.000;
BA_ "GenSigSendType" SG_ 293 DwnLoadDynLtgPrmForLedLoBeamRiContTiPrm 1;
BA_ "GenSigSendType" SG_ 293 DwnLoadDynLtgPrmForLedLoBeamRiLowBriPrm 1;
BA_ "GenSigSendType" SG_ 293 DwnLoadDynLtgPrmForLedLoBeamRiModePrm 1;
BA_ "GenSigSendType" SG_ 293 DwnLoadDynLtgPrmForLedLoBeamRiOffsTiPrm 1;
BA_ "GenSigSendType" SG_ 293 DwnLoadDynLtgPrmForLedLoBeamRiTistamp 1;
BA_ "GenSigSendType" SG_ 293 DwnLoadDynLtgPrmForLedLoBeamRiUpprBriPrm 1;
// Frame: CemBodyExpoFr08
BA_ "GenMsgSendType" BO_ 294 1;
BA_ "GenMsgDelayTime" BO_ 294 30.000;
BA_ "GenSigSendType" SG_ 294 DwnLoadDynLitPrmForLedMkrLampLe2ContTiPrm 1;
BA_ "SigGroup" SG_ 294 DwnLoadDynLitPrmForLedMkrLampLe2ContTiPrm "DwnLoadDynLitPrmForLedMkrLampLe2";
BA_ "GenSigSendType" SG_ 294 DwnLoadDynLitPrmForLedMkrLampLe2LowBriPrm 1;
BA_ "SigGroup" SG_ 294 DwnLoadDynLitPrmForLedMkrLampLe2LowBriPrm "DwnLoadDynLitPrmForLedMkrLampLe2";
BA_ "GenSigSendType" SG_ 294 DwnLoadDynLitPrmForLedMkrLampLe2ModePrm 1;
BA_ "SigGroup" SG_ 294 DwnLoadDynLitPrmForLedMkrLampLe2ModePrm "DwnLoadDynLitPrmForLedMkrLampLe2";
BA_ "GenSigSendType" SG_ 294 DwnLoadDynLitPrmForLedMkrLampLe2OffsTiPrm 1;
BA_ "SigGroup" SG_ 294 DwnLoadDynLitPrmForLedMkrLampLe2OffsTiPrm "DwnLoadDynLitPrmForLedMkrLampLe2";
BA_ "GenSigSendType" SG_ 294 DwnLoadDynLitPrmForLedMkrLampLe2Tistamp 1;
BA_ "SigGroup" SG_ 294 DwnLoadDynLitPrmForLedMkrLampLe2Tistamp "DwnLoadDynLitPrmForLedMkrLampLe2";
BA_ "GenSigSendType" SG_ 294 DwnLoadDynLitPrmForLedMkrLampLe2UpprBriPrm 1;
BA_ "SigGroup" SG_ 294 DwnLoadDynLitPrmForLedMkrLampLe2UpprBriPrm "DwnLoadDynLitPrmForLedMkrLampLe2";
// Frame: CemBodyExpoFr09
BA_ "GenMsgSendType" BO_ 295 1;
BA_ "GenMsgDelayTime" BO_ 295 30.000;
BA_ "GenSigSendType" SG_ 295 DwnLoadDynLitPrmForLedMkrLampRi1ContTiPrm 1;
BA_ "SigGroup" SG_ 295 DwnLoadDynLitPrmForLedMkrLampRi1ContTiPrm "DwnLoadDynLitPrmForLedMkrLampRi1";
BA_ "GenSigSendType" SG_ 295 DwnLoadDynLitPrmForLedMkrLampRi1LowBriPrm 1;
BA_ "SigGroup" SG_ 295 DwnLoadDynLitPrmForLedMkrLampRi1LowBriPrm "DwnLoadDynLitPrmForLedMkrLampRi1";
BA_ "GenSigSendType" SG_ 295 DwnLoadDynLitPrmForLedMkrLampRi1ModePrm 1;
BA_ "SigGroup" SG_ 295 DwnLoadDynLitPrmForLedMkrLampRi1ModePrm "DwnLoadDynLitPrmForLedMkrLampRi1";
BA_ "GenSigSendType" SG_ 295 DwnLoadDynLitPrmForLedMkrLampRi1OffsTiPrm 1;
BA_ "SigGroup" SG_ 295 DwnLoadDynLitPrmForLedMkrLampRi1OffsTiPrm "DwnLoadDynLitPrmForLedMkrLampRi1";
BA_ "GenSigSendType" SG_ 295 DwnLoadDynLitPrmForLedMkrLampRi1Tistamp 1;
BA_ "SigGroup" SG_ 295 DwnLoadDynLitPrmForLedMkrLampRi1Tistamp "DwnLoadDynLitPrmForLedMkrLampRi1";
BA_ "GenSigSendType" SG_ 295 DwnLoadDynLitPrmForLedMkrLampRi1UpprBriPrm 1;
BA_ "SigGroup" SG_ 295 DwnLoadDynLitPrmForLedMkrLampRi1UpprBriPrm "DwnLoadDynLitPrmForLedMkrLampRi1";
// Frame: CemBodyExpoFr10
BA_ "GenMsgSendType" BO_ 296 1;
BA_ "GenMsgDelayTime" BO_ 296 30.000;
BA_ "GenSigSendType" SG_ 296 DwnLoadDynLitPrmForLedStopLampLe1ContTiPrm 1;
BA_ "SigGroup" SG_ 296 DwnLoadDynLitPrmForLedStopLampLe1ContTiPrm "DwnLoadDynLitPrmForLedStopLampLe1";
BA_ "GenSigSendType" SG_ 296 DwnLoadDynLitPrmForLedStopLampLe1LowBriPrm 1;
BA_ "SigGroup" SG_ 296 DwnLoadDynLitPrmForLedStopLampLe1LowBriPrm "DwnLoadDynLitPrmForLedStopLampLe1";
BA_ "GenSigSendType" SG_ 296 DwnLoadDynLitPrmForLedStopLampLe1ModePrm 1;
BA_ "SigGroup" SG_ 296 DwnLoadDynLitPrmForLedStopLampLe1ModePrm "DwnLoadDynLitPrmForLedStopLampLe1";
BA_ "GenSigSendType" SG_ 296 DwnLoadDynLitPrmForLedStopLampLe1OffsTiPrm 1;
BA_ "SigGroup" SG_ 296 DwnLoadDynLitPrmForLedStopLampLe1OffsTiPrm "DwnLoadDynLitPrmForLedStopLampLe1";
BA_ "GenSigSendType" SG_ 296 DwnLoadDynLitPrmForLedStopLampLe1Tistamp 1;
BA_ "SigGroup" SG_ 296 DwnLoadDynLitPrmForLedStopLampLe1Tistamp "DwnLoadDynLitPrmForLedStopLampLe1";
BA_ "GenSigSendType" SG_ 296 DwnLoadDynLitPrmForLedStopLampLe1UpprBriPrm 1;
BA_ "SigGroup" SG_ 296 DwnLoadDynLitPrmForLedStopLampLe1UpprBriPrm "DwnLoadDynLitPrmForLedStopLampLe1";
// Frame: CemBodyExpoFr11
BA_ "GenMsgSendType" BO_ 297 1;
BA_ "GenMsgDelayTime" BO_ 297 30.000;
BA_ "GenSigSendType" SG_ 297 DwnLoadDynLitPrmForLedStopLampLe2ContTiPrm 1;
BA_ "SigGroup" SG_ 297 DwnLoadDynLitPrmForLedStopLampLe2ContTiPrm "DwnLoadDynLitPrmForLedStopLampLe2";
BA_ "GenSigSendType" SG_ 297 DwnLoadDynLitPrmForLedStopLampLe2LowBriPrm 1;
BA_ "SigGroup" SG_ 297 DwnLoadDynLitPrmForLedStopLampLe2LowBriPrm "DwnLoadDynLitPrmForLedStopLampLe2";
BA_ "GenSigSendType" SG_ 297 DwnLoadDynLitPrmForLedStopLampLe2ModePrm 1;
BA_ "SigGroup" SG_ 297 DwnLoadDynLitPrmForLedStopLampLe2ModePrm "DwnLoadDynLitPrmForLedStopLampLe2";
BA_ "GenSigSendType" SG_ 297 DwnLoadDynLitPrmForLedStopLampLe2OffsTiPrm 1;
BA_ "SigGroup" SG_ 297 DwnLoadDynLitPrmForLedStopLampLe2OffsTiPrm "DwnLoadDynLitPrmForLedStopLampLe2";
BA_ "GenSigSendType" SG_ 297 DwnLoadDynLitPrmForLedStopLampLe2Tistamp 1;
BA_ "SigGroup" SG_ 297 DwnLoadDynLitPrmForLedStopLampLe2Tistamp "DwnLoadDynLitPrmForLedStopLampLe2";
BA_ "GenSigSendType" SG_ 297 DwnLoadDynLitPrmForLedStopLampLe2UpprBriPrm 1;
BA_ "SigGroup" SG_ 297 DwnLoadDynLitPrmForLedStopLampLe2UpprBriPrm "DwnLoadDynLitPrmForLedStopLampLe2";
// Frame: CemBodyExpoFr12
BA_ "GenMsgSendType" BO_ 298 1;
BA_ "GenMsgDelayTime" BO_ 298 30.000;
BA_ "GenSigSendType" SG_ 298 DwnLoadDynLitPrmForLedStopLampRi1ContTiPrm 1;
BA_ "SigGroup" SG_ 298 DwnLoadDynLitPrmForLedStopLampRi1ContTiPrm "DwnLoadDynLitPrmForLedStopLampRi1";
BA_ "GenSigSendType" SG_ 298 DwnLoadDynLitPrmForLedStopLampRi1LowBriPrm 1;
BA_ "SigGroup" SG_ 298 DwnLoadDynLitPrmForLedStopLampRi1LowBriPrm "DwnLoadDynLitPrmForLedStopLampRi1";
BA_ "GenSigSendType" SG_ 298 DwnLoadDynLitPrmForLedStopLampRi1ModePrm 1;
BA_ "SigGroup" SG_ 298 DwnLoadDynLitPrmForLedStopLampRi1ModePrm "DwnLoadDynLitPrmForLedStopLampRi1";
BA_ "GenSigSendType" SG_ 298 DwnLoadDynLitPrmForLedStopLampRi1OffsTiPrm 1;
BA_ "SigGroup" SG_ 298 DwnLoadDynLitPrmForLedStopLampRi1OffsTiPrm "DwnLoadDynLitPrmForLedStopLampRi1";
BA_ "GenSigSendType" SG_ 298 DwnLoadDynLitPrmForLedStopLampRi1Tistamp 1;
BA_ "SigGroup" SG_ 298 DwnLoadDynLitPrmForLedStopLampRi1Tistamp "DwnLoadDynLitPrmForLedStopLampRi1";
BA_ "GenSigSendType" SG_ 298 DwnLoadDynLitPrmForLedStopLampRi1UpprBriPrm 1;
BA_ "SigGroup" SG_ 298 DwnLoadDynLitPrmForLedStopLampRi1UpprBriPrm "DwnLoadDynLitPrmForLedStopLampRi1";
// Frame: CemBodyExpoFr13
BA_ "GenMsgSendType" BO_ 299 1;
BA_ "GenMsgDelayTime" BO_ 299 30.000;
BA_ "GenSigSendType" SG_ 299 DwnLoadDynLitPrmLedReFogLampLe1ContTiPrm 1;
BA_ "GenSigSendType" SG_ 299 DwnLoadDynLitPrmLedReFogLampLe1LowBriPrm 1;
BA_ "GenSigSendType" SG_ 299 DwnLoadDynLitPrmLedReFogLampLe1ModePrm 1;
BA_ "GenSigSendType" SG_ 299 DwnLoadDynLitPrmLedReFogLampLe1OffsTiPrm 1;
BA_ "GenSigSendType" SG_ 299 DwnLoadDynLitPrmLedReFogLampLe1Tistamp 1;
BA_ "GenSigSendType" SG_ 299 DwnLoadDynLitPrmLedReFogLampLe1UpprBriPrm 1;
// Frame: CemBodyExpoFr14
BA_ "GenMsgSendType" BO_ 300 1;
BA_ "GenMsgDelayTime" BO_ 300 30.000;
BA_ "GenSigSendType" SG_ 300 DwnLoadDynLitPrmLedReFogLampLe2ContTiPrm 1;
BA_ "GenSigSendType" SG_ 300 DwnLoadDynLitPrmLedReFogLampLe2LowBriPrm 1;
BA_ "GenSigSendType" SG_ 300 DwnLoadDynLitPrmLedReFogLampLe2ModePrm 1;
BA_ "GenSigSendType" SG_ 300 DwnLoadDynLitPrmLedReFogLampLe2OffsTiPrm 1;
BA_ "GenSigSendType" SG_ 300 DwnLoadDynLitPrmLedReFogLampLe2Tistamp 1;
BA_ "GenSigSendType" SG_ 300 DwnLoadDynLitPrmLedReFogLampLe2UpprBriPrm 1;
// Frame: CemBodyExpoFr15
BA_ "GenMsgSendType" BO_ 301 1;
BA_ "GenMsgDelayTime" BO_ 301 30.000;
BA_ "GenSigSendType" SG_ 301 DwnLoadDynLitPrmLedReFogLampRi1ContTiPrm 1;
BA_ "GenSigSendType" SG_ 301 DwnLoadDynLitPrmLedReFogLampRi1LowBriPrm 1;
BA_ "GenSigSendType" SG_ 301 DwnLoadDynLitPrmLedReFogLampRi1ModePrm 1;
BA_ "GenSigSendType" SG_ 301 DwnLoadDynLitPrmLedReFogLampRi1OffsTiPrm 1;
BA_ "GenSigSendType" SG_ 301 DwnLoadDynLitPrmLedReFogLampRi1Tistamp 1;
BA_ "GenSigSendType" SG_ 301 DwnLoadDynLitPrmLedReFogLampRi1UpprBriPrm 1;
// Frame: CemBodyExpoFr16
BA_ "GenMsgSendType" BO_ 302 1;
BA_ "GenMsgDelayTime" BO_ 302 30.000;
BA_ "GenSigSendType" SG_ 302 DwnLoadDynLitPrmLedRePosnLampLe1ContTiPrm 1;
BA_ "SigGroup" SG_ 302 DwnLoadDynLitPrmLedRePosnLampLe1ContTiPrm "DwnLoadDynLitPrmLedRePosnLampLe1";
BA_ "GenSigSendType" SG_ 302 DwnLoadDynLitPrmLedRePosnLampLe1LowBriPrm 1;
BA_ "SigGroup" SG_ 302 DwnLoadDynLitPrmLedRePosnLampLe1LowBriPrm "DwnLoadDynLitPrmLedRePosnLampLe1";
BA_ "GenSigSendType" SG_ 302 DwnLoadDynLitPrmLedRePosnLampLe1ModePrm 1;
BA_ "SigGroup" SG_ 302 DwnLoadDynLitPrmLedRePosnLampLe1ModePrm "DwnLoadDynLitPrmLedRePosnLampLe1";
BA_ "GenSigSendType" SG_ 302 DwnLoadDynLitPrmLedRePosnLampLe1OffsTiPrm 1;
BA_ "SigGroup" SG_ 302 DwnLoadDynLitPrmLedRePosnLampLe1OffsTiPrm "DwnLoadDynLitPrmLedRePosnLampLe1";
BA_ "GenSigSendType" SG_ 302 DwnLoadDynLitPrmLedRePosnLampLe1Tistamp 1;
BA_ "SigGroup" SG_ 302 DwnLoadDynLitPrmLedRePosnLampLe1Tistamp "DwnLoadDynLitPrmLedRePosnLampLe1";
BA_ "GenSigSendType" SG_ 302 DwnLoadDynLitPrmLedRePosnLampLe1UpprBriPrm 1;
BA_ "SigGroup" SG_ 302 DwnLoadDynLitPrmLedRePosnLampLe1UpprBriPrm "DwnLoadDynLitPrmLedRePosnLampLe1";
// Frame: CemBodyExpoFr17
BA_ "GenMsgSendType" BO_ 303 1;
BA_ "GenMsgDelayTime" BO_ 303 30.000;
BA_ "GenSigSendType" SG_ 303 DwnLoadDynLitPrmLedRePosnLampLe2ContTiPrm 1;
BA_ "SigGroup" SG_ 303 DwnLoadDynLitPrmLedRePosnLampLe2ContTiPrm "DwnLoadDynLitPrmLedRePosnLampLe2";
BA_ "GenSigSendType" SG_ 303 DwnLoadDynLitPrmLedRePosnLampLe2LowBriPrm 1;
BA_ "SigGroup" SG_ 303 DwnLoadDynLitPrmLedRePosnLampLe2LowBriPrm "DwnLoadDynLitPrmLedRePosnLampLe2";
BA_ "GenSigSendType" SG_ 303 DwnLoadDynLitPrmLedRePosnLampLe2ModePrm 1;
BA_ "SigGroup" SG_ 303 DwnLoadDynLitPrmLedRePosnLampLe2ModePrm "DwnLoadDynLitPrmLedRePosnLampLe2";
BA_ "GenSigSendType" SG_ 303 DwnLoadDynLitPrmLedRePosnLampLe2OffsTiPrm 1;
BA_ "SigGroup" SG_ 303 DwnLoadDynLitPrmLedRePosnLampLe2OffsTiPrm "DwnLoadDynLitPrmLedRePosnLampLe2";
BA_ "GenSigSendType" SG_ 303 DwnLoadDynLitPrmLedRePosnLampLe2Tistamp 1;
BA_ "SigGroup" SG_ 303 DwnLoadDynLitPrmLedRePosnLampLe2Tistamp "DwnLoadDynLitPrmLedRePosnLampLe2";
BA_ "GenSigSendType" SG_ 303 DwnLoadDynLitPrmLedRePosnLampLe2UpprBriPrm 1;
BA_ "SigGroup" SG_ 303 DwnLoadDynLitPrmLedRePosnLampLe2UpprBriPrm "DwnLoadDynLitPrmLedRePosnLampLe2";
// Frame: CemBodyExpoFr18
BA_ "GenMsgSendType" BO_ 304 1;
BA_ "GenMsgDelayTime" BO_ 304 30.000;
BA_ "GenSigSendType" SG_ 304 DwnLoadDynLitPrmLedRePosnLampRi1ContTiPrm 1;
BA_ "SigGroup" SG_ 304 DwnLoadDynLitPrmLedRePosnLampRi1ContTiPrm "DwnLoadDynLitPrmLedRePosnLampRi1";
BA_ "GenSigSendType" SG_ 304 DwnLoadDynLitPrmLedRePosnLampRi1LowBriPrm 1;
BA_ "SigGroup" SG_ 304 DwnLoadDynLitPrmLedRePosnLampRi1LowBriPrm "DwnLoadDynLitPrmLedRePosnLampRi1";
BA_ "GenSigSendType" SG_ 304 DwnLoadDynLitPrmLedRePosnLampRi1ModePrm 1;
BA_ "SigGroup" SG_ 304 DwnLoadDynLitPrmLedRePosnLampRi1ModePrm "DwnLoadDynLitPrmLedRePosnLampRi1";
BA_ "GenSigSendType" SG_ 304 DwnLoadDynLitPrmLedRePosnLampRi1OffsTiPrm 1;
BA_ "SigGroup" SG_ 304 DwnLoadDynLitPrmLedRePosnLampRi1OffsTiPrm "DwnLoadDynLitPrmLedRePosnLampRi1";
BA_ "GenSigSendType" SG_ 304 DwnLoadDynLitPrmLedRePosnLampRi1Tistamp 1;
BA_ "SigGroup" SG_ 304 DwnLoadDynLitPrmLedRePosnLampRi1Tistamp "DwnLoadDynLitPrmLedRePosnLampRi1";
BA_ "GenSigSendType" SG_ 304 DwnLoadDynLitPrmLedRePosnLampRi1UpprBriPrm 1;
BA_ "SigGroup" SG_ 304 DwnLoadDynLitPrmLedRePosnLampRi1UpprBriPrm "DwnLoadDynLitPrmLedRePosnLampRi1";
// Frame: CemBodyExpoFr19
BA_ "GenMsgSendType" BO_ 305 1;
BA_ "GenMsgDelayTime" BO_ 305 30.000;
BA_ "GenSigSendType" SG_ 305 DwnLoadDynLitPrmLedReTurnIndcrLe1ContTiPrm 1;
BA_ "SigGroup" SG_ 305 DwnLoadDynLitPrmLedReTurnIndcrLe1ContTiPrm "DwnLoadDynLitPrmLedReTurnIndcrLe1";
BA_ "GenSigSendType" SG_ 305 DwnLoadDynLitPrmLedReTurnIndcrLe1LowBriPrm 1;
BA_ "SigGroup" SG_ 305 DwnLoadDynLitPrmLedReTurnIndcrLe1LowBriPrm "DwnLoadDynLitPrmLedReTurnIndcrLe1";
BA_ "GenSigSendType" SG_ 305 DwnLoadDynLitPrmLedReTurnIndcrLe1ModePrm 1;
BA_ "SigGroup" SG_ 305 DwnLoadDynLitPrmLedReTurnIndcrLe1ModePrm "DwnLoadDynLitPrmLedReTurnIndcrLe1";
BA_ "GenSigSendType" SG_ 305 DwnLoadDynLitPrmLedReTurnIndcrLe1OffsTiPrm 1;
BA_ "SigGroup" SG_ 305 DwnLoadDynLitPrmLedReTurnIndcrLe1OffsTiPrm "DwnLoadDynLitPrmLedReTurnIndcrLe1";
BA_ "GenSigSendType" SG_ 305 DwnLoadDynLitPrmLedReTurnIndcrLe1Tistamp 1;
BA_ "SigGroup" SG_ 305 DwnLoadDynLitPrmLedReTurnIndcrLe1Tistamp "DwnLoadDynLitPrmLedReTurnIndcrLe1";
BA_ "GenSigSendType" SG_ 305 DwnLoadDynLitPrmLedReTurnIndcrLe1UpprBriPrm 1;
BA_ "SigGroup" SG_ 305 DwnLoadDynLitPrmLedReTurnIndcrLe1UpprBriPrm "DwnLoadDynLitPrmLedReTurnIndcrLe1";
// Frame: CemBodyExpoFr20
BA_ "GenMsgSendType" BO_ 306 1;
BA_ "GenMsgDelayTime" BO_ 306 30.000;
BA_ "GenSigSendType" SG_ 306 DwnLoadDynLitPrmLedReTurnIndcrLe2ContTiPrm 1;
BA_ "SigGroup" SG_ 306 DwnLoadDynLitPrmLedReTurnIndcrLe2ContTiPrm "DwnLoadDynLitPrmLedReTurnIndcrLe2";
BA_ "GenSigSendType" SG_ 306 DwnLoadDynLitPrmLedReTurnIndcrLe2LowBriPrm 1;
BA_ "SigGroup" SG_ 306 DwnLoadDynLitPrmLedReTurnIndcrLe2LowBriPrm "DwnLoadDynLitPrmLedReTurnIndcrLe2";
BA_ "GenSigSendType" SG_ 306 DwnLoadDynLitPrmLedReTurnIndcrLe2ModePrm 1;
BA_ "SigGroup" SG_ 306 DwnLoadDynLitPrmLedReTurnIndcrLe2ModePrm "DwnLoadDynLitPrmLedReTurnIndcrLe2";
BA_ "GenSigSendType" SG_ 306 DwnLoadDynLitPrmLedReTurnIndcrLe2OffsTiPrm 1;
BA_ "SigGroup" SG_ 306 DwnLoadDynLitPrmLedReTurnIndcrLe2OffsTiPrm "DwnLoadDynLitPrmLedReTurnIndcrLe2";
BA_ "GenSigSendType" SG_ 306 DwnLoadDynLitPrmLedReTurnIndcrLe2Tistamp 1;
BA_ "SigGroup" SG_ 306 DwnLoadDynLitPrmLedReTurnIndcrLe2Tistamp "DwnLoadDynLitPrmLedReTurnIndcrLe2";
BA_ "GenSigSendType" SG_ 306 DwnLoadDynLitPrmLedReTurnIndcrLe2UpprBriPrm 1;
BA_ "SigGroup" SG_ 306 DwnLoadDynLitPrmLedReTurnIndcrLe2UpprBriPrm "DwnLoadDynLitPrmLedReTurnIndcrLe2";
// Frame: CemBodyExpoFr21
BA_ "GenMsgSendType" BO_ 307 1;
BA_ "GenMsgDelayTime" BO_ 307 30.000;
BA_ "GenSigSendType" SG_ 307 DwnLoadDynLitPrmLedReTurnIndcrRi1ContTiPrm 1;
BA_ "SigGroup" SG_ 307 DwnLoadDynLitPrmLedReTurnIndcrRi1ContTiPrm "DwnLoadDynLitPrmLedReTurnIndcrRi1";
BA_ "GenSigSendType" SG_ 307 DwnLoadDynLitPrmLedReTurnIndcrRi1LowBriPrm 1;
BA_ "SigGroup" SG_ 307 DwnLoadDynLitPrmLedReTurnIndcrRi1LowBriPrm "DwnLoadDynLitPrmLedReTurnIndcrRi1";
BA_ "GenSigSendType" SG_ 307 DwnLoadDynLitPrmLedReTurnIndcrRi1ModePrm 1;
BA_ "SigGroup" SG_ 307 DwnLoadDynLitPrmLedReTurnIndcrRi1ModePrm "DwnLoadDynLitPrmLedReTurnIndcrRi1";
BA_ "GenSigSendType" SG_ 307 DwnLoadDynLitPrmLedReTurnIndcrRi1OffsTiPrm 1;
BA_ "SigGroup" SG_ 307 DwnLoadDynLitPrmLedReTurnIndcrRi1OffsTiPrm "DwnLoadDynLitPrmLedReTurnIndcrRi1";
BA_ "GenSigSendType" SG_ 307 DwnLoadDynLitPrmLedReTurnIndcrRi1Tistamp 1;
BA_ "SigGroup" SG_ 307 DwnLoadDynLitPrmLedReTurnIndcrRi1Tistamp "DwnLoadDynLitPrmLedReTurnIndcrRi1";
BA_ "GenSigSendType" SG_ 307 DwnLoadDynLitPrmLedReTurnIndcrRi1UpprBriPrm 1;
BA_ "SigGroup" SG_ 307 DwnLoadDynLitPrmLedReTurnIndcrRi1UpprBriPrm "DwnLoadDynLitPrmLedReTurnIndcrRi1";
// Frame: CemBodyExpoFr22
BA_ "GenMsgSendType" BO_ 308 1;
BA_ "GenMsgDelayTime" BO_ 308 30.000;
BA_ "GenSigSendType" SG_ 308 DwnLoadDynLitPrmLedRvsgLampLe1ContTiPrm 1;
BA_ "GenSigSendType" SG_ 308 DwnLoadDynLitPrmLedRvsgLampLe1LowBriPrm 1;
BA_ "GenSigSendType" SG_ 308 DwnLoadDynLitPrmLedRvsgLampLe1ModePrm 1;
BA_ "GenSigSendType" SG_ 308 DwnLoadDynLitPrmLedRvsgLampLe1OffsTiPrm 1;
BA_ "GenSigSendType" SG_ 308 DwnLoadDynLitPrmLedRvsgLampLe1Tistamp 1;
BA_ "GenSigSendType" SG_ 308 DwnLoadDynLitPrmLedRvsgLampLe1UpprBriPrm 1;
// Frame: CemBodyExpoFr23
BA_ "GenMsgSendType" BO_ 309 1;
BA_ "GenMsgDelayTime" BO_ 309 30.000;
BA_ "GenSigSendType" SG_ 309 DwnLoadDynLitPrmLedRvsgLampLe2ContTiPrm 1;
BA_ "GenSigSendType" SG_ 309 DwnLoadDynLitPrmLedRvsgLampLe2LowBriPrm 1;
BA_ "GenSigSendType" SG_ 309 DwnLoadDynLitPrmLedRvsgLampLe2ModePrm 1;
BA_ "GenSigSendType" SG_ 309 DwnLoadDynLitPrmLedRvsgLampLe2OffsTiPrm 1;
BA_ "GenSigSendType" SG_ 309 DwnLoadDynLitPrmLedRvsgLampLe2Tistamp 1;
BA_ "GenSigSendType" SG_ 309 DwnLoadDynLitPrmLedRvsgLampLe2UpprBriPrm 1;
// Frame: CemBodyExpoFr24
BA_ "GenMsgSendType" BO_ 310 1;
BA_ "GenMsgDelayTime" BO_ 310 30.000;
BA_ "GenSigSendType" SG_ 310 DwnLoadDynLitPrmLedRvsgLampRi1ContTiPrm 1;
BA_ "GenSigSendType" SG_ 310 DwnLoadDynLitPrmLedRvsgLampRi1LowBriPrm 1;
BA_ "GenSigSendType" SG_ 310 DwnLoadDynLitPrmLedRvsgLampRi1ModePrm 1;
BA_ "GenSigSendType" SG_ 310 DwnLoadDynLitPrmLedRvsgLampRi1OffsTiPrm 1;
BA_ "GenSigSendType" SG_ 310 DwnLoadDynLitPrmLedRvsgLampRi1Tistamp 1;
BA_ "GenSigSendType" SG_ 310 DwnLoadDynLitPrmLedRvsgLampRi1UpprBriPrm 1;
// Frame: CemBodyExpoFr25
BA_ "GenMsgSendType" BO_ 120 0;
BA_ "GenMsgCycleTime" BO_ 120 25.000;
BA_ "GenSigSendType" SG_ 120 ActvnOfReLogoLamp 0;
BA_ "GenSigSendType" SG_ 120 LvlgSwtSetReqADModCtrlInhbn 0;
BA_ "GenSigSendType" SG_ 120 LvlgSwtSetReqChks 0;
BA_ "GenSigSendType" SG_ 120 LvlgSwtSetReqCntr 0;
BA_ "GenSigSendType" SG_ 120 OutdBriChks 0;
BA_ "GenSigFuncType" SG_ 120 OutdBriChks 15;
BA_ "GenSigDataID" SG_ 120 OutdBriChks "0x1F42";
BA_ "GenSigSendType" SG_ 120 OutdBriCntr 0;
BA_ "GenSigFuncType" SG_ 120 OutdBriCntr 16;
BA_ "GenSigSendType" SG_ 120 OutdBriSts 0;
// Frame: CemBodyExpoFr26
BA_ "GenMsgSendType" BO_ 311 1;
BA_ "GenMsgDelayTime" BO_ 311 30.000;
BA_ "GenSigSendType" SG_ 311 DwnLoadDynLitPrmForLedHiBeamLeContTiPrm 1;
BA_ "GenSigSendType" SG_ 311 DwnLoadDynLitPrmForLedHiBeamLeLowBriPrm 1;
BA_ "GenSigSendType" SG_ 311 DwnLoadDynLitPrmForLedHiBeamLeModePrm 1;
BA_ "GenSigSendType" SG_ 311 DwnLoadDynLitPrmForLedHiBeamLeOffsTiPrm 1;
BA_ "GenSigSendType" SG_ 311 DwnLoadDynLitPrmForLedHiBeamLeTistamp 1;
BA_ "GenSigSendType" SG_ 311 DwnLoadDynLitPrmForLedHiBeamLeUpprBriPrm 1;

VAL_ 82 AutWinWipgCmd 0 "WipgSpd2_WipgSpd0Rpm" 1 "WipgSpd2_WipgSpd40Rpm" 2 "WipgSpd2_WipgSpd43Rpm" 3 "WipgSpd2_WipgSpd46Rpm" 4 "WipgSpd2_WipgSpd50Rpm" 5 "WipgSpd2_WipgSpd54Rpm" 6 "WipgSpd2_WipgSpd57Rpm" 7 "WipgSpd2_WipgSpd60Rpm";
VAL_ 82 LiOprnMod 0 "LiOperMod_Night" 1 "LiOperMod_Day" 2 "LiOperMod_Twli" 3 "LiOperMod_Tnl";
VAL_ 82 SteerWhlSnsrQf 0 "GenQf1_UndefindDataAccur" 1 "GenQf1_TmpUndefdData" 2 "GenQf1_DataAccurNotWithinSpcn" 3 "GenQf1_AccurData";
VAL_ 768 ActvnOfRvsg 0 "OnOff1_Off" 1 "OnOff1_On";
VAL_ 80 VehSpdLgtQf 0 "GenQf1_UndefindDataAccur" 1 "GenQf1_TmpUndefdData" 2 "GenQf1_DataAccurNotWithinSpcn" 3 "GenQf1_AccurData";
VAL_ 512 ExtrLiRlyPwrDwn 0 "Boolean_FALSE" 1 "Boolean_TRUE";
VAL_ 512 VehBattUSysUQf 0 "GenQf1_UndefindDataAccur" 1 "GenQf1_TmpUndefdData" 2 "GenQf1_DataAccurNotWithinSpcn" 3 "GenQf1_AccurData";
VAL_ 544 ActnOfLedGrilleLamp 0 "OnOff1_Off" 1 "OnOff1_On";
VAL_ 544 TrSts 0 "DoorSts2_Ukwn" 1 "DoorSts2_Opend" 2 "DoorSts2_Clsd";
VAL_ 128 AmbTRawQly 0 "GenQf1_UndefindDataAccur" 1 "GenQf1_TmpUndefdData" 2 "GenQf1_DataAccurNotWithinSpcn" 3 "GenQf1_AccurData";
VAL_ 128 BrkPedlSnsrQf 0 "GenQf1_UndefindDataAccur" 1 "GenQf1_TmpUndefdData" 2 "GenQf1_DataAccurNotWithinSpcn" 3 "GenQf1_AccurData";
VAL_ 128 BrkPedlSnsrSt 0 "PsdNotPsd2_NoInfo1" 1 "PsdNotPsd2_NotPsd" 2 "PsdNotPsd2_Psd" 3 "PsdNotPsd2_NoInfo2";
VAL_ 128 TooManyCars 0 "NoYes1_No" 1 "NoYes1_Yes";
VAL_ 389 TrafficSignForADB1AdbDetdQly 0 "ClassnQly_Low" 1 "ClassnQly_Medium" 2 "ClassnQly_High";
VAL_ 389 TrafficSignForADB1AdbTrkInfo 0 "NotTracked" 1 "Tracking";
VAL_ 390 TrafficSignForADB2AdbDetdQly 0 "ClassnQly_Low" 1 "ClassnQly_Medium" 2 "ClassnQly_High";
VAL_ 390 TrafficSignForADB2AdbTrkInfo 0 "NotTracked" 1 "Tracking";
VAL_ 391 VehObjforAHBAdbClassn 0 "AdbClassn_NoVehicle" 1 "AdbClassn_Car" 2 "AdbClassn_Truck" 3 "AdbClassn_Bus" 4 "AdbClassn_BikeOrMotorBike" 5 "AdbClassn_Pedestrain" 6 "AdbClassn_Mixed" 7 "AdbClassn_Unknown";
VAL_ 391 VehObjforAHBAdbClassnQly 0 "ClassnQly_Low" 1 "ClassnQly_Medium" 2 "ClassnQly_High";
VAL_ 391 VehObjforAHBAdbDetdQly 0 "ClassnQly_Low" 1 "ClassnQly_Medium" 2 "ClassnQly_High";
VAL_ 391 VehObjforAHBAdbObjDir 0 "AdbObjDir_Idle" 1 "AdbObjDir_Oncoming" 2 "AdbObjDir_Preceding" 3 "AdbObjDir_Others";
VAL_ 391 VehObjforAHBAdbTrkInfo 0 "NotTracked" 1 "Tracking";
VAL_ 392 VehObjforADB1AdbClassn 0 "AdbClassn_NoVehicle" 1 "AdbClassn_Car" 2 "AdbClassn_Truck" 3 "AdbClassn_Bus" 4 "AdbClassn_BikeOrMotorBike" 5 "AdbClassn_Pedestrain" 6 "AdbClassn_Mixed" 7 "AdbClassn_Unknown";
VAL_ 392 VehObjforADB1AdbClassnQly 0 "ClassnQly_Low" 1 "ClassnQly_Medium" 2 "ClassnQly_High";
VAL_ 392 VehObjforADB1AdbDetdQly 0 "ClassnQly_Low" 1 "ClassnQly_Medium" 2 "ClassnQly_High";
VAL_ 392 VehObjforADB1AdbObjDir 0 "AdbObjDir_Idle" 1 "AdbObjDir_Oncoming" 2 "AdbObjDir_Preceding" 3 "AdbObjDir_Others";
VAL_ 392 VehObjforADB1AdbTrkInfo 0 "NotTracked" 1 "Tracking";
VAL_ 393 VehObjforADB2AdbClassn 0 "AdbClassn_NoVehicle" 1 "AdbClassn_Car" 2 "AdbClassn_Truck" 3 "AdbClassn_Bus" 4 "AdbClassn_BikeOrMotorBike" 5 "AdbClassn_Pedestrain" 6 "AdbClassn_Mixed" 7 "AdbClassn_Unknown";
VAL_ 393 VehObjforADB2AdbClassnQly 0 "ClassnQly_Low" 1 "ClassnQly_Medium" 2 "ClassnQly_High";
VAL_ 393 VehObjforADB2AdbDetdQly 0 "ClassnQly_Low" 1 "ClassnQly_Medium" 2 "ClassnQly_High";
VAL_ 393 VehObjforADB2AdbObjDir 0 "AdbObjDir_Idle" 1 "AdbObjDir_Oncoming" 2 "AdbObjDir_Preceding" 3 "AdbObjDir_Others";
VAL_ 393 VehObjforADB2AdbTrkInfo 0 "NotTracked" 1 "Tracking";
VAL_ 394 VehObjforADB3AdbClassn 0 "AdbClassn_NoVehicle" 1 "AdbClassn_Car" 2 "AdbClassn_Truck" 3 "AdbClassn_Bus" 4 "AdbClassn_BikeOrMotorBike" 5 "AdbClassn_Pedestrain" 6 "AdbClassn_Mixed" 7 "AdbClassn_Unknown";
VAL_ 394 VehObjforADB3AdbClassnQly 0 "ClassnQly_Low" 1 "ClassnQly_Medium" 2 "ClassnQly_High";
VAL_ 394 VehObjforADB3AdbDetdQly 0 "ClassnQly_Low" 1 "ClassnQly_Medium" 2 "ClassnQly_High";
VAL_ 394 VehObjforADB3AdbObjDir 0 "AdbObjDir_Idle" 1 "AdbObjDir_Oncoming" 2 "AdbObjDir_Preceding" 3 "AdbObjDir_Others";
VAL_ 394 VehObjforADB3AdbTrkInfo 0 "NotTracked" 1 "Tracking";
VAL_ 395 VehObjforADB4AdbClassn 0 "AdbClassn_NoVehicle" 1 "AdbClassn_Car" 2 "AdbClassn_Truck" 3 "AdbClassn_Bus" 4 "AdbClassn_BikeOrMotorBike" 5 "AdbClassn_Pedestrain" 6 "AdbClassn_Mixed" 7 "AdbClassn_Unknown";
VAL_ 395 VehObjforADB4AdbClassnQly 0 "ClassnQly_Low" 1 "ClassnQly_Medium" 2 "ClassnQly_High";
VAL_ 395 VehObjforADB4AdbDetdQly 0 "ClassnQly_Low" 1 "ClassnQly_Medium" 2 "ClassnQly_High";
VAL_ 395 VehObjforADB4AdbObjDir 0 "AdbObjDir_Idle" 1 "AdbObjDir_Oncoming" 2 "AdbObjDir_Preceding" 3 "AdbObjDir_Others";
VAL_ 395 VehObjforADB4AdbTrkInfo 0 "NotTracked" 1 "Tracking";
VAL_ 396 VehObjforADB5AdbClassn 0 "AdbClassn_NoVehicle" 1 "AdbClassn_Car" 2 "AdbClassn_Truck" 3 "AdbClassn_Bus" 4 "AdbClassn_BikeOrMotorBike" 5 "AdbClassn_Pedestrain" 6 "AdbClassn_Mixed" 7 "AdbClassn_Unknown";
VAL_ 396 VehObjforADB5AdbClassnQly 0 "ClassnQly_Low" 1 "ClassnQly_Medium" 2 "ClassnQly_High";
VAL_ 396 VehObjforADB5AdbDetdQly 0 "ClassnQly_Low" 1 "ClassnQly_Medium" 2 "ClassnQly_High";
VAL_ 396 VehObjforADB5AdbObjDir 0 "AdbObjDir_Idle" 1 "AdbObjDir_Oncoming" 2 "AdbObjDir_Preceding" 3 "AdbObjDir_Others";
VAL_ 396 VehObjforADB5AdbTrkInfo 0 "NotTracked" 1 "Tracking";
VAL_ 397 VehObjforADB6AdbClassn 0 "AdbClassn_NoVehicle" 1 "AdbClassn_Car" 2 "AdbClassn_Truck" 3 "AdbClassn_Bus" 4 "AdbClassn_BikeOrMotorBike" 5 "AdbClassn_Pedestrain" 6 "AdbClassn_Mixed" 7 "AdbClassn_Unknown";
VAL_ 397 VehObjforADB6AdbClassnQly 0 "ClassnQly_Low" 1 "ClassnQly_Medium" 2 "ClassnQly_High";
VAL_ 397 VehObjforADB6AdbDetdQly 0 "ClassnQly_Low" 1 "ClassnQly_Medium" 2 "ClassnQly_High";
VAL_ 397 VehObjforADB6AdbObjDir 0 "AdbObjDir_Idle" 1 "AdbObjDir_Oncoming" 2 "AdbObjDir_Preceding" 3 "AdbObjDir_Others";
VAL_ 397 VehObjforADB6AdbTrkInfo 0 "NotTracked" 1 "Tracking";
VAL_ 398 VehObjforADB7AdbClassn 0 "AdbClassn_NoVehicle" 1 "AdbClassn_Car" 2 "AdbClassn_Truck" 3 "AdbClassn_Bus" 4 "AdbClassn_BikeOrMotorBike" 5 "AdbClassn_Pedestrain" 6 "AdbClassn_Mixed" 7 "AdbClassn_Unknown";
VAL_ 398 VehObjforADB7AdbClassnQly 0 "ClassnQly_Low" 1 "ClassnQly_Medium" 2 "ClassnQly_High";
VAL_ 398 VehObjforADB7AdbDetdQly 0 "ClassnQly_Low" 1 "ClassnQly_Medium" 2 "ClassnQly_High";
VAL_ 398 VehObjforADB7AdbObjDir 0 "AdbObjDir_Idle" 1 "AdbObjDir_Oncoming" 2 "AdbObjDir_Preceding" 3 "AdbObjDir_Others";
VAL_ 398 VehObjforADB7AdbTrkInfo 0 "NotTracked" 1 "Tracking";
VAL_ 399 VehObjforADB8AdbClassn 0 "AdbClassn_NoVehicle" 1 "AdbClassn_Car" 2 "AdbClassn_Truck" 3 "AdbClassn_Bus" 4 "AdbClassn_BikeOrMotorBike" 5 "AdbClassn_Pedestrain" 6 "AdbClassn_Mixed" 7 "AdbClassn_Unknown";
VAL_ 399 VehObjforADB8AdbClassnQly 0 "ClassnQly_Low" 1 "ClassnQly_Medium" 2 "ClassnQly_High";
VAL_ 399 VehObjforADB8AdbDetdQly 0 "ClassnQly_Low" 1 "ClassnQly_Medium" 2 "ClassnQly_High";
VAL_ 399 VehObjforADB8AdbObjDir 0 "AdbObjDir_Idle" 1 "AdbObjDir_Oncoming" 2 "AdbObjDir_Preceding" 3 "AdbObjDir_Others";
VAL_ 399 VehObjforADB8AdbTrkInfo 0 "NotTracked" 1 "Tracking";
VAL_ 64 CameraStsforAHBC 0 "AdbCamSts_Idle" 1 "AdbCamSts_Normal" 2 "AdbCamSts_Blocking" 3 "AdbCamSts_Unknown";
VAL_ 64 RainLi 0 "OnOff1_Off" 1 "OnOff1_On";
VAL_ 64 VehModMngtGlbSafe1CarModSts1 0 "CarModSts1_CarModNorm" 1 "CarModSts1_CarModTrnsp" 2 "CarModSts1_CarModFcy" 3 "CarModSts1_CarModCrash" 5 "CarModSts1_CarModDyno";
VAL_ 64 VehModMngtGlbSafe1FltEgyCnsWdSts 0 "FltEgyCns1_NoFlt" 1 "FltEgyCns1_Flt";
VAL_ 64 VehModMngtGlbSafe1UsgModSts 0 "UsgModSts1_UsgModAbdnd" 1 "UsgModSts1_UsgModInActv" 2 "UsgModSts1_UsgModCnvinc" 11 "UsgModSts1_UsgModActv" 13 "UsgModSts1_UsgModDrvg";
VAL_ 64 WipgAutFrntMod 0 "WipgAutFrntMod_Off" 1 "WipgAutFrntMod_ImdtMod" 2 "WipgAutFrntMod_IntlMod" 3 "WipgAutFrntMod_ContnsMod";
VAL_ 400 SuspPosnVertAgGenQf 0 "GenQf1_UndefindDataAccur" 1 "GenQf1_TmpUndefdData" 2 "GenQf1_DataAccurNotWithinSpcn" 3 "GenQf1_AccurData";
VAL_ 400 SuspPosnVertLvlFrntQf 0 "GenQf1_UndefindDataAccur" 1 "GenQf1_TmpUndefdData" 2 "GenQf1_DataAccurNotWithinSpcn" 3 "GenQf1_AccurData";
VAL_ 400 SuspPosnVertLvlReQf 0 "GenQf1_UndefindDataAccur" 1 "GenQf1_TmpUndefdData" 2 "GenQf1_DataAccurNotWithinSpcn" 3 "GenQf1_AccurData";
VAL_ 28 ExtrLiShowActvnReq 0 "OnOff1_Off" 1 "OnOff1_On";
VAL_ 28 ExtrLiShowFileTxReq 0 "OnOff1_Off" 1 "OnOff1_On";
VAL_ 288 DwnLoadDynLitPrmForLedStopLampRi2ModePrm 0 "Mode1_Off" 1 "Mode1_On" 2 "Mode1_GradualOn" 3 "Mode1_GradualOff" 4 "Mode1_ForwardWipingOn" 5 "Mode1_BackwardWipingOn" 6 "Mode1_OutwardWipingOn" 7 "Mode1_InwardWipingOn" 8 "Mode1_ForwardWipingOff" 9 "Mode1_BackwardWipingOff" 10 "Mode1_OutwardWipingOff" 11 "Mode1_InwardWipingOff" 12 "Mode1_ForwardScanning" 13 "Mode1_BackwardScanning" 14 "Mode1_BreathOn" 15 "Mode1_BreathOff" 16 "Mode1_Spare1" 17 "Mode1_Spare2";
VAL_ 289 DwnLoadDynLitPrmLedReFogLampRi2ModePrm 0 "Mode1_Off" 1 "Mode1_On" 2 "Mode1_GradualOn" 3 "Mode1_GradualOff" 4 "Mode1_ForwardWipingOn" 5 "Mode1_BackwardWipingOn" 6 "Mode1_OutwardWipingOn" 7 "Mode1_InwardWipingOn" 8 "Mode1_ForwardWipingOff" 9 "Mode1_BackwardWipingOff" 10 "Mode1_OutwardWipingOff" 11 "Mode1_InwardWipingOff" 12 "Mode1_ForwardScanning" 13 "Mode1_BackwardScanning" 14 "Mode1_BreathOn" 15 "Mode1_BreathOff" 16 "Mode1_Spare1" 17 "Mode1_Spare2";
VAL_ 290 DwnLoadDynLitPrmLedRePosnLampRi2ModePrm 0 "Mode1_Off" 1 "Mode1_On" 2 "Mode1_GradualOn" 3 "Mode1_GradualOff" 4 "Mode1_ForwardWipingOn" 5 "Mode1_BackwardWipingOn" 6 "Mode1_OutwardWipingOn" 7 "Mode1_InwardWipingOn" 8 "Mode1_ForwardWipingOff" 9 "Mode1_BackwardWipingOff" 10 "Mode1_OutwardWipingOff" 11 "Mode1_InwardWipingOff" 12 "Mode1_ForwardScanning" 13 "Mode1_BackwardScanning" 14 "Mode1_BreathOn" 15 "Mode1_BreathOff" 16 "Mode1_Spare1" 17 "Mode1_Spare2";
VAL_ 291 DwnLoadDynLitPrmLedReTurnIndcrRi2ModePrm 0 "Mode1_Off" 1 "Mode1_On" 2 "Mode1_GradualOn" 3 "Mode1_GradualOff" 4 "Mode1_ForwardWipingOn" 5 "Mode1_BackwardWipingOn" 6 "Mode1_OutwardWipingOn" 7 "Mode1_InwardWipingOn" 8 "Mode1_ForwardWipingOff" 9 "Mode1_BackwardWipingOff" 10 "Mode1_OutwardWipingOff" 11 "Mode1_InwardWipingOff" 12 "Mode1_ForwardScanning" 13 "Mode1_BackwardScanning" 14 "Mode1_BreathOn" 15 "Mode1_BreathOff" 16 "Mode1_Spare1" 17 "Mode1_Spare2";
VAL_ 292 DwnLoadDynLitPrmForLedMkrLampLe1ModePrm 0 "Mode1_Off" 1 "Mode1_On" 2 "Mode1_GradualOn" 3 "Mode1_GradualOff" 4 "Mode1_ForwardWipingOn" 5 "Mode1_BackwardWipingOn" 6 "Mode1_OutwardWipingOn" 7 "Mode1_InwardWipingOn" 8 "Mode1_ForwardWipingOff" 9 "Mode1_BackwardWipingOff" 10 "Mode1_OutwardWipingOff" 11 "Mode1_InwardWipingOff" 12 "Mode1_ForwardScanning" 13 "Mode1_BackwardScanning" 14 "Mode1_BreathOn" 15 "Mode1_BreathOff" 16 "Mode1_Spare1" 17 "Mode1_Spare2";
VAL_ 293 DwnLoadDynLtgPrmForLedLoBeamRiModePrm 0 "Mode1_Off" 1 "Mode1_On" 2 "Mode1_GradualOn" 3 "Mode1_GradualOff" 4 "Mode1_ForwardWipingOn" 5 "Mode1_BackwardWipingOn" 6 "Mode1_OutwardWipingOn" 7 "Mode1_InwardWipingOn" 8 "Mode1_ForwardWipingOff" 9 "Mode1_BackwardWipingOff" 10 "Mode1_OutwardWipingOff" 11 "Mode1_InwardWipingOff" 12 "Mode1_ForwardScanning" 13 "Mode1_BackwardScanning" 14 "Mode1_BreathOn" 15 "Mode1_BreathOff" 16 "Mode1_Spare1" 17 "Mode1_Spare2";
VAL_ 294 DwnLoadDynLitPrmForLedMkrLampLe2ModePrm 0 "Mode1_Off" 1 "Mode1_On" 2 "Mode1_GradualOn" 3 "Mode1_GradualOff" 4 "Mode1_ForwardWipingOn" 5 "Mode1_BackwardWipingOn" 6 "Mode1_OutwardWipingOn" 7 "Mode1_InwardWipingOn" 8 "Mode1_ForwardWipingOff" 9 "Mode1_BackwardWipingOff" 10 "Mode1_OutwardWipingOff" 11 "Mode1_InwardWipingOff" 12 "Mode1_ForwardScanning" 13 "Mode1_BackwardScanning" 14 "Mode1_BreathOn" 15 "Mode1_BreathOff" 16 "Mode1_Spare1" 17 "Mode1_Spare2";
VAL_ 295 DwnLoadDynLitPrmForLedMkrLampRi1ModePrm 0 "Mode1_Off" 1 "Mode1_On" 2 "Mode1_GradualOn" 3 "Mode1_GradualOff" 4 "Mode1_ForwardWipingOn" 5 "Mode1_BackwardWipingOn" 6 "Mode1_OutwardWipingOn" 7 "Mode1_InwardWipingOn" 8 "Mode1_ForwardWipingOff" 9 "Mode1_BackwardWipingOff" 10 "Mode1_OutwardWipingOff" 11 "Mode1_InwardWipingOff" 12 "Mode1_ForwardScanning" 13 "Mode1_BackwardScanning" 14 "Mode1_BreathOn" 15 "Mode1_BreathOff" 16 "Mode1_Spare1" 17 "Mode1_Spare2";
VAL_ 296 DwnLoadDynLitPrmForLedStopLampLe1ModePrm 0 "Mode1_Off" 1 "Mode1_On" 2 "Mode1_GradualOn" 3 "Mode1_GradualOff" 4 "Mode1_ForwardWipingOn" 5 "Mode1_BackwardWipingOn" 6 "Mode1_OutwardWipingOn" 7 "Mode1_InwardWipingOn" 8 "Mode1_ForwardWipingOff" 9 "Mode1_BackwardWipingOff" 10 "Mode1_OutwardWipingOff" 11 "Mode1_InwardWipingOff" 12 "Mode1_ForwardScanning" 13 "Mode1_BackwardScanning" 14 "Mode1_BreathOn" 15 "Mode1_BreathOff" 16 "Mode1_Spare1" 17 "Mode1_Spare2";
VAL_ 297 DwnLoadDynLitPrmForLedStopLampLe2ModePrm 0 "Mode1_Off" 1 "Mode1_On" 2 "Mode1_GradualOn" 3 "Mode1_GradualOff" 4 "Mode1_ForwardWipingOn" 5 "Mode1_BackwardWipingOn" 6 "Mode1_OutwardWipingOn" 7 "Mode1_InwardWipingOn" 8 "Mode1_ForwardWipingOff" 9 "Mode1_BackwardWipingOff" 10 "Mode1_OutwardWipingOff" 11 "Mode1_InwardWipingOff" 12 "Mode1_ForwardScanning" 13 "Mode1_BackwardScanning" 14 "Mode1_BreathOn" 15 "Mode1_BreathOff" 16 "Mode1_Spare1" 17 "Mode1_Spare2";
VAL_ 298 DwnLoadDynLitPrmForLedStopLampRi1ModePrm 0 "Mode1_Off" 1 "Mode1_On" 2 "Mode1_GradualOn" 3 "Mode1_GradualOff" 4 "Mode1_ForwardWipingOn" 5 "Mode1_BackwardWipingOn" 6 "Mode1_OutwardWipingOn" 7 "Mode1_InwardWipingOn" 8 "Mode1_ForwardWipingOff" 9 "Mode1_BackwardWipingOff" 10 "Mode1_OutwardWipingOff" 11 "Mode1_InwardWipingOff" 12 "Mode1_ForwardScanning" 13 "Mode1_BackwardScanning" 14 "Mode1_BreathOn" 15 "Mode1_BreathOff" 16 "Mode1_Spare1" 17 "Mode1_Spare2";
VAL_ 299 DwnLoadDynLitPrmLedReFogLampLe1ModePrm 0 "Mode1_Off" 1 "Mode1_On" 2 "Mode1_GradualOn" 3 "Mode1_GradualOff" 4 "Mode1_ForwardWipingOn" 5 "Mode1_BackwardWipingOn" 6 "Mode1_OutwardWipingOn" 7 "Mode1_InwardWipingOn" 8 "Mode1_ForwardWipingOff" 9 "Mode1_BackwardWipingOff" 10 "Mode1_OutwardWipingOff" 11 "Mode1_InwardWipingOff" 12 "Mode1_ForwardScanning" 13 "Mode1_BackwardScanning" 14 "Mode1_BreathOn" 15 "Mode1_BreathOff" 16 "Mode1_Spare1" 17 "Mode1_Spare2";
VAL_ 300 DwnLoadDynLitPrmLedReFogLampLe2ModePrm 0 "Mode1_Off" 1 "Mode1_On" 2 "Mode1_GradualOn" 3 "Mode1_GradualOff" 4 "Mode1_ForwardWipingOn" 5 "Mode1_BackwardWipingOn" 6 "Mode1_OutwardWipingOn" 7 "Mode1_InwardWipingOn" 8 "Mode1_ForwardWipingOff" 9 "Mode1_BackwardWipingOff" 10 "Mode1_OutwardWipingOff" 11 "Mode1_InwardWipingOff" 12 "Mode1_ForwardScanning" 13 "Mode1_BackwardScanning" 14 "Mode1_BreathOn" 15 "Mode1_BreathOff" 16 "Mode1_Spare1" 17 "Mode1_Spare2";
VAL_ 301 DwnLoadDynLitPrmLedReFogLampRi1ModePrm 0 "Mode1_Off" 1 "Mode1_On" 2 "Mode1_GradualOn" 3 "Mode1_GradualOff" 4 "Mode1_ForwardWipingOn" 5 "Mode1_BackwardWipingOn" 6 "Mode1_OutwardWipingOn" 7 "Mode1_InwardWipingOn" 8 "Mode1_ForwardWipingOff" 9 "Mode1_BackwardWipingOff" 10 "Mode1_OutwardWipingOff" 11 "Mode1_InwardWipingOff" 12 "Mode1_ForwardScanning" 13 "Mode1_BackwardScanning" 14 "Mode1_BreathOn" 15 "Mode1_BreathOff" 16 "Mode1_Spare1" 17 "Mode1_Spare2";
VAL_ 302 DwnLoadDynLitPrmLedRePosnLampLe1ModePrm 0 "Mode1_Off" 1 "Mode1_On" 2 "Mode1_GradualOn" 3 "Mode1_GradualOff" 4 "Mode1_ForwardWipingOn" 5 "Mode1_BackwardWipingOn" 6 "Mode1_OutwardWipingOn" 7 "Mode1_InwardWipingOn" 8 "Mode1_ForwardWipingOff" 9 "Mode1_BackwardWipingOff" 10 "Mode1_OutwardWipingOff" 11 "Mode1_InwardWipingOff" 12 "Mode1_ForwardScanning" 13 "Mode1_BackwardScanning" 14 "Mode1_BreathOn" 15 "Mode1_BreathOff" 16 "Mode1_Spare1" 17 "Mode1_Spare2";
VAL_ 303 DwnLoadDynLitPrmLedRePosnLampLe2ModePrm 0 "Mode1_Off" 1 "Mode1_On" 2 "Mode1_GradualOn" 3 "Mode1_GradualOff" 4 "Mode1_ForwardWipingOn" 5 "Mode1_BackwardWipingOn" 6 "Mode1_OutwardWipingOn" 7 "Mode1_InwardWipingOn" 8 "Mode1_ForwardWipingOff" 9 "Mode1_BackwardWipingOff" 10 "Mode1_OutwardWipingOff" 11 "Mode1_InwardWipingOff" 12 "Mode1_ForwardScanning" 13 "Mode1_BackwardScanning" 14 "Mode1_BreathOn" 15 "Mode1_BreathOff" 16 "Mode1_Spare1" 17 "Mode1_Spare2";
VAL_ 304 DwnLoadDynLitPrmLedRePosnLampRi1ModePrm 0 "Mode1_Off" 1 "Mode1_On" 2 "Mode1_GradualOn" 3 "Mode1_GradualOff" 4 "Mode1_ForwardWipingOn" 5 "Mode1_BackwardWipingOn" 6 "Mode1_OutwardWipingOn" 7 "Mode1_InwardWipingOn" 8 "Mode1_ForwardWipingOff" 9 "Mode1_BackwardWipingOff" 10 "Mode1_OutwardWipingOff" 11 "Mode1_InwardWipingOff" 12 "Mode1_ForwardScanning" 13 "Mode1_BackwardScanning" 14 "Mode1_BreathOn" 15 "Mode1_BreathOff" 16 "Mode1_Spare1" 17 "Mode1_Spare2";
VAL_ 305 DwnLoadDynLitPrmLedReTurnIndcrLe1ModePrm 0 "Mode1_Off" 1 "Mode1_On" 2 "Mode1_GradualOn" 3 "Mode1_GradualOff" 4 "Mode1_ForwardWipingOn" 5 "Mode1_BackwardWipingOn" 6 "Mode1_OutwardWipingOn" 7 "Mode1_InwardWipingOn" 8 "Mode1_ForwardWipingOff" 9 "Mode1_BackwardWipingOff" 10 "Mode1_OutwardWipingOff" 11 "Mode1_InwardWipingOff" 12 "Mode1_ForwardScanning" 13 "Mode1_BackwardScanning" 14 "Mode1_BreathOn" 15 "Mode1_BreathOff" 16 "Mode1_Spare1" 17 "Mode1_Spare2";
VAL_ 306 DwnLoadDynLitPrmLedReTurnIndcrLe2ModePrm 0 "Mode1_Off" 1 "Mode1_On" 2 "Mode1_GradualOn" 3 "Mode1_GradualOff" 4 "Mode1_ForwardWipingOn" 5 "Mode1_BackwardWipingOn" 6 "Mode1_OutwardWipingOn" 7 "Mode1_InwardWipingOn" 8 "Mode1_ForwardWipingOff" 9 "Mode1_BackwardWipingOff" 10 "Mode1_OutwardWipingOff" 11 "Mode1_InwardWipingOff" 12 "Mode1_ForwardScanning" 13 "Mode1_BackwardScanning" 14 "Mode1_BreathOn" 15 "Mode1_BreathOff" 16 "Mode1_Spare1" 17 "Mode1_Spare2";
VAL_ 307 DwnLoadDynLitPrmLedReTurnIndcrRi1ModePrm 0 "Mode1_Off" 1 "Mode1_On" 2 "Mode1_GradualOn" 3 "Mode1_GradualOff" 4 "Mode1_ForwardWipingOn" 5 "Mode1_BackwardWipingOn" 6 "Mode1_OutwardWipingOn" 7 "Mode1_InwardWipingOn" 8 "Mode1_ForwardWipingOff" 9 "Mode1_BackwardWipingOff" 10 "Mode1_OutwardWipingOff" 11 "Mode1_InwardWipingOff" 12 "Mode1_ForwardScanning" 13 "Mode1_BackwardScanning" 14 "Mode1_BreathOn" 15 "Mode1_BreathOff" 16 "Mode1_Spare1" 17 "Mode1_Spare2";
VAL_ 308 DwnLoadDynLitPrmLedRvsgLampLe1ModePrm 0 "Mode1_Off" 1 "Mode1_On" 2 "Mode1_GradualOn" 3 "Mode1_GradualOff" 4 "Mode1_ForwardWipingOn" 5 "Mode1_BackwardWipingOn" 6 "Mode1_OutwardWipingOn" 7 "Mode1_InwardWipingOn" 8 "Mode1_ForwardWipingOff" 9 "Mode1_BackwardWipingOff" 10 "Mode1_OutwardWipingOff" 11 "Mode1_InwardWipingOff" 12 "Mode1_ForwardScanning" 13 "Mode1_BackwardScanning" 14 "Mode1_BreathOn" 15 "Mode1_BreathOff" 16 "Mode1_Spare1" 17 "Mode1_Spare2";
VAL_ 309 DwnLoadDynLitPrmLedRvsgLampLe2ModePrm 0 "Mode1_Off" 1 "Mode1_On" 2 "Mode1_GradualOn" 3 "Mode1_GradualOff" 4 "Mode1_ForwardWipingOn" 5 "Mode1_BackwardWipingOn" 6 "Mode1_OutwardWipingOn" 7 "Mode1_InwardWipingOn" 8 "Mode1_ForwardWipingOff" 9 "Mode1_BackwardWipingOff" 10 "Mode1_OutwardWipingOff" 11 "Mode1_InwardWipingOff" 12 "Mode1_ForwardScanning" 13 "Mode1_BackwardScanning" 14 "Mode1_BreathOn" 15 "Mode1_BreathOff" 16 "Mode1_Spare1" 17 "Mode1_Spare2";
VAL_ 310 DwnLoadDynLitPrmLedRvsgLampRi1ModePrm 0 "Mode1_Off" 1 "Mode1_On" 2 "Mode1_GradualOn" 3 "Mode1_GradualOff" 4 "Mode1_ForwardWipingOn" 5 "Mode1_BackwardWipingOn" 6 "Mode1_OutwardWipingOn" 7 "Mode1_InwardWipingOn" 8 "Mode1_ForwardWipingOff" 9 "Mode1_BackwardWipingOff" 10 "Mode1_OutwardWipingOff" 11 "Mode1_InwardWipingOff" 12 "Mode1_ForwardScanning" 13 "Mode1_BackwardScanning" 14 "Mode1_BreathOn" 15 "Mode1_BreathOff" 16 "Mode1_Spare1" 17 "Mode1_Spare2";
VAL_ 120 ActvnOfReLogoLamp 0 "OnOff1_Off" 1 "OnOff1_On";
VAL_ 120 LvlgSwtSetReqADModCtrlInhbn 0 "NoInhb" 1 "L12LgtCtrlModInhb" 2 "AutoParkingModInhb" 3 "L12AndAutoParkingModInhb" 4 "L3ADModInhb" 5 "L3ADAndL12LgtCtrlModInhb" 6 "L3ADAndAutoParkingModInhb" 7 "L3ADAndAutoParkingAndL12LgtCtrlModInhb";
VAL_ 120 OutdBriSts 0 "OutdBriSts_Ukwn" 1 "OutdBriSts_Night" 2 "OutdBriSts_Day" 3 "OutdBriSts_Invld";
VAL_ 311 DwnLoadDynLitPrmForLedHiBeamLeModePrm 0 "Mode1_Off" 1 "Mode1_On" 2 "Mode1_GradualOn" 3 "Mode1_GradualOff" 4 "Mode1_ForwardWipingOn" 5 "Mode1_BackwardWipingOn" 6 "Mode1_OutwardWipingOn" 7 "Mode1_InwardWipingOn" 8 "Mode1_ForwardWipingOff" 9 "Mode1_BackwardWipingOff" 10 "Mode1_OutwardWipingOff" 11 "Mode1_InwardWipingOff" 12 "Mode1_ForwardScanning" 13 "Mode1_BackwardScanning" 14 "Mode1_BreathOn" 15 "Mode1_BreathOff" 16 "Mode1_Spare1" 17 "Mode1_Spare2";
SIG_GROUP_ 128 AccrPedlRat 1 : AccrPedlRatAccrPedlRat AccrPedlRatChks AccrPedlRatCntr;
SIG_GROUP_ 128 AmbTRaw 1 : AmbTRawAmbTVal AmbTRawQly;
SIG_GROUP_ 128 BrkPedlSnsr 1 : BrkPedlSnsrChks BrkPedlSnsrCntr BrkPedlSnsrQf BrkPedlSnsrSt;
SIG_GROUP_ 1431 CEMdevelpsignalgroupcheck 1 : CEMdevelpsignalgroupcheckFunctiondevpsignalgroup1 CEMdevelpsignalgroupcheckFunctiondevpsignalgroup2 CEMdevelpsignalgroupcheckFunctiondevpsignalgroup3 CEMdevelpsignalgroupcheckFunctiondevpsignalgroup4 CEMdevelpsignalgroupcheckFunctiondevpsignalgroup5 CEMdevelpsignalgroupcheckFunctiondevpsignalgroup6 CEMdevelpsignalgroupcheckFunctiondevpsignalgroup7 CEMdevelpsignalgroupcheckFunctiondevpsignalgroup8;
SIG_GROUP_ 1432 CEMdevelpsignalgroupresp 1 : CEMdevelpsignalgrouprespFunctiondevpsignalgroup1 CEMdevelpsignalgrouprespFunctiondevpsignalgroup2 CEMdevelpsignalgrouprespFunctiondevpsignalgroup3 CEMdevelpsignalgrouprespFunctiondevpsignalgroup4 CEMdevelpsignalgrouprespFunctiondevpsignalgroup5 CEMdevelpsignalgrouprespFunctiondevpsignalgroup6 CEMdevelpsignalgrouprespFunctiondevpsignalgroup7 CEMdevelpsignalgrouprespFunctiondevpsignalgroup8;
SIG_GROUP_ 311 DwnLoadDynLitPrmForLedHiBeamLe 1 : DwnLoadDynLitPrmForLedHiBeamLeContTiPrm DwnLoadDynLitPrmForLedHiBeamLeLowBriPrm DwnLoadDynLitPrmForLedHiBeamLeModePrm DwnLoadDynLitPrmForLedHiBeamLeOffsTiPrm DwnLoadDynLitPrmForLedHiBeamLeTistamp DwnLoadDynLitPrmForLedHiBeamLeUpprBriPrm;
SIG_GROUP_ 292 DwnLoadDynLitPrmForLedMkrLampLe1 1 : DwnLoadDynLitPrmForLedMkrLampLe1ContTiPrm DwnLoadDynLitPrmForLedMkrLampLe1LowBriPrm DwnLoadDynLitPrmForLedMkrLampLe1ModePrm DwnLoadDynLitPrmForLedMkrLampLe1OffsTiPrm DwnLoadDynLitPrmForLedMkrLampLe1Tistamp DwnLoadDynLitPrmForLedMkrLampLe1UpprBriPrm;
SIG_GROUP_ 294 DwnLoadDynLitPrmForLedMkrLampLe2 1 : DwnLoadDynLitPrmForLedMkrLampLe2ContTiPrm DwnLoadDynLitPrmForLedMkrLampLe2LowBriPrm DwnLoadDynLitPrmForLedMkrLampLe2ModePrm DwnLoadDynLitPrmForLedMkrLampLe2OffsTiPrm DwnLoadDynLitPrmForLedMkrLampLe2Tistamp DwnLoadDynLitPrmForLedMkrLampLe2UpprBriPrm;
SIG_GROUP_ 295 DwnLoadDynLitPrmForLedMkrLampRi1 1 : DwnLoadDynLitPrmForLedMkrLampRi1ContTiPrm DwnLoadDynLitPrmForLedMkrLampRi1LowBriPrm DwnLoadDynLitPrmForLedMkrLampRi1ModePrm DwnLoadDynLitPrmForLedMkrLampRi1OffsTiPrm DwnLoadDynLitPrmForLedMkrLampRi1Tistamp DwnLoadDynLitPrmForLedMkrLampRi1UpprBriPrm;
SIG_GROUP_ 296 DwnLoadDynLitPrmForLedStopLampLe1 1 : DwnLoadDynLitPrmForLedStopLampLe1ContTiPrm DwnLoadDynLitPrmForLedStopLampLe1LowBriPrm DwnLoadDynLitPrmForLedStopLampLe1ModePrm DwnLoadDynLitPrmForLedStopLampLe1OffsTiPrm DwnLoadDynLitPrmForLedStopLampLe1Tistamp DwnLoadDynLitPrmForLedStopLampLe1UpprBriPrm;
SIG_GROUP_ 297 DwnLoadDynLitPrmForLedStopLampLe2 1 : DwnLoadDynLitPrmForLedStopLampLe2ContTiPrm DwnLoadDynLitPrmForLedStopLampLe2LowBriPrm DwnLoadDynLitPrmForLedStopLampLe2ModePrm DwnLoadDynLitPrmForLedStopLampLe2OffsTiPrm DwnLoadDynLitPrmForLedStopLampLe2Tistamp DwnLoadDynLitPrmForLedStopLampLe2UpprBriPrm;
SIG_GROUP_ 298 DwnLoadDynLitPrmForLedStopLampRi1 1 : DwnLoadDynLitPrmForLedStopLampRi1ContTiPrm DwnLoadDynLitPrmForLedStopLampRi1LowBriPrm DwnLoadDynLitPrmForLedStopLampRi1ModePrm DwnLoadDynLitPrmForLedStopLampRi1OffsTiPrm DwnLoadDynLitPrmForLedStopLampRi1Tistamp DwnLoadDynLitPrmForLedStopLampRi1UpprBriPrm;
SIG_GROUP_ 288 DwnLoadDynLitPrmForLedStopLampRi2 1 : DwnLoadDynLitPrmForLedStopLampRi2ContTiPrm DwnLoadDynLitPrmForLedStopLampRi2LowBriPrm DwnLoadDynLitPrmForLedStopLampRi2ModePrm DwnLoadDynLitPrmForLedStopLampRi2OffsTiPrm DwnLoadDynLitPrmForLedStopLampRi2Tistamp DwnLoadDynLitPrmForLedStopLampRi2UpprBriPrm;
SIG_GROUP_ 299 DwnLoadDynLitPrmLedReFogLampLe1 1 : DwnLoadDynLitPrmLedReFogLampLe1ContTiPrm DwnLoadDynLitPrmLedReFogLampLe1LowBriPrm DwnLoadDynLitPrmLedReFogLampLe1ModePrm DwnLoadDynLitPrmLedReFogLampLe1OffsTiPrm DwnLoadDynLitPrmLedReFogLampLe1Tistamp DwnLoadDynLitPrmLedReFogLampLe1UpprBriPrm;
SIG_GROUP_ 300 DwnLoadDynLitPrmLedReFogLampLe2 1 : DwnLoadDynLitPrmLedReFogLampLe2ContTiPrm DwnLoadDynLitPrmLedReFogLampLe2LowBriPrm DwnLoadDynLitPrmLedReFogLampLe2ModePrm DwnLoadDynLitPrmLedReFogLampLe2OffsTiPrm DwnLoadDynLitPrmLedReFogLampLe2Tistamp DwnLoadDynLitPrmLedReFogLampLe2UpprBriPrm;
SIG_GROUP_ 301 DwnLoadDynLitPrmLedReFogLampRi1 1 : DwnLoadDynLitPrmLedReFogLampRi1ContTiPrm DwnLoadDynLitPrmLedReFogLampRi1LowBriPrm DwnLoadDynLitPrmLedReFogLampRi1ModePrm DwnLoadDynLitPrmLedReFogLampRi1OffsTiPrm DwnLoadDynLitPrmLedReFogLampRi1Tistamp DwnLoadDynLitPrmLedReFogLampRi1UpprBriPrm;
SIG_GROUP_ 289 DwnLoadDynLitPrmLedReFogLampRi2 1 : DwnLoadDynLitPrmLedReFogLampRi2ContTiPrm DwnLoadDynLitPrmLedReFogLampRi2LowBriPrm DwnLoadDynLitPrmLedReFogLampRi2ModePrm DwnLoadDynLitPrmLedReFogLampRi2OffsTiPrm DwnLoadDynLitPrmLedReFogLampRi2Tistamp DwnLoadDynLitPrmLedReFogLampRi2UpprBriPrm;
SIG_GROUP_ 302 DwnLoadDynLitPrmLedRePosnLampLe1 1 : DwnLoadDynLitPrmLedRePosnLampLe1ContTiPrm DwnLoadDynLitPrmLedRePosnLampLe1LowBriPrm DwnLoadDynLitPrmLedRePosnLampLe1ModePrm DwnLoadDynLitPrmLedRePosnLampLe1OffsTiPrm DwnLoadDynLitPrmLedRePosnLampLe1Tistamp DwnLoadDynLitPrmLedRePosnLampLe1UpprBriPrm;
SIG_GROUP_ 303 DwnLoadDynLitPrmLedRePosnLampLe2 1 : DwnLoadDynLitPrmLedRePosnLampLe2ContTiPrm DwnLoadDynLitPrmLedRePosnLampLe2LowBriPrm DwnLoadDynLitPrmLedRePosnLampLe2ModePrm DwnLoadDynLitPrmLedRePosnLampLe2OffsTiPrm DwnLoadDynLitPrmLedRePosnLampLe2Tistamp DwnLoadDynLitPrmLedRePosnLampLe2UpprBriPrm;
SIG_GROUP_ 304 DwnLoadDynLitPrmLedRePosnLampRi1 1 : DwnLoadDynLitPrmLedRePosnLampRi1ContTiPrm DwnLoadDynLitPrmLedRePosnLampRi1LowBriPrm DwnLoadDynLitPrmLedRePosnLampRi1ModePrm DwnLoadDynLitPrmLedRePosnLampRi1OffsTiPrm DwnLoadDynLitPrmLedRePosnLampRi1Tistamp DwnLoadDynLitPrmLedRePosnLampRi1UpprBriPrm;
SIG_GROUP_ 290 DwnLoadDynLitPrmLedRePosnLampRi2 1 : DwnLoadDynLitPrmLedRePosnLampRi2ContTiPrm DwnLoadDynLitPrmLedRePosnLampRi2LowBriPrm DwnLoadDynLitPrmLedRePosnLampRi2ModePrm DwnLoadDynLitPrmLedRePosnLampRi2OffsTiPrm DwnLoadDynLitPrmLedRePosnLampRi2Tistamp DwnLoadDynLitPrmLedRePosnLampRi2UpprBriPrm;
SIG_GROUP_ 305 DwnLoadDynLitPrmLedReTurnIndcrLe1 1 : DwnLoadDynLitPrmLedReTurnIndcrLe1ContTiPrm DwnLoadDynLitPrmLedReTurnIndcrLe1LowBriPrm DwnLoadDynLitPrmLedReTurnIndcrLe1ModePrm DwnLoadDynLitPrmLedReTurnIndcrLe1OffsTiPrm DwnLoadDynLitPrmLedReTurnIndcrLe1Tistamp DwnLoadDynLitPrmLedReTurnIndcrLe1UpprBriPrm;
SIG_GROUP_ 306 DwnLoadDynLitPrmLedReTurnIndcrLe2 1 : DwnLoadDynLitPrmLedReTurnIndcrLe2ContTiPrm DwnLoadDynLitPrmLedReTurnIndcrLe2LowBriPrm DwnLoadDynLitPrmLedReTurnIndcrLe2ModePrm DwnLoadDynLitPrmLedReTurnIndcrLe2OffsTiPrm DwnLoadDynLitPrmLedReTurnIndcrLe2Tistamp DwnLoadDynLitPrmLedReTurnIndcrLe2UpprBriPrm;
SIG_GROUP_ 307 DwnLoadDynLitPrmLedReTurnIndcrRi1 1 : DwnLoadDynLitPrmLedReTurnIndcrRi1ContTiPrm DwnLoadDynLitPrmLedReTurnIndcrRi1LowBriPrm DwnLoadDynLitPrmLedReTurnIndcrRi1ModePrm DwnLoadDynLitPrmLedReTurnIndcrRi1OffsTiPrm DwnLoadDynLitPrmLedReTurnIndcrRi1Tistamp DwnLoadDynLitPrmLedReTurnIndcrRi1UpprBriPrm;
SIG_GROUP_ 291 DwnLoadDynLitPrmLedReTurnIndcrRi2 1 : DwnLoadDynLitPrmLedReTurnIndcrRi2ContTiPrm DwnLoadDynLitPrmLedReTurnIndcrRi2LowBriPrm DwnLoadDynLitPrmLedReTurnIndcrRi2ModePrm DwnLoadDynLitPrmLedReTurnIndcrRi2OffsTiPrm DwnLoadDynLitPrmLedReTurnIndcrRi2Tistamp DwnLoadDynLitPrmLedReTurnIndcrRi2UpprBriPrm;
SIG_GROUP_ 308 DwnLoadDynLitPrmLedRvsgLampLe1 1 : DwnLoadDynLitPrmLedRvsgLampLe1ContTiPrm DwnLoadDynLitPrmLedRvsgLampLe1LowBriPrm DwnLoadDynLitPrmLedRvsgLampLe1ModePrm DwnLoadDynLitPrmLedRvsgLampLe1OffsTiPrm DwnLoadDynLitPrmLedRvsgLampLe1Tistamp DwnLoadDynLitPrmLedRvsgLampLe1UpprBriPrm;
SIG_GROUP_ 309 DwnLoadDynLitPrmLedRvsgLampLe2 1 : DwnLoadDynLitPrmLedRvsgLampLe2ContTiPrm DwnLoadDynLitPrmLedRvsgLampLe2LowBriPrm DwnLoadDynLitPrmLedRvsgLampLe2ModePrm DwnLoadDynLitPrmLedRvsgLampLe2OffsTiPrm DwnLoadDynLitPrmLedRvsgLampLe2Tistamp DwnLoadDynLitPrmLedRvsgLampLe2UpprBriPrm;
SIG_GROUP_ 310 DwnLoadDynLitPrmLedRvsgLampRi1 1 : DwnLoadDynLitPrmLedRvsgLampRi1ContTiPrm DwnLoadDynLitPrmLedRvsgLampRi1LowBriPrm DwnLoadDynLitPrmLedRvsgLampRi1ModePrm DwnLoadDynLitPrmLedRvsgLampRi1OffsTiPrm DwnLoadDynLitPrmLedRvsgLampRi1Tistamp DwnLoadDynLitPrmLedRvsgLampRi1UpprBriPrm;
SIG_GROUP_ 293 DwnLoadDynLtgPrmForLedLoBeamRi 1 : DwnLoadDynLtgPrmForLedLoBeamRiContTiPrm DwnLoadDynLtgPrmForLedLoBeamRiLowBriPrm DwnLoadDynLtgPrmForLedLoBeamRiModePrm DwnLoadDynLtgPrmForLedLoBeamRiOffsTiPrm DwnLoadDynLtgPrmForLedLoBeamRiTistamp DwnLoadDynLtgPrmForLedLoBeamRiUpprBriPrm;
SIG_GROUP_ 120 LvlgSwtSetReq 1 : LvlgSwtSetReqADModCtrlInhbn LvlgSwtSetReqChks LvlgSwtSetReqCntr;
SIG_GROUP_ 120 OutdBri 1 : OutdBriChks OutdBriCntr OutdBriSts;
SIG_GROUP_ 82 SteerWhlSnsr 1 : SteerWhlSnsrAg SteerWhlSnsrAgSpd SteerWhlSnsrChks SteerWhlSnsrCntr SteerWhlSnsrQf;
SIG_GROUP_ 400 SuspPosnVertAg 1 : SuspPosnVertAgGenQf SuspPosnVertAgSuspPosnVertAg;
SIG_GROUP_ 400 SuspPosnVertLvl 1 : SuspPosnVertLvlFrnt SuspPosnVertLvlFrntQf SuspPosnVertLvlRe SuspPosnVertLvlReQf;
SIG_GROUP_ 389 TrafficSignForADB1 1 : TrafficSignForADB1AdbAbsDist TrafficSignForADB1AdbDetdQly TrafficSignForADB1AdbHozlAg TrafficSignForADB1AdbObjHozlAgSpd TrafficSignForADB1AdbObjVertAgSpd TrafficSignForADB1AdbTrkInfo TrafficSignForADB1AdbVertAg;
SIG_GROUP_ 390 TrafficSignForADB2 1 : TrafficSignForADB2AdbAbsDist TrafficSignForADB2AdbDetdQly TrafficSignForADB2AdbHozlAg TrafficSignForADB2AdbObjHozlAgSpd TrafficSignForADB2AdbObjVertAgSpd TrafficSignForADB2AdbTrkInfo TrafficSignForADB2AdbVertAg;
SIG_GROUP_ 512 VehBattU 1 : VehBattUSysU VehBattUSysUQf;
SIG_GROUP_ 384 VehCfgPrm 1 : VehCfgPrmBlkIDBytePosn1 VehCfgPrmCCPBytePosn2 VehCfgPrmCCPBytePosn3 VehCfgPrmCCPBytePosn4 VehCfgPrmCCPBytePosn5 VehCfgPrmCCPBytePosn6 VehCfgPrmCCPBytePosn7 VehCfgPrmCCPBytePosn8;
SIG_GROUP_ 387 VehCfgPrmExt 1 : VehCfgPrmExtBlkIDBytePosn1 VehCfgPrmExtCCPBytePosn2 VehCfgPrmExtCCPBytePosn3 VehCfgPrmExtCCPBytePosn4 VehCfgPrmExtCCPBytePosn5 VehCfgPrmExtCCPBytePosn6 VehCfgPrmExtCCPBytePosn7 VehCfgPrmExtCCPBytePosn8;
SIG_GROUP_ 64 VehModMngtGlbSafe1 1 : VehModMngtGlbSafe1CarModSts1 VehModMngtGlbSafe1CarModSubtypWdCarModSubtyp VehModMngtGlbSafe1Chks VehModMngtGlbSafe1Cntr VehModMngtGlbSafe1EgyLvlElecMai VehModMngtGlbSafe1EgyLvlElecSubtyp VehModMngtGlbSafe1FltEgyCnsWdSts VehModMngtGlbSafe1PwrLvlElecMai VehModMngtGlbSafe1PwrLvlElecSubtyp VehModMngtGlbSafe1UsgModSts;
SIG_GROUP_ 392 VehObjforADB1 1 : VehObjforADB1AdbAbsDist VehObjforADB1AdbClassn VehObjforADB1AdbClassnQly VehObjforADB1AdbDetdQly VehObjforADB1AdbHozlAg VehObjforADB1AdbObjDir VehObjforADB1AdbObjHozlAgSpd VehObjforADB1AdbObjVertAgSpd VehObjforADB1AdbTrkInfo VehObjforADB1AdbVertAg;
SIG_GROUP_ 393 VehObjforADB2 1 : VehObjforADB2AdbAbsDist VehObjforADB2AdbClassn VehObjforADB2AdbClassnQly VehObjforADB2AdbDetdQly VehObjforADB2AdbHozlAg VehObjforADB2AdbObjDir VehObjforADB2AdbObjHozlAgSpd VehObjforADB2AdbObjVertAgSpd VehObjforADB2AdbTrkInfo VehObjforADB2AdbVertAg;
SIG_GROUP_ 394 VehObjforADB3 1 : VehObjforADB3AdbAbsDist VehObjforADB3AdbClassn VehObjforADB3AdbClassnQly VehObjforADB3AdbDetdQly VehObjforADB3AdbHozlAg VehObjforADB3AdbObjDir VehObjforADB3AdbObjHozlAgSpd VehObjforADB3AdbObjVertAgSpd VehObjforADB3AdbTrkInfo VehObjforADB3AdbVertAg;
SIG_GROUP_ 395 VehObjforADB4 1 : VehObjforADB4AdbAbsDist VehObjforADB4AdbClassn VehObjforADB4AdbClassnQly VehObjforADB4AdbDetdQly VehObjforADB4AdbHozlAg VehObjforADB4AdbObjDir VehObjforADB4AdbObjHozlAgSpd VehObjforADB4AdbObjVertAgSpd VehObjforADB4AdbTrkInfo VehObjforADB4AdbVertAg;
SIG_GROUP_ 396 VehObjforADB5 1 : VehObjforADB5AdbAbsDist VehObjforADB5AdbClassn VehObjforADB5AdbClassnQly VehObjforADB5AdbDetdQly VehObjforADB5AdbHozlAg VehObjforADB5AdbObjDir VehObjforADB5AdbObjHozlAgSpd VehObjforADB5AdbObjVertAgSpd VehObjforADB5AdbTrkInfo VehObjforADB5AdbVertAg;
SIG_GROUP_ 397 VehObjforADB6 1 : VehObjforADB6AdbAbsDist VehObjforADB6AdbClassn VehObjforADB6AdbClassnQly VehObjforADB6AdbDetdQly VehObjforADB6AdbHozlAg VehObjforADB6AdbObjDir VehObjforADB6AdbObjHozlAgSpd VehObjforADB6AdbObjVertAgSpd VehObjforADB6AdbTrkInfo VehObjforADB6AdbVertAg;
SIG_GROUP_ 398 VehObjforADB7 1 : VehObjforADB7AdbAbsDist VehObjforADB7AdbClassn VehObjforADB7AdbClassnQly VehObjforADB7AdbDetdQly VehObjforADB7AdbHozlAg VehObjforADB7AdbObjDir VehObjforADB7AdbObjHozlAgSpd VehObjforADB7AdbObjVertAgSpd VehObjforADB7AdbTrkInfo VehObjforADB7AdbVertAg;
SIG_GROUP_ 399 VehObjforADB8 1 : VehObjforADB8AdbAbsDist VehObjforADB8AdbClassn VehObjforADB8AdbClassnQly VehObjforADB8AdbDetdQly VehObjforADB8AdbHozlAg VehObjforADB8AdbObjDir VehObjforADB8AdbObjHozlAgSpd VehObjforADB8AdbObjVertAgSpd VehObjforADB8AdbTrkInfo VehObjforADB8AdbVertAg;
SIG_GROUP_ 391 VehObjforAHB 1 : VehObjforAHBAdbAbsDist VehObjforAHBAdbClassn VehObjforAHBAdbClassnQly VehObjforAHBAdbDetdQly VehObjforAHBAdbHozlAg VehObjforAHBAdbObjDir VehObjforAHBAdbObjHozlAgSpd VehObjforAHBAdbObjVertAgSpd VehObjforAHBAdbTrkInfo VehObjforAHBAdbVertAg;
SIG_GROUP_ 80 VehSpdLgt 1 : VehSpdLgtA VehSpdLgtChks VehSpdLgtCntr VehSpdLgtQf;
